VERSION ""

NS_ :

BS_:

BU_: VCU_LE CHUD_LE VKM_LE RCRM_LE VPM_LE EDI_LE V2V_LE TCP_LE CSM_LE UHP_Low_LE TouchPad_LE RSE_LE RSC_LE RSA_LE PDIM_LE OTIM_LE ICS_LE LVMPC_LE LVMNav_LE DVB_T_LE ONSTAR_LE HUD_LE IPC_LE RadioHead_LE CHM_LE Dummy_LE CGM_LE AMP_LE

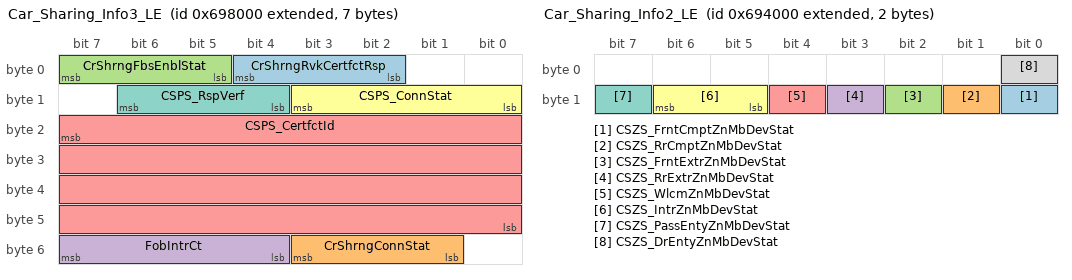
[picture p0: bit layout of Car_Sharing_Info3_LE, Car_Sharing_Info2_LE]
BO_ 2154397696 Car_Sharing_Info3_LE: 7 CGM_LE
 SG_ CrShrngRvkCertfctRsp : 4|3@0+ (1,0) [0|7] ""  TCP_LE,ONSTAR_LE
 SG_ CrShrngConnStat : 51|3@0+ (1,0) [0|7] ""  VKM_LE
 SG_ CrShrngFbsEnblStat : 7|3@0+ (1,0) [0|7] ""  VKM_LE,TCP_LE,ONSTAR_LE
 SG_ FobIntrCt : 55|4@0+ (1,0) [0|15] ""  TCP_LE,ONSTAR_LE
 SG_ CSPS_CertfctId : 23|32@0+ (1,0) [0|4294967295] ""  VKM_LE
 SG_ CSPS_ConnStat : 11|4@0+ (1,0) [0|15] ""  VKM_LE
 SG_ CSPS_RspVerf : 14|3@0+ (1,0) [0|7] ""  VKM_LE

BO_ 2154553344 Car_sharing_Encrypt_Secrt_Rsp_LE: 8 VKM_LE
 SG_ CrShrngEncrpScrtRsp : 7|64@0+ (1,0) [0|1.84467440737096E+019] ""  CGM_LE

BO_ 2154536960 Car_sharing_Encrypt_Secret_LE: 8 CGM_LE
 SG_ CrShrngEncrpScrt : 7|64@0+ (1,0) [0|1.84467440737096E+019] ""  VKM_LE

BO_ 2154545152 Car_Shar_Intrmdt_CA_Cert_Rsp_LE: 8 CGM_LE
 SG_ CrShrgIntCtftAthrtyCtftRp : 7|64@0+ (1,0) [0|1.84467440737096E+019] ""  VKM_LE

BO_ 2154520576 Car_Sharing_Intrmdt_CA_Cert_LE: 8 VKM_LE
 SG_ CrShrgIntCtftAthrtyCtft : 7|64@0+ (1,0) [0|1.84467440737096E+019] ""  CGM_LE

BO_ 2154504192 Car_Sharing_User_Cert_Resp_LE: 8 CGM_LE
 SG_ CrShrngUsrCertfctRsp : 7|64@0+ (1,0) [0|1.84467440737096E+019] ""  VKM_LE

BO_ 2154479616 Car_Sharing_User_Cert_LE: 8 VKM_LE
 SG_ CrShrngUsrCertfct : 7|64@0+ (1,0) [0|1.84467440737096E+019] ""  CGM_LE

BO_ 2154381312 Car_Sharing_Info2_LE: 2 VKM_LE
 SG_ CSZS_FrntCmptZnMbDevStat : 8|1@0+ (1,0) [0|1] ""  CGM_LE
 SG_ CSZS_RrCmptZnMbDevStat : 9|1@0+ (1,0) [0|1] ""  CGM_LE
 SG_ CSZS_FrntExtrZnMbDevStat : 10|1@0+ (1,0) [0|1] ""  CGM_LE
 SG_ CSZS_RrExtrZnMbDevStat : 11|1@0+ (1,0) [0|1] ""  CGM_LE
 SG_ CSZS_WlcmZnMbDevStat : 12|1@0+ (1,0) [0|1] ""  CGM_LE
 SG_ CSZS_IntrZnMbDevStat : 14|2@0+ (1,0) [0|3] ""  CGM_LE
 SG_ CSZS_PassEntyZnMbDevStat : 15|1@0+ (1,0) [0|1] ""  CGM_LE
 SG_ CSZS_DrEntyZnMbDevStat : 0|1@0+ (1,0) [0|1] ""  CGM_LE

BO_ 2150121472 Remote_Trailer_Lighting_Req_LE: 1 TCP_LE
 SG_ RmtTrlrLtngSeqReq : 7|2@0+ (1,0) [0|3] ""  CGM_LE

BO_ 2150547456 HMI_Hybrid_Vehicle_Status_LE: 8 CGM_LE
 SG_ HVDpltnMdCnfdcTrndg : 47|8@0- (0.787402,0) [-100.787456|100.000054] "%"  CSM_LE,ONSTAR_LE,VCU_LE,IPC_LE
 SG_ OffBrdHVCVehPwrLvl : 55|2@0+ (1,0) [0|3] ""  VCU_LE,CSM_LE,RadioHead_LE
 SG_ OffBrdHVCVehPwrDrtd : 26|1@0+ (1,0) [0|1] ""  VCU_LE,CSM_LE,RadioHead_LE
 SG_ OffBrdHVCVehCplrLkd : 16|1@0+ (1,0) [0|1] ""  VCU_LE,CSM_LE,RadioHead_LE
 SG_ OffBrdHVBlkChrgCmp : 37|1@0+ (1,0) [0|1] ""  CSM_LE,ONSTAR_LE,VCU_LE,IPC_LE
 SG_ OBHVBCCT_MinofHr : 61|6@0+ (1,0) [0|63] ""  CSM_LE,RadioHead_LE,VCU_LE,IPC_LE
 SG_ OBHVBCCT_HrofDay : 50|5@0+ (1,0) [0|31] ""  CSM_LE,RadioHead_LE,VCU_LE,IPC_LE
 SG_ OBHVBCCT_DayofWk : 53|3@0+ (1,0) [0|7] ""  CSM_LE,RadioHead_LE,VCU_LE,IPC_LE
 SG_ ElecPrplsnMtrOvrSpdIO : 38|1@0+ (1,0) [0|1] ""  VCU_LE,IPC_LE
 SG_ HVBatOutOfEnrgyInd : 36|3@0+ (1,0) [0|7] ""  CSM_LE,RadioHead_LE,VCU_LE,IPC_LE
 SG_ CntrsOpnUndrTmpIO : 7|1@0+ (1,0) [0|1] ""  CSM_LE,RadioHead_LE,VCU_LE,IPC_LE
 SG_ HVBatCntctrsOpnIO : 39|1@0+ (1,0) [0|1] ""  CSM_LE,ONSTAR_LE,VCU_LE,IPC_LE
 SG_ GrnAudQueReq : 4|1@0+ (1,0) [0|1] ""  CSM_LE,VCU_LE,RadioHead_LE
 SG_ SvcHybChrgSysIO : 5|1@0+ (1,0) [0|1] ""  CSM_LE,RadioHead_LE,VCU_LE,IPC_LE
 SG_ HVChrgrSysStat : 29|3@0+ (1,0) [0|7] ""  TCP_LE,ONSTAR_LE,CSM_LE,RadioHead_LE,VCU_LE,IPC_LE
 SG_ HVChrgrCplrStat : 31|2@0+ (1,0) [0|3] ""  CSM_LE,TCP_LE,ONSTAR_LE,VCU_LE,RadioHead_LE
 SG_ HVBatLimDTmpInd : 25|2@0+ (1,0) [0|3] ""  CSM_LE,RadioHead_LE,VCU_LE,IPC_LE
 SG_ HVBatChrgCrdConnIO : 6|1@0+ (1,0) [0|1] ""  CSM_LE,TCP_LE,ONSTAR_LE,RadioHead_LE,VCU_LE,IPC_LE
 SG_ VehChrgMdSt : 3|3@0+ (1,0) [0|7] ""  CSM_LE,TCP_LE,ONSTAR_LE,RadioHead_LE,VCU_LE,IPC_LE
 SG_ HVDpltnMdRng : 0|16@0+ (0.015625,0) [0|1023.984375] "km"  TCP_LE,ONSTAR_LE,CSM_LE,RadioHead_LE,VCU_LE,IPC_LE
 SG_ ChgrSysAdblIndReq : 33|2@0+ (1,0) [0|3] ""  CSM_LE,VCU_LE,RadioHead_LE

BO_ 2149752832 Chassis_Information_LE: 8 CGM_LE
 SG_ SndEnhcmtPerfMdRq : 55|3@0+ (1,0) [0|7] ""  CSM_LE,RadioHead_LE,VCU_LE,IPC_LE
 SG_ SndPerfMdCsStAvl : 63|1@0+ (1,0) [0|1] ""  VCU_LE,CSM_LE,RadioHead_LE
 SG_ SndPerfMdCsCrStVal : 62|3@0+ (1,0) [0|7] ""  VCU_LE,CSM_LE,RadioHead_LE
 SG_ DispPerfMdCsStAvl : 59|1@0+ (1,0) [0|1] ""  VCU_LE,CSM_LE,RadioHead_LE
 SG_ DispPerfMdCsCrStVal : 58|3@0+ (1,0) [0|7] ""  VCU_LE,CSM_LE,RadioHead_LE
 SG_ HlStrAssActIO : 41|1@0+ (1,0) [0|1] ""  CSM_LE,RadioHead_LE,VCU_LE,IPC_LE
 SG_ GNCustSetngAvlbl : 44|1@0+ (1,0) [0|1] ""  CSM_LE,RadioHead_LE,VCU_LE,IPC_LE
 SG_ GNCustCrntStngVal : 47|3@0+ (1,0) [0|7] ""  CSM_LE,RadioHead_LE,VCU_LE,IPC_LE
 SG_ CPSInfotmntMtReq : 49|2@0+ (1,0) [0|3] ""  CSM_LE,VCU_LE,RadioHead_LE
 SG_ ColPrSysStngAvl : 42|1@0+ (1,0) [0|1] ""  VCU_LE,CSM_LE,RadioHead_LE
 SG_ ColPrSysCrntStng : 52|3@0+ (1,0) [0|7] ""  VCU_LE,CSM_LE,RadioHead_LE
 SG_ HillDscntCntlSysStat : 37|3@0+ (1,0) [0|7] ""  CSM_LE,RadioHead_LE,VCU_LE,IPC_LE
 SG_ ElecPrkBrkStat : 39|2@0+ (1,0) [0|3] ""  V2V_LE,ONSTAR_LE,TCP_LE,CSM_LE,VCU_LE,RadioHead_LE,LVMNav_LE
 SG_ EBDFailed : 31|1@0+ (1,0) [0|1] ""  CSM_LE,RadioHead_LE,VCU_LE,IPC_LE
 SG_ SusCustStngAvlbl : 30|1@0+ (1,0) [0|1] ""  VCU_LE,CSM_LE,RadioHead_LE
 SG_ SusCustCurrStngVal : 34|3@0+ (1,0) [0|7] ""  VCU_LE,CSM_LE,RadioHead_LE
 SG_ StrCustStngAvlbl : 7|1@0+ (1,0) [0|1] ""  VCU_LE,CSM_LE,RadioHead_LE
 SG_ StrCustCurrStngVal : 29|3@0+ (1,0) [0|7] ""  VCU_LE,CSM_LE,RadioHead_LE
 SG_ DrvlnCustStngAvlbl : 6|1@0+ (1,0) [0|1] ""  VCU_LE,CSM_LE,RadioHead_LE
 SG_ DrvlnCustCurrStngVal : 26|3@0+ (1,0) [0|7] ""  VCU_LE,CSM_LE,RadioHead_LE
 SG_ ABSAtv : 5|1@0+ (1,0) [0|1] ""  CSM_LE,RadioHead_LE,VCU_LE,IPC_LE
 SG_ PowStVDA : 13|1@0+ (1,0) [0|1] ""  CSM_LE,RadioHead_LE,VCU_LE,IPC_LE
 SG_ RrDrCntVDA : 14|1@0+ (1,0) [0|1] ""  CSM_LE,RadioHead_LE,VCU_LE,IPC_LE
 SG_ SprTireSt : 18|3@0+ (1,0) [0|7] ""  VPM_LE,CSM_LE,VCU_LE,RadioHead_LE
 SG_ VehHghtStatV : 0|1@0+ (1,0) [0|1] ""  VPM_LE,CSM_LE,RadioHead_LE,VCU_LE,IPC_LE
 SG_ VehHghtStat : 11|4@0+ (1,0) [0|15] ""  VPM_LE,CSM_LE,RadioHead_LE,VCU_LE,IPC_LE
 SG_ BrkSysVDA : 15|1@0+ (1,0) [0|1] ""  CSM_LE,TCP_LE,ONSTAR_LE,RadioHead_LE,VCU_LE,IPC_LE
 SG_ IntBrkAssPreFilReq : 1|1@0+ (1,0) [0|1] "N/A"  CSM_LE,RadioHead_LE,VCU_LE,IPC_LE
 SG_ EPBSysDspMsgReq : 23|3@0+ (1,0) [0|7] ""  CSM_LE,RadioHead_LE,VCU_LE,IPC_LE
 SG_ EPBSysAudWarnReq : 20|2@0+ (1,0) [0|3] ""  CSM_LE,RadioHead_LE,VCU_LE,IPC_LE
 SG_ BksOvht : 2|1@0+ (1,0) [0|1] ""  CSM_LE,TCP_LE,ONSTAR_LE,RadioHead_LE,VCU_LE,IPC_LE
 SG_ BrkSysRedBrkTlltlReq : 4|1@0+ (1,0) [0|1] ""  CSM_LE,RadioHead_LE,VCU_LE,IPC_LE
 SG_ HalfSysFail : 3|1@0+ (1,0) [0|1] ""  CSM_LE,RadioHead_LE,VCU_LE,IPC_LE
 SG_ PrkBrkVDA : 12|1@0+ (1,0) [0|1] ""  CSM_LE,RadioHead_LE,VCU_LE,IPC_LE

BO_ 2156216320 TTY_Status_LE: 1 OTIM_LE
 SG_ TxtTelephoneDevPr : 0|1@0+ (1,0) [0|1] ""  TCP_LE,ONSTAR_LE

BO_ 2158002176 XM_Radio_Service_LE: 1 RadioHead_LE
 SG_ SrvcPrvdr : 5|3@0+ (1,0) [0|7] ""  ONSTAR_LE
 SG_ CurntStnServc : 2|3@0+ (1,0) [0|7] ""  ONSTAR_LE

BO_ 2156838912 WiFi_Station_LE: 7 RadioHead_LE
 SG_ WSR_WiFiStnMACAddr : 15|48@0+ (1,0) [0|281474976710655] ""  ONSTAR_LE
 SG_ WSR_WiFiAssnStat : 3|4@0+ (1,0) [0|15] ""  ONSTAR_LE

BO_ 2156937216 PassPhrase_Digits_17_to_24_LE: 8 ONSTAR_LE
 SG_ WiFiPssPhrsDgts17to24 : 7|64@0+ (1,0) [0|0] ""  CSM_LE,VCU_LE,RadioHead_LE

BO_ 2156929024 PassPhrase_Digits_9_to_16_LE: 8 ONSTAR_LE
 SG_ WiFiPssPhrsDgts9to16 : 7|64@0+ (1,0) [0|0] ""  CSM_LE,VCU_LE,RadioHead_LE

BO_ 2156920832 PassPhrase_Digits_1_to_8_LE: 8 ONSTAR_LE
 SG_ WiFiPssPhrsDgts1to8 : 7|64@0+ (1,0) [0|0] ""  CSM_LE,VCU_LE,RadioHead_LE

BO_ 2156871680 SSID_Digits_17_to_24_LE: 8 ONSTAR_LE
 SG_ WiFiSSIDDgts17to24 : 7|64@0+ (1,0) [0|0] ""  VCU_LE,RadioHead_LE

BO_ 2156863488 SSID_Digits_9_to_16_LE: 8 ONSTAR_LE
 SG_ WiFiSSIDDgts9to16 : 7|64@0+ (1,0) [0|0] ""  VCU_LE,RadioHead_LE

BO_ 2156855296 SSID_Digits_1_to_8_LE: 8 ONSTAR_LE
 SG_ WiFiSSIDDgts1to8 : 7|64@0+ (1,0) [0|0] ""  VCU_LE,RadioHead_LE

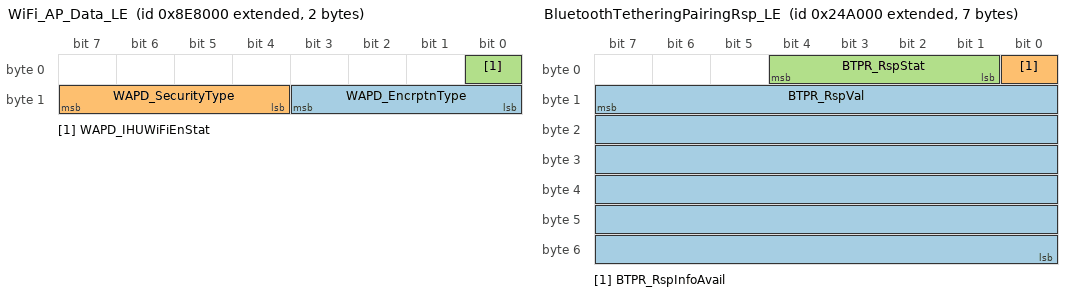
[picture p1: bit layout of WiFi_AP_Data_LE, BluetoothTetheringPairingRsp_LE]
BO_ 2156822528 WiFi_AP_Data_LE: 2 ONSTAR_LE
 SG_ WAPD_EncrptnType : 11|4@0+ (1,0) [0|15] ""  VCU_LE,RadioHead_LE
 SG_ WAPD_SecurityType : 15|4@0+ (1,0) [0|15] ""  VCU_LE,RadioHead_LE
 SG_ WAPD_IHUWiFiEnStat : 0|1@0+ (1,0) [0|1] ""  VCU_LE,RadioHead_LE

BO_ 2149883904 BluetoothTetheringPairingRsp_LE: 7 RadioHead_LE
 SG_ BTPR_RspVal : 15|48@0+ (1,0) [0|281474976710655] ""  ONSTAR_LE
 SG_ BTPR_RspInfoAvail : 0|1@0+ (1,0) [0|1] ""  ONSTAR_LE
 SG_ BTPR_RspStat : 4|4@0+ (1,0) [0|15] ""  ONSTAR_LE

BO_ 2152038400 Infomatics_Response_Payload_LE: 8 ONSTAR_LE
 SG_ InfMdRspPld : 7|64@0+ (1,0) [0|1.84467440737096E+019] ""  VCU_LE,RadioHead_LE

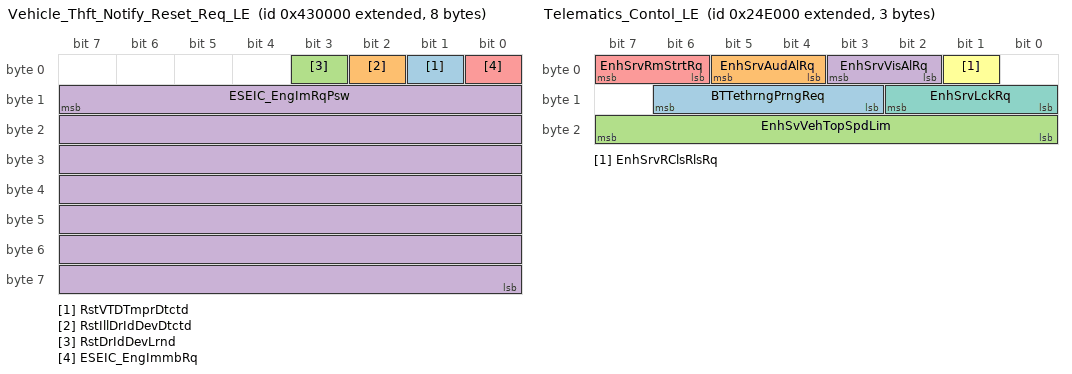
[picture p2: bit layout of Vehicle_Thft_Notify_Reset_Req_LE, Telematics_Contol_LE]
BO_ 2151874560 Vehicle_Thft_Notify_Reset_Req_LE: 8 ONSTAR_LE
 SG_ RstVTDTmprDtctd : 1|1@0+ (1,0) [0|1] ""  CGM_LE
 SG_ RstIllDrIdDevDtctd : 2|1@0+ (1,0) [0|1] ""  CGM_LE
 SG_ RstDrIdDevLrnd : 3|1@0+ (1,0) [0|1] ""  CGM_LE
 SG_ ESEIC_EngImRqPsw : 15|56@0+ (1,0) [0|1] ""  CGM_LE
 SG_ ESEIC_EngImmbRq : 0|1@0+ (1,0) [0|1] ""  CGM_LE

BO_ 2151383040 Reset_TP_request_LE: 1 IPC_LE
 SG_ TreInfMonSysRstReq : 0|1@0+ (1,0) [0|1] ""  CGM_LE

BO_ 2149900288 Telematics_Contol_LE: 3 ONSTAR_LE
 SG_ BTTethrngPrngReq : 14|4@0+ (1,0) [0|15] ""  VCU_LE,RadioHead_LE,CGM_LE
 SG_ EnhSrvAudAlRq : 5|2@0+ (1,0) [0|3] ""  CGM_LE
 SG_ EnhSvVehTopSpdLim : 23|8@0+ (2,0) [0|510] "km / h"  CGM_LE
 SG_ EnhSrvVisAlRq : 3|2@0+ (1,0) [0|3] ""  CGM_LE
 SG_ EnhSrvRmStrtRq : 7|2@0+ (1,0) [0|3] ""  CGM_LE
 SG_ EnhSrvRClsRlsRq : 1|1@0+ (1,0) [0|1] ""  CGM_LE
 SG_ EnhSrvLckRq : 10|3@0+ (1,0) [0|7] ""  CGM_LE

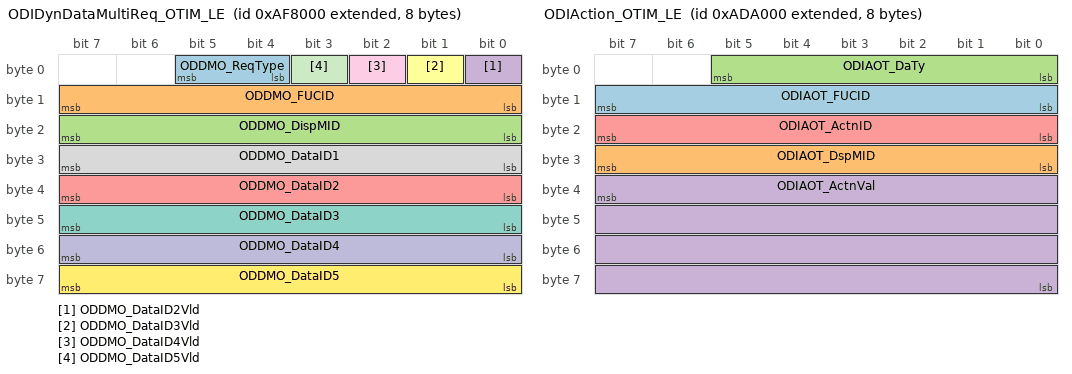
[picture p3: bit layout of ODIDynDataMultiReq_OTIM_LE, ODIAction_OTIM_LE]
BO_ 2158985216 ODIDynDataMultiReq_OTIM_LE: 8 OTIM_LE
 SG_ ODDMO_ReqType : 5|2@0+ (1,0) [0|3] ""  TCP_LE,ONSTAR_LE
 SG_ ODDMO_FUCID : 15|8@0+ (1,0) [0|255] ""  TCP_LE,ONSTAR_LE
 SG_ ODDMO_DispMID : 23|8@0+ (1,0) [0|255] ""  TCP_LE,ONSTAR_LE
 SG_ ODDMO_DataID2Vld : 0|1@0+ (1,0) [0|1] ""  TCP_LE,ONSTAR_LE
 SG_ ODDMO_DataID2 : 39|8@0+ (1,0) [0|255] ""  TCP_LE,ONSTAR_LE
 SG_ ODDMO_DataID3Vld : 1|1@0+ (1,0) [0|1] ""  TCP_LE,ONSTAR_LE
 SG_ ODDMO_DataID3 : 47|8@0+ (1,0) [0|255] ""  TCP_LE,ONSTAR_LE
 SG_ ODDMO_DataID1 : 31|8@0+ (1,0) [0|255] ""  TCP_LE,ONSTAR_LE
 SG_ ODDMO_DataID4Vld : 2|1@0+ (1,0) [0|1] ""  TCP_LE,ONSTAR_LE
 SG_ ODDMO_DataID4 : 55|8@0+ (1,0) [0|255] ""  TCP_LE,ONSTAR_LE
 SG_ ODDMO_DataID5Vld : 3|1@0+ (1,0) [0|1] ""  TCP_LE,ONSTAR_LE
 SG_ ODDMO_DataID5 : 63|8@0+ (1,0) [0|255] ""  TCP_LE,ONSTAR_LE

BO_ 2158862336 ODIAction_OTIM_LE: 8 OTIM_LE
 SG_ ODIAOT_FUCID : 15|8@0+ (1,0) [0|255] ""  TCP_LE,ONSTAR_LE
 SG_ ODIAOT_DspMID : 31|8@0+ (1,0) [0|255] ""  TCP_LE,ONSTAR_LE
 SG_ ODIAOT_DaTy : 5|6@0+ (1,0) [0|63] ""  TCP_LE,ONSTAR_LE
 SG_ ODIAOT_ActnVal : 39|32@0+ (1,0) [0|4294967295] ""  TCP_LE,ONSTAR_LE
 SG_ ODIAOT_ActnID : 23|8@0+ (1,0) [0|255] ""  TCP_LE,ONSTAR_LE

BO_ 2159157248 ODI_CenterStack_2_TEL_LE: 8 RadioHead_LE
 SG_ ODI_CntrStck2TEL : 7|64@0+ (1,0) [0|1.84467440737096E+019] ""  UHP_Low_LE,ONSTAR_LE,TCP_LE

BO_ 2159091712 ODI_IPC_2_TEL_LE: 8 IPC_LE
 SG_ ODI_IPC2TEL : 7|64@0+ (1,0) [0|1.84467440737096E+019] ""  UHP_Low_LE,ONSTAR_LE,TCP_LE,CSM_LE,VCU_LE,RadioHead_LE

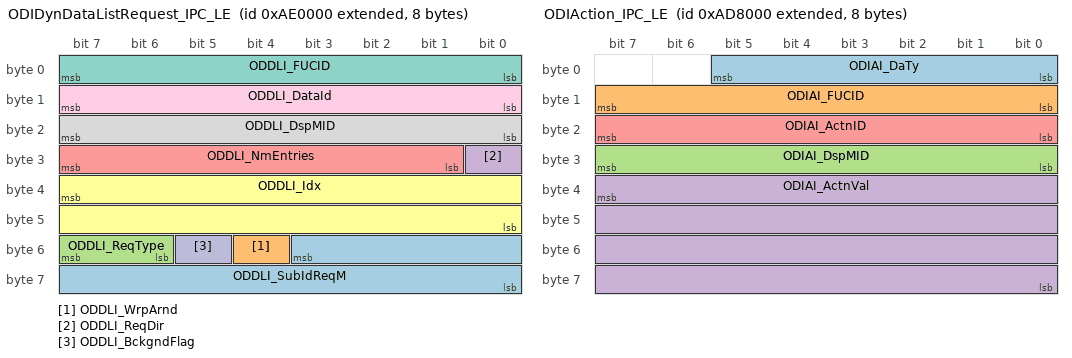
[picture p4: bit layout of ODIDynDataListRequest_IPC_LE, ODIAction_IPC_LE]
BO_ 2158886912 ODIDynDataListRequest_IPC_LE: 8 IPC_LE
 SG_ ODDLI_SubIdReqM : 51|12@0+ (1,0) [0|4095] ""  CSM_LE,CGM_LE,UHP_Low_LE,ONSTAR_LE,VCU_LE,RadioHead_LE,TCP_LE
 SG_ ODDLI_WrpArnd : 52|1@0+ (1,0) [0|1] ""  CSM_LE,CGM_LE,UHP_Low_LE,ONSTAR_LE,VCU_LE,RadioHead_LE,TCP_LE
 SG_ ODDLI_ReqType : 55|2@0+ (1,0) [0|3] ""  CSM_LE,CGM_LE,UHP_Low_LE,ONSTAR_LE,VCU_LE,RadioHead_LE,TCP_LE
 SG_ ODDLI_ReqDir : 24|1@0+ (1,0) [0|1] ""  CSM_LE,CGM_LE,UHP_Low_LE,ONSTAR_LE,VCU_LE,RadioHead_LE,TCP_LE
 SG_ ODDLI_NmEntries : 31|7@0+ (1,0) [0|127] ""  CSM_LE,CGM_LE,UHP_Low_LE,ONSTAR_LE,VCU_LE,RadioHead_LE,TCP_LE
 SG_ ODDLI_Idx : 39|16@0+ (1,0) [0|65535] ""  CSM_LE,CGM_LE,UHP_Low_LE,ONSTAR_LE,VCU_LE,RadioHead_LE,TCP_LE
 SG_ ODDLI_FUCID : 7|8@0+ (1,0) [0|255] ""  CSM_LE,CGM_LE,UHP_Low_LE,ONSTAR_LE,VCU_LE,RadioHead_LE,TCP_LE
 SG_ ODDLI_DspMID : 23|8@0+ (1,0) [0|255] ""  CSM_LE,CGM_LE,UHP_Low_LE,ONSTAR_LE,VCU_LE,RadioHead_LE,TCP_LE
 SG_ ODDLI_DataId : 15|8@0+ (1,0) [0|255] ""  CSM_LE,CGM_LE,UHP_Low_LE,ONSTAR_LE,VCU_LE,RadioHead_LE,TCP_LE
 SG_ ODDLI_BckgndFlag : 53|1@0+ (1,0) [0|1] ""  CSM_LE,CGM_LE,UHP_Low_LE,ONSTAR_LE,VCU_LE,RadioHead_LE,TCP_LE

BO_ 2158854144 ODIAction_IPC_LE: 8 IPC_LE
 SG_ ODIAI_DaTy : 5|6@0+ (1,0) [0|63] ""  CSM_LE,CGM_LE,UHP_Low_LE,ONSTAR_LE,VCU_LE,RadioHead_LE,TCP_LE
 SG_ ODIAI_FUCID : 15|8@0+ (1,0) [0|255] ""  CSM_LE,CGM_LE,UHP_Low_LE,ONSTAR_LE,VCU_LE,RadioHead_LE,TCP_LE
 SG_ ODIAI_DspMID : 31|8@0+ (1,0) [0|255] ""  CSM_LE,CGM_LE,UHP_Low_LE,ONSTAR_LE,VCU_LE,RadioHead_LE,TCP_LE
 SG_ ODIAI_ActnVal : 39|32@0+ (1,0) [0|4294967295] ""  CSM_LE,CGM_LE,UHP_Low_LE,ONSTAR_LE,VCU_LE,RadioHead_LE,TCP_LE
 SG_ ODIAI_ActnID : 23|8@0+ (1,0) [0|255] ""  CSM_LE,CGM_LE,UHP_Low_LE,ONSTAR_LE,VCU_LE,RadioHead_LE,TCP_LE

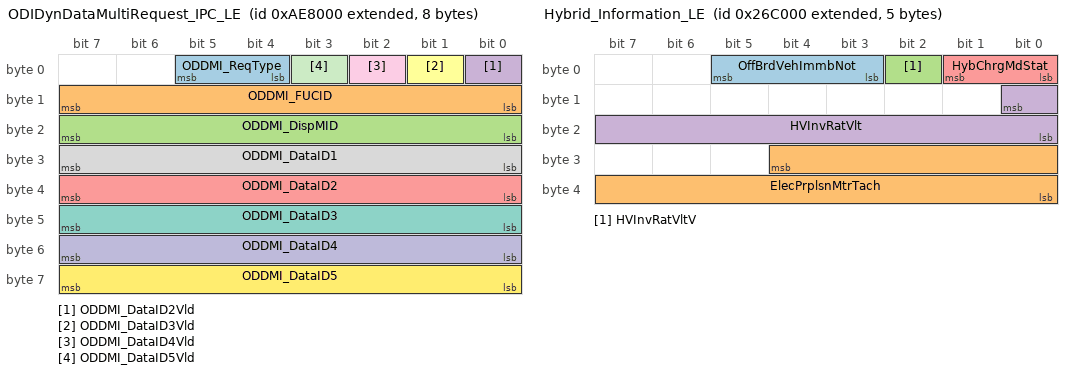
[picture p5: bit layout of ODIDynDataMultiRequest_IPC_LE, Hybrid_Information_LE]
BO_ 2158919680 ODIDynDataMultiRequest_IPC_LE: 8 IPC_LE
 SG_ ODDMI_ReqType : 5|2@0+ (1,0) [0|3] ""  CSM_LE,CGM_LE,UHP_Low_LE,ONSTAR_LE,VCU_LE,RadioHead_LE,TCP_LE
 SG_ ODDMI_FUCID : 15|8@0+ (1,0) [0|255] ""  CSM_LE,CGM_LE,UHP_Low_LE,ONSTAR_LE,VCU_LE,RadioHead_LE,TCP_LE
 SG_ ODDMI_DispMID : 23|8@0+ (1,0) [0|255] ""  CSM_LE,CGM_LE,UHP_Low_LE,ONSTAR_LE,VCU_LE,RadioHead_LE,TCP_LE
 SG_ ODDMI_DataID2Vld : 0|1@0+ (1,0) [0|1] ""  CSM_LE,CGM_LE,UHP_Low_LE,ONSTAR_LE,VCU_LE,RadioHead_LE,TCP_LE
 SG_ ODDMI_DataID2 : 39|8@0+ (1,0) [0|255] ""  CSM_LE,CGM_LE,UHP_Low_LE,ONSTAR_LE,VCU_LE,RadioHead_LE,TCP_LE
 SG_ ODDMI_DataID3Vld : 1|1@0+ (1,0) [0|1] ""  CSM_LE,CGM_LE,UHP_Low_LE,ONSTAR_LE,VCU_LE,RadioHead_LE,TCP_LE
 SG_ ODDMI_DataID3 : 47|8@0+ (1,0) [0|255] ""  CSM_LE,CGM_LE,UHP_Low_LE,ONSTAR_LE,VCU_LE,RadioHead_LE,TCP_LE
 SG_ ODDMI_DataID1 : 31|8@0+ (1,0) [0|255] ""  CSM_LE,CGM_LE,UHP_Low_LE,ONSTAR_LE,VCU_LE,RadioHead_LE,TCP_LE
 SG_ ODDMI_DataID4Vld : 2|1@0+ (1,0) [0|1] ""  CSM_LE,CGM_LE,UHP_Low_LE,ONSTAR_LE,VCU_LE,RadioHead_LE,TCP_LE
 SG_ ODDMI_DataID4 : 55|8@0+ (1,0) [0|255] ""  CSM_LE,CGM_LE,UHP_Low_LE,ONSTAR_LE,VCU_LE,RadioHead_LE,TCP_LE
 SG_ ODDMI_DataID5Vld : 3|1@0+ (1,0) [0|1] ""  CSM_LE,CGM_LE,UHP_Low_LE,ONSTAR_LE,VCU_LE,RadioHead_LE,TCP_LE
 SG_ ODDMI_DataID5 : 63|8@0+ (1,0) [0|255] ""  CSM_LE,CGM_LE,UHP_Low_LE,ONSTAR_LE,VCU_LE,RadioHead_LE,TCP_LE

BO_ 2150023168 Hybrid_Information_LE: 5 CGM_LE
 SG_ OffBrdVehImmbNot : 5|3@0+ (1,0) [0|7] ""  TCP_LE,ONSTAR_LE
 SG_ ElecPrplsnMtrTach : 28|13@0+ (1,0) [0|8191] "rpm"  CSM_LE,RadioHead_LE,VCU_LE,IPC_LE
 SG_ HVInvRatVltV : 2|1@0+ (1,0) [0|1] ""  CSM_LE,VCU_LE,RadioHead_LE
 SG_ HVInvRatVlt : 8|9@0+ (1,0) [0|511] "volts"  CSM_LE,VCU_LE,RadioHead_LE
 SG_ HybChrgMdStat : 1|2@0+ (1,0) [0|3] ""  CSM_LE,RadioHead_LE,VCU_LE,IPC_LE

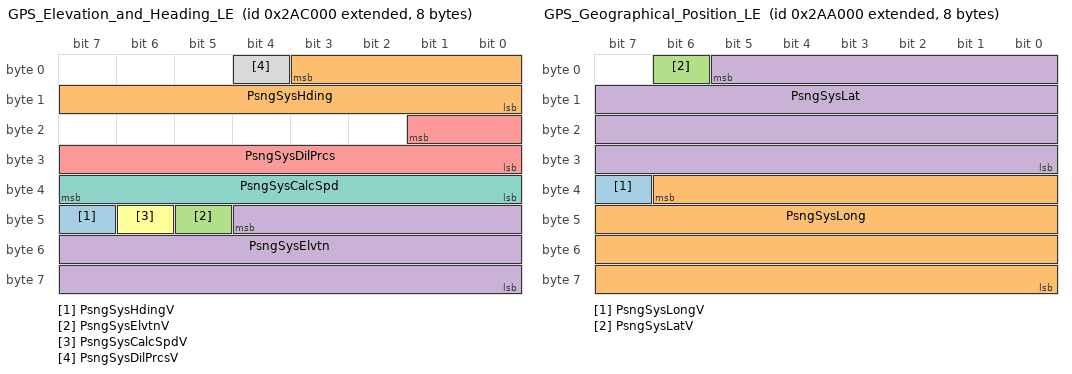
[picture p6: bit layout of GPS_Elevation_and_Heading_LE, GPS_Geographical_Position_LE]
BO_ 2150285312 GPS_Elevation_and_Heading_LE: 8 RadioHead_LE
 SG_ PsngSysHdingV : 47|1@0+ (1,0) [0|1] ""  EDI_LE,V2V_LE,CGM_LE,CSM_LE,VCU_LE,RadioHead_LE
 SG_ PsngSysHding : 3|12@0+ (0.1,0) [0|409.5] "deg"  EDI_LE,V2V_LE,CGM_LE,CSM_LE,VCU_LE,RadioHead_LE
 SG_ PsngSysElvtnV : 45|1@0+ (1,0) [0|1] ""  EDI_LE,V2V_LE,CGM_LE,CSM_LE,VCU_LE,RadioHead_LE
 SG_ PsngSysElvtn : 44|21@0+ (1,-100000) [-100000|1997151] "cm"  EDI_LE,V2V_LE,CGM_LE,CSM_LE,VCU_LE,RadioHead_LE
 SG_ PsngSysDilPrcs : 17|10@0+ (0.1,0) [0|102.3] ""  EDI_LE,V2V_LE,CGM_LE,CSM_LE,VCU_LE,RadioHead_LE
 SG_ PsngSysCalcSpdV : 46|1@0+ (1,0) [0|1] ""  EDI_LE,V2V_LE,CGM_LE,CSM_LE,VCU_LE,RadioHead_LE
 SG_ PsngSysCalcSpd : 39|8@0+ (1,0) [0|255] "km / h"  EDI_LE,V2V_LE,CGM_LE,CSM_LE,VCU_LE,RadioHead_LE
 SG_ PsngSysDilPrcsV : 4|1@0+ (1,0) [0|1] ""  EDI_LE,V2V_LE,CGM_LE,CSM_LE,VCU_LE,RadioHead_LE

BO_ 2150277120 GPS_Geographical_Position_LE: 8 RadioHead_LE
 SG_ PsngSysLongV : 39|1@0+ (1,0) [0|1] ""  VKM_LE,EDI_LE,V2V_LE,CGM_LE,CSM_LE,VCU_LE,RadioHead_LE
 SG_ PsngSysLong : 38|31@0- (1,0) [-1073741824|1073741823] "ms arc"  VKM_LE,EDI_LE,V2V_LE,CGM_LE,CSM_LE,VCU_LE,RadioHead_LE
 SG_ PsngSysLatV : 6|1@0+ (1,0) [0|1] ""  VKM_LE,EDI_LE,V2V_LE,CGM_LE,CSM_LE,VCU_LE,RadioHead_LE
 SG_ PsngSysLat : 5|30@0- (1,0) [-536870912|536870911] "ms arc"  VKM_LE,EDI_LE,V2V_LE,CGM_LE,CSM_LE,VCU_LE,RadioHead_LE

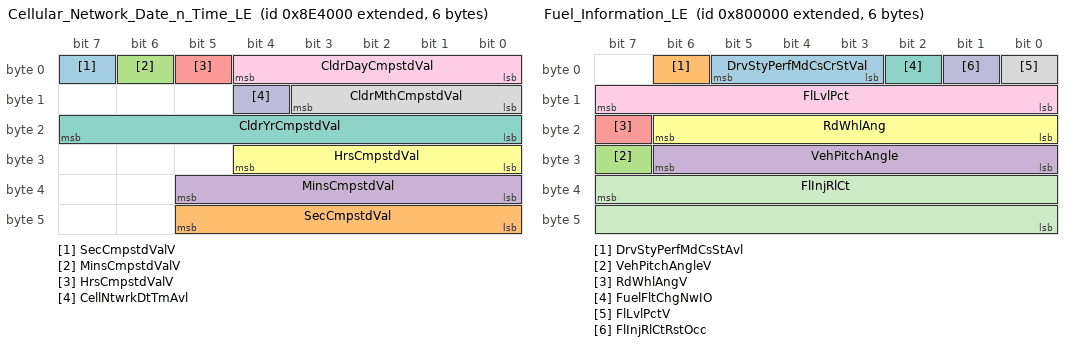
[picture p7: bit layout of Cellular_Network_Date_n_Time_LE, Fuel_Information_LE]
BO_ 2156806144 Cellular_Network_Date_n_Time_LE: 6 ONSTAR_LE
 SG_ SecCmpstdValV : 7|1@0+ (1,0) [0|1] ""  CGM_LE,VCU_LE,CSM_LE,RadioHead_LE
 SG_ SecCmpstdVal : 45|6@0+ (1,0) [0|63] "secs"  CGM_LE,VCU_LE,CSM_LE,RadioHead_LE
 SG_ MinsCmpstdValV : 6|1@0+ (1,0) [0|1] ""  CGM_LE,VCU_LE,CSM_LE,RadioHead_LE
 SG_ MinsCmpstdVal : 37|6@0+ (1,0) [0|63] "min"  CGM_LE,VCU_LE,CSM_LE,RadioHead_LE
 SG_ HrsCmpstdValV : 5|1@0+ (1,0) [0|1] ""  CGM_LE,VCU_LE,CSM_LE,RadioHead_LE
 SG_ HrsCmpstdVal : 28|5@0+ (1,0) [0|31] "h"  CGM_LE,VCU_LE,CSM_LE,RadioHead_LE
 SG_ CldrYrCmpstdVal : 23|8@0+ (1,2000) [2000|2255] "year"  CGM_LE,VCU_LE,CSM_LE,RadioHead_LE
 SG_ CldrMthCmpstdVal : 11|4@0+ (1,0) [0|15] ""  CGM_LE,VCU_LE,CSM_LE,RadioHead_LE
 SG_ CldrDayCmpstdVal : 4|5@0+ (1,0) [0|31] "days"  CGM_LE,VCU_LE,CSM_LE,RadioHead_LE
 SG_ CellNtwrkDtTmAvl : 12|1@0+ (1,0) [0|1] ""  CGM_LE,VCU_LE,CSM_LE,RadioHead_LE

BO_ 2151514112 Reset_OilLife_Request_LE: 1 IPC_LE
 SG_ EngOilLfRstRq : 0|1@0+ (1,0) [0|1] ""  CGM_LE

BO_ 2154561536 Vehicle_Odo_LE: 5 CGM_LE
 SG_ VehOdoV : 32|1@0+ (1,0) [0|1] ""  TCP_LE,ONSTAR_LE,CSM_LE,LVMNav_LE,RadioHead_LE,VCU_LE,IPC_LE
 SG_ VehOdo : 7|32@0+ (0.015625,0) [0|67108863.984375] "km"  TCP_LE,ONSTAR_LE,CSM_LE,LVMNav_LE,RadioHead_LE,VCU_LE,IPC_LE

BO_ 2155872256 Fuel_Information_LE: 6 CGM_LE
 SG_ DrvStyPerfMdCsCrStVal : 5|3@0+ (1,0) [0|7] ""  VCU_LE,CSM_LE,RadioHead_LE
 SG_ DrvStyPerfMdCsStAvl : 6|1@0+ (1,0) [0|1] ""  VCU_LE,CSM_LE,RadioHead_LE
 SG_ VehPitchAngleV : 31|1@0+ (1,0) [0|1] ""  CSM_LE,RadioHead_LE,VCU_LE,IPC_LE
 SG_ VehPitchAngle : 30|7@0+ (0.703125,-45) [-45|44.296875] "deg"  CSM_LE,RadioHead_LE,VCU_LE,IPC_LE
 SG_ RdWhlAngV : 23|1@0+ (1,0) [0|1] ""  VPM_LE,VCU_LE,IPC_LE
 SG_ RdWhlAng : 22|7@0+ (0.703125,-45) [-45|44.296875] "deg"  VPM_LE,VCU_LE,IPC_LE
 SG_ FuelFltChgNwIO : 2|1@0+ (1,0) [0|1] ""  CSM_LE,RadioHead_LE,VCU_LE,IPC_LE
 SG_ FlLvlPctV : 0|1@0+ (1,0) [0|1] ""  TCP_LE,ONSTAR_LE,LVMNav_LE,CSM_LE,RadioHead_LE,VCU_LE,IPC_LE
 SG_ FlLvlPct : 15|8@0+ (0.392157,0) [0|100.000035] "%"  TCP_LE,ONSTAR_LE,LVMNav_LE,CSM_LE,RadioHead_LE,VCU_LE,IPC_LE
 SG_ FlInjRlCtRstOcc : 1|1@0+ (1,0) [0|1] ""  CSM_LE,RadioHead_LE,VCU_LE,IPC_LE
 SG_ FlInjRlCt : 39|16@0+ (3.05176E-005,0) [0|1.999970916] "liters"  CSM_LE,RadioHead_LE,VCU_LE,IPC_LE

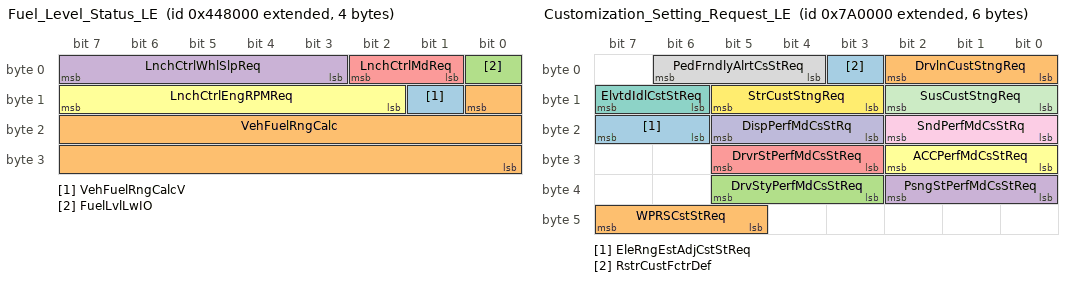
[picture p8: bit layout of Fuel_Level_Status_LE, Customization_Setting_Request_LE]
BO_ 2151972864 Fuel_Level_Status_LE: 4 IPC_LE
 SG_ VehFuelRngCalcV : 9|1@0+ (1,0) [0|1] ""  CGM_LE,VCU_LE,CSM_LE,RadioHead_LE
 SG_ VehFuelRngCalc : 8|17@0+ (0.015625,0) [0|2047.984375] "km"  CGM_LE,VCU_LE,CSM_LE,RadioHead_LE
 SG_ FuelLvlLwIO : 0|1@0+ (1,0) [0|1] ""  CGM_LE,LVMNav_LE,VCU_LE,CSM_LE,RadioHead_LE
 SG_ LnchCtrlWhlSlpReq : 7|5@0+ (1,0) [0|31] ""  CGM_LE
 SG_ LnchCtrlMdReq : 2|2@0+ (1,0) [0|3] ""  CGM_LE
 SG_ LnchCtrlEngRPMReq : 15|6@0+ (1,0) [0|63] ""  CGM_LE

BO_ 2152095744 HSGMLAN_Customization_Setings_LE: 5 CGM_LE
 SG_ SPMCA_SusPrfMd6Avl : 32|1@0+ (1,0) [0|1] ""  VCU_LE,CSM_LE,RadioHead_LE
 SG_ SPMCA_SusPrfMd5Avl : 33|1@0+ (1,0) [0|1] ""  VCU_LE,CSM_LE,RadioHead_LE
 SG_ SPMCA_SusPrfMd4Avl : 34|1@0+ (1,0) [0|1] ""  VCU_LE,CSM_LE,RadioHead_LE
 SG_ SPMCA_SusPrfMd3Avl : 35|1@0+ (1,0) [0|1] ""  VCU_LE,CSM_LE,RadioHead_LE
 SG_ SPMCA_SusPrfMd2Avl : 36|1@0+ (1,0) [0|1] ""  VCU_LE,CSM_LE,RadioHead_LE
 SG_ SPMCA_SusPrfMd1Avl : 37|1@0+ (1,0) [0|1] ""  VCU_LE,CSM_LE,RadioHead_LE
 SG_ SPMCA_StrPrfMd6Avl : 24|1@0+ (1,0) [0|1] ""  VCU_LE,CSM_LE,RadioHead_LE
 SG_ SPMCA_StrPrfMd5Avl : 25|1@0+ (1,0) [0|1] ""  VCU_LE,CSM_LE,RadioHead_LE
 SG_ SPMCA_StrPrfMd4Avl : 26|1@0+ (1,0) [0|1] ""  VCU_LE,CSM_LE,RadioHead_LE
 SG_ SPMCA_StrPrfMd3Avl : 27|1@0+ (1,0) [0|1] ""  VCU_LE,CSM_LE,RadioHead_LE
 SG_ SPMCA_StrPrfMd2Avl : 28|1@0+ (1,0) [0|1] ""  VCU_LE,CSM_LE,RadioHead_LE
 SG_ SPMCA_StrPrfMd1Avl : 29|1@0+ (1,0) [0|1] ""  VCU_LE,CSM_LE,RadioHead_LE
 SG_ SPMCA_SndPrfMd6Avl : 16|1@0+ (1,0) [0|1] ""  VCU_LE,CSM_LE,RadioHead_LE
 SG_ SPMCA_SndPrfMd5Avl : 17|1@0+ (1,0) [0|1] ""  VCU_LE,CSM_LE,RadioHead_LE
 SG_ SPMCA_SndPrfMd4Avl : 18|1@0+ (1,0) [0|1] ""  VCU_LE,CSM_LE,RadioHead_LE
 SG_ SPMCA_SndPrfMd3Avl : 19|1@0+ (1,0) [0|1] ""  VCU_LE,CSM_LE,RadioHead_LE
 SG_ SPMCA_SndPrfMd2Avl : 20|1@0+ (1,0) [0|1] ""  VCU_LE,CSM_LE,RadioHead_LE
 SG_ SPMCA_SndPrfMd1Avl : 21|1@0+ (1,0) [0|1] ""  VCU_LE,CSM_LE,RadioHead_LE
 SG_ DPMCA_DispPrfMd6Avl : 8|1@0+ (1,0) [0|1] ""  VCU_LE,CSM_LE,RadioHead_LE
 SG_ DPMCA_DispPrfMd5Avl : 9|1@0+ (1,0) [0|1] ""  VCU_LE,CSM_LE,RadioHead_LE
 SG_ DPMCA_DispPrfMd4Avl : 10|1@0+ (1,0) [0|1] ""  VCU_LE,CSM_LE,RadioHead_LE
 SG_ DPMCA_DispPrfMd3Avl : 11|1@0+ (1,0) [0|1] ""  VCU_LE,CSM_LE,RadioHead_LE
 SG_ DPMCA_DispPrfMd2Avl : 12|1@0+ (1,0) [0|1] ""  VCU_LE,CSM_LE,RadioHead_LE
 SG_ DPMCA_DispPrfMd1Avl : 13|1@0+ (1,0) [0|1] ""  VCU_LE,CSM_LE,RadioHead_LE
 SG_ DPMCA_DrvlPrfMd6Avl : 0|1@0+ (1,0) [0|1] ""  VCU_LE,CSM_LE,RadioHead_LE
 SG_ DPMCA_DrvlPrfMd5Avl : 1|1@0+ (1,0) [0|1] ""  VCU_LE,CSM_LE,RadioHead_LE
 SG_ DPMCA_DrvlPrfMd4Avl : 2|1@0+ (1,0) [0|1] ""  VCU_LE,CSM_LE,RadioHead_LE
 SG_ DPMCA_DrvlPrfMd3Avl : 3|1@0+ (1,0) [0|1] ""  VCU_LE,CSM_LE,RadioHead_LE
 SG_ DPMCA_DrvlPrfMd2Avl : 4|1@0+ (1,0) [0|1] ""  VCU_LE,CSM_LE,RadioHead_LE
 SG_ DPMCA_DrvlPrfMd1Avl : 5|1@0+ (1,0) [0|1] ""  VCU_LE,CSM_LE,RadioHead_LE

BO_ 2155479040 Customization_Setting_Request_LE: 6 RadioHead_LE
 SG_ EleRngEstAdjCstStReq : 23|2@0+ (1,0) [0|3] ""  CGM_LE
 SG_ WPRSCstStReq : 47|3@0+ (1,0) [0|7] ""  CGM_LE
 SG_ DrvStyPerfMdCsStReq : 37|3@0+ (1,0) [0|7] ""  CGM_LE
 SG_ PsngStPerfMdCsStReq : 34|3@0+ (1,0) [0|7] ""  CGM_LE
 SG_ DrvrStPerfMdCsStReq : 29|3@0+ (1,0) [0|7] ""  CGM_LE
 SG_ ACCPerfMdCsStReq : 26|3@0+ (1,0) [0|7] ""  CGM_LE
 SG_ ElvtdIdlCstStReq : 15|2@0+ (1,0) [0|3] ""  CGM_LE
 SG_ PedFrndlyAlrtCsStReq : 6|3@0+ (1,0) [0|7] ""  CGM_LE
 SG_ SndPerfMdCsStRq : 18|3@0+ (1,0) [0|7] ""  CGM_LE
 SG_ DispPerfMdCsStRq : 21|3@0+ (1,0) [0|7] ""  CGM_LE
 SG_ SusCustStngReq : 10|3@0+ (1,0) [0|7] ""  CGM_LE
 SG_ StrCustStngReq : 13|3@0+ (1,0) [0|7] ""  CGM_LE
 SG_ RstrCustFctrDef : 3|1@0+ (1,0) [0|1] ""  VPM_LE,CGM_LE
 SG_ DrvlnCustStngReq : 2|3@0+ (1,0) [0|7] ""  CGM_LE

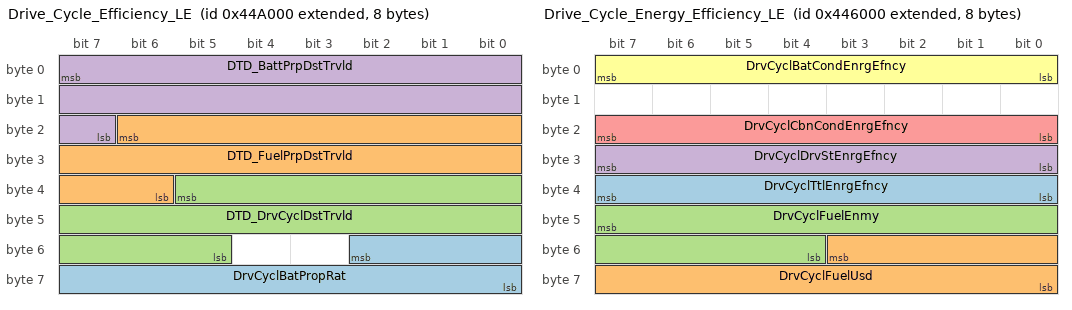
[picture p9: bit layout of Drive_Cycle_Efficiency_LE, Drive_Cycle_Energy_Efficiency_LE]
BO_ 2151981056 Drive_Cycle_Efficiency_LE: 8 CGM_LE
 SG_ DrvCyclBatPropRat : 50|11@0+ (0.048852,0) [0|100.000044] "%"  VCU_LE,CSM_LE,RadioHead_LE
 SG_ DTD_FuelPrpDstTrvld : 22|17@0+ (0.015625,0) [0|2047.984375] "km"  VCU_LE,CSM_LE,RadioHead_LE
 SG_ DTD_DrvCyclDstTrvld : 37|17@0+ (0.015625,0) [0|2047.984375] "km"  VCU_LE,CSM_LE,RadioHead_LE
 SG_ DTD_BattPrpDstTrvld : 7|17@0+ (0.015625,0) [0|2047.984375] "km"  VCU_LE,CSM_LE,RadioHead_LE

BO_ 2151964672 Drive_Cycle_Energy_Efficiency_LE: 8 CGM_LE
 SG_ DrvCyclTtlEnrgEfncy : 39|8@0+ (0.392157,0) [0|100.000035] "%"  VCU_LE,CSM_LE,RadioHead_LE
 SG_ DrvCyclFuelUsd : 51|12@0+ (0.125,0) [0|511.875] "liters"  VCU_LE,CSM_LE,RadioHead_LE
 SG_ DrvCyclFuelEnmy : 47|12@0+ (0.1,0) [0|409.5] "km/liters"  VCU_LE,CSM_LE,RadioHead_LE
 SG_ DrvCyclDrvStEnrgEfncy : 31|8@0+ (0.392157,0) [0|100.000035] "%"  VCU_LE,CSM_LE,RadioHead_LE
 SG_ DrvCyclCbnCondEnrgEfncy : 23|8@0+ (0.392157,0) [0|100.000035] "%"  VCU_LE,CSM_LE,RadioHead_LE
 SG_ DrvCyclBatCondEnrgEfncy : 7|8@0+ (0.392157,0) [0|100.000035] "%"  VCU_LE,CSM_LE,RadioHead_LE

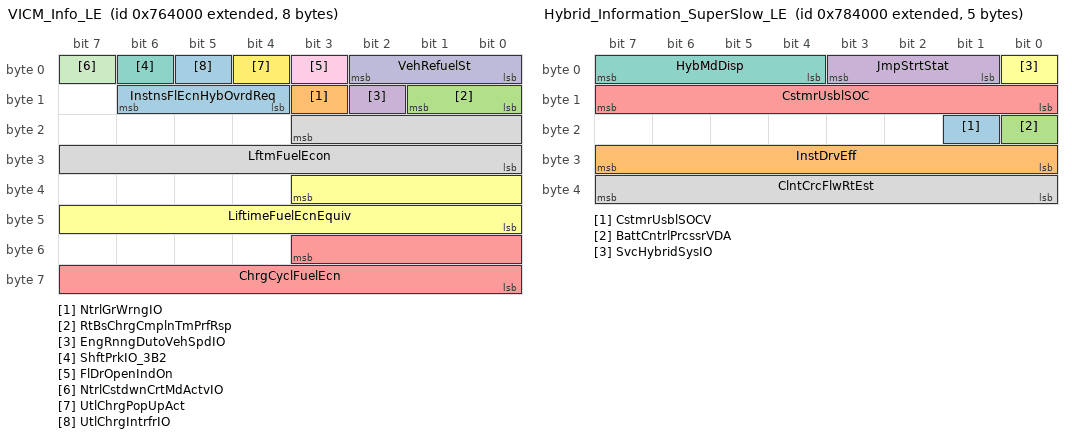
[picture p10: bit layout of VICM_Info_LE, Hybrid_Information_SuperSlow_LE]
BO_ 2155233280 VICM_Info_LE: 8 CGM_LE
 SG_ InstnsFlEcnHybOvrdReq : 14|3@0+ (1,0) [0|7] ""  VCU_LE,IPC_LE
 SG_ NtrlGrWrngIO : 11|1@0+ (1,0) [0|1] ""  VCU_LE,IPC_LE
 SG_ RtBsChrgCmplnTmPrfRsp : 9|2@0+ (1,0) [0|3] ""  VCU_LE,CSM_LE,RadioHead_LE
 SG_ EngRnngDutoVehSpdIO : 10|1@0+ (1,0) [0|1] ""  VCU_LE,IPC_LE
 SG_ ChrgCyclFuelEcn : 51|12@0+ (0.1,0) [0|409.5] "km/l"  VCU_LE,CSM_LE,RadioHead_LE
 SG_ LiftimeFuelEcnEquiv : 35|12@0+ (0.1,0) [0|409.5] "km/l"  VCU_LE,CSM_LE,RadioHead_LE
 SG_ ShftPrkIO_3B2 : 6|1@0+ (1,0) [0|1] ""  VCU_LE,IPC_LE
 SG_ LftmFuelEcon : 19|12@0+ (0.1,0) [0|409.5] "kilometers/liter"  VCU_LE,CSM_LE,RadioHead_LE
 SG_ FlDrOpenIndOn : 3|1@0+ (1,0) [0|1] ""  CSM_LE,RadioHead_LE,VCU_LE,IPC_LE
 SG_ VehRefuelSt : 2|3@0+ (1,0) [0|7] ""  CSM_LE,RadioHead_LE,VCU_LE,IPC_LE
 SG_ NtrlCstdwnCrtMdActvIO : 7|1@0+ (1,0) [0|1] ""  VCU_LE,IPC_LE
 SG_ UtlChrgPopUpAct : 4|1@0+ (1,0) [0|1] ""  VCU_LE,CSM_LE,RadioHead_LE
 SG_ UtlChrgIntrfrIO : 5|1@0+ (1,0) [0|1] ""  IPC_LE,VCU_LE,CSM_LE,RadioHead_LE

BO_ 2155364352 Hybrid_Information_SuperSlow_LE: 5 CGM_LE
 SG_ CstmrUsblSOCV : 17|1@0+ (1,0) [0|1] ""  CSM_LE,RadioHead_LE,VCU_LE,IPC_LE
 SG_ InstDrvEff : 31|8@0- (0.78125,0) [-100|99.21875] "%"  CSM_LE,RadioHead_LE,VCU_LE,IPC_LE
 SG_ BattCntrlPrcssrVDA : 16|1@0+ (1,0) [0|1] ""  CSM_LE,RadioHead_LE,VCU_LE,IPC_LE
 SG_ JmpStrtStat : 3|3@0+ (1,0) [0|7] ""  CSM_LE,RadioHead_LE,VCU_LE,IPC_LE
 SG_ CstmrUsblSOC : 15|8@0+ (0.39216,0) [0|100.0008] "%"  TCP_LE,ONSTAR_LE,CSM_LE,RadioHead_LE,VCU_LE,IPC_LE
 SG_ SvcHybridSysIO : 0|1@0+ (1,0) [0|1] ""  CSM_LE,RadioHead_LE,VCU_LE,IPC_LE
 SG_ HybMdDisp : 7|4@0+ (1,0) [0|15] ""  CSM_LE,IPC_LE,VCU_LE,RadioHead_LE
 SG_ ClntCrcFlwRtEst : 39|8@0+ (0.392157,0) [0|100.000035] "%"  CSM_LE,VCU_LE,RadioHead_LE

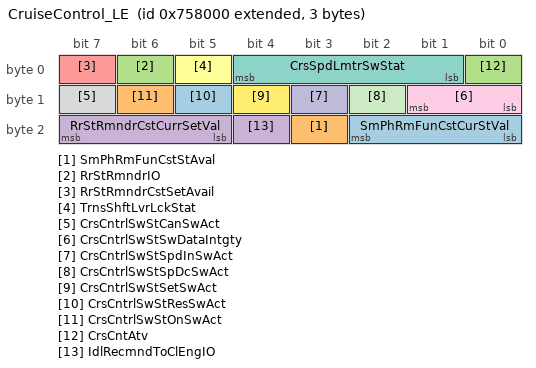
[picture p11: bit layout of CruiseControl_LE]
BO_ 2155184128 CruiseControl_LE: 3 CGM_LE
 SG_ SmPhRmFunCstCurStVal : 18|3@0+ (1,0) [0|7] ""  VCU_LE,CSM_LE,RadioHead_LE
 SG_ SmPhRmFunCstStAval : 19|1@0+ (1,0) [0|1] ""  VCU_LE,CSM_LE,RadioHead_LE
 SG_ RrStRmndrIO : 6|1@0+ (1,0) [0|1] ""  VCU_LE,IPC_LE
 SG_ RrStRmndrCstCurrSetVal : 23|3@0+ (1,0) [0|7] ""  VCU_LE,CSM_LE,RadioHead_LE
 SG_ RrStRmndrCstSetAvail : 7|1@0+ (1,0) [0|1] ""  VCU_LE,CSM_LE,RadioHead_LE
 SG_ TrnsShftLvrLckStat : 5|1@0+ (1,0) [0|1] ""  VCU_LE,CSM_LE,RadioHead_LE
 SG_ CrsSpdLmtrSwStat : 4|4@0+ (1,0) [0|15] ""  CSM_LE,RadioHead_LE,VCU_LE,IPC_LE
 SG_ CrsCntrlSwStCanSwAct : 15|1@0+ (1,0) [0|1] ""  CSM_LE,RadioHead_LE,VCU_LE,IPC_LE,VPM_LE
 SG_ CrsCntrlSwStSwDataIntgty : 9|2@0+ (1,0) [0|3] ""  CSM_LE,RadioHead_LE,VCU_LE,IPC_LE,VPM_LE
 SG_ CrsCntrlSwStSpdInSwAct : 11|1@0+ (1,0) [0|1] ""  CSM_LE,RadioHead_LE,VCU_LE,IPC_LE,VPM_LE
 SG_ CrsCntrlSwStSpDcSwAct : 10|1@0+ (1,0) [0|1] ""  CSM_LE,RadioHead_LE,VCU_LE,IPC_LE,VPM_LE
 SG_ CrsCntrlSwStSetSwAct : 12|1@0+ (1,0) [0|1] ""  CSM_LE,RadioHead_LE,VCU_LE,IPC_LE,VPM_LE
 SG_ CrsCntrlSwStResSwAct : 13|1@0+ (1,0) [0|1] ""  CSM_LE,RadioHead_LE,VCU_LE,IPC_LE,VPM_LE
 SG_ CrsCntrlSwStOnSwAct : 14|1@0+ (1,0) [0|1] ""  CSM_LE,RadioHead_LE,VCU_LE,IPC_LE,VPM_LE
 SG_ CrsCntAtv : 0|1@0+ (1,0) [0|1] ""  CSM_LE,RadioHead_LE,VCU_LE,IPC_LE
 SG_ IdlRecmndToClEngIO : 20|1@0+ (1,0) [0|1] ""  VCU_LE,IPC_LE

BO_TX_BU_ 2158002176 : VCU_LE,RadioHead_LE;
BO_TX_BU_ 2156838912 : VCU_LE,RadioHead_LE;
BO_TX_BU_ 2156937216 : TCP_LE,ONSTAR_LE;
BO_TX_BU_ 2156929024 : TCP_LE,ONSTAR_LE;
BO_TX_BU_ 2156920832 : TCP_LE,ONSTAR_LE;
BO_TX_BU_ 2149883904 : VCU_LE,RadioHead_LE;
BO_TX_BU_ 2151874560 : TCP_LE,ONSTAR_LE;
BO_TX_BU_ 2151383040 : TCP_LE,ONSTAR_LE,VCU_LE,IPC_LE;
BO_TX_BU_ 2149900288 : CGM_LE,TCP_LE,ONSTAR_LE;
BO_TX_BU_ 2159157248 : CSM_LE,VCU_LE,RadioHead_LE;
BO_TX_BU_ 2159091712 : VCU_LE,IPC_LE;
BO_TX_BU_ 2158886912 : VCU_LE,IPC_LE;
BO_TX_BU_ 2158854144 : VCU_LE,IPC_LE;
BO_TX_BU_ 2158919680 : VCU_LE,IPC_LE;
BO_TX_BU_ 2150285312 : VCU_LE,TCP_LE,CSM_LE,ONSTAR_LE,RadioHead_LE;
BO_TX_BU_ 2150277120 : VCU_LE,TCP_LE,CSM_LE,ONSTAR_LE,RadioHead_LE;
BO_TX_BU_ 2156806144 : TCP_LE,ONSTAR_LE;
BO_TX_BU_ 2151514112 : VCU_LE,TCP_LE,ONSTAR_LE,IPC_LE;
BO_TX_BU_ 2151972864 : VCU_LE,IPC_LE;
BO_TX_BU_ 2155479040 : VCU_LE,CSM_LE,RadioHead_LE;
CM_ SG_ 2149752832 IntBrkAssPreFilReq "IntelligentBrakeAssistPreFillRequest";
CM_ SG_ 2149752832 BrkSysRedBrkTlltlReq "Added acc to Björn 0410";
CM_ SG_ 2151874560 ESEIC_EngImRqPsw "Desc: 7 ASCII characters";
CM_ SG_ 2158985216 ODDMO_ReqType "ODI - Type of Request";
CM_ SG_ 2158985216 ODDMO_FUCID "ODI - Primary ID of Functional Unit in FU Database";
CM_ SG_ 2158985216 ODDMO_DispMID "ODI - ID that identifies the display requesting the data.  See detailed requirements in ODI GMLAN Protocol.";
CM_ SG_ 2158985216 ODDMO_DataID2Vld "ODI -DataIDTwo is being requested as a valid ID.";
CM_ SG_ 2158985216 ODDMO_DataID2 "ODI - ID for the second requested data parameter as defined in the FUDatabase";
CM_ SG_ 2158985216 ODDMO_DataID3Vld "ODI -DataIDThree is being requested as a valid ID.";
CM_ SG_ 2158985216 ODDMO_DataID3 "ODI - ID for the third requested data parameter as defined in the FUDatabase";
CM_ SG_ 2158985216 ODDMO_DataID1 "ODI - ID for the first requested data parameter as defined in the FUDatabase";
CM_ SG_ 2158985216 ODDMO_DataID4Vld "ODI -DataIDFour is being requested as a valid ID.";
CM_ SG_ 2158985216 ODDMO_DataID4 "ODI - ID for the fourth requested data parameter as defined in the FUDatabase";
CM_ SG_ 2158985216 ODDMO_DataID5Vld "ODI -DataIDFive is being requested as a valid ID.";
CM_ SG_ 2158985216 ODDMO_DataID5 "ODI - ID for the fifth requested data parameter as defined in the FUDatabase";
CM_ SG_ 2158862336 ODIAOT_FUCID "ODI - Primary ID of Functional Unit in FU Database";
CM_ SG_ 2158862336 ODIAOT_DspMID "ODI - ID that identifies the display requesting the data.  See detailed requirements in ODI GMLAN Protocol.";
CM_ SG_ 2158862336 ODIAOT_ActnVal "ODI-Integer value for Actions with values.
FUDatabase definition of Action includes ActionDataType that defines whether or not Action has a value. 
For Actions without a value, this field is always sent as 0.";
CM_ SG_ 2158862336 ODIAOT_ActnID "ODI-ActionId within the FUClass";
CM_ SG_ 2158886912 ODDLI_SubIdReqM "ODI-The number of list entries, starting at the Index, to send";
CM_ SG_ 2158886912 ODDLI_WrpArnd "ODI-Boolean that shall be set to true if the list shall wrap around.";
CM_ SG_ 2158886912 ODDLI_ReqType "ODI - Type of Request";
CM_ SG_ 2158886912 ODDLI_ReqDir "ODI-Boolean that shall be set to true if req down, set to false if set to up";
CM_ SG_ 2158886912 ODDLI_NmEntries "ODI-The number of list entries, starting at the Index, to send";
CM_ SG_ 2158886912 ODDLI_Idx "ODI-The index within the remote FU’s list at which to start sending data";
CM_ SG_ 2158886912 ODDLI_FUCID "ODI - Primary ID of Functional Unit in FU Database";
CM_ SG_ 2158886912 ODDLI_DspMID "ODI - ID that identifies the display requesting the data.  See detailed requirements in ODI GMLAN Protocol.";
CM_ SG_ 2158886912 ODDLI_DataId "ODI-Data Id for the dynamic list";
CM_ SG_ 2158886912 ODDLI_BckgndFlag "ODI-Informs FU as to priority of response.
Applies to all DataIds in the message.
$0=Immediate response required
$1=Background response";
CM_ BO_ 2158854144 "LAP: Signalerna är inte riktigt kodade!!!        ODI";
CM_ SG_ 2158854144 ODIAI_FUCID "ODI - Primary ID of Functional Unit in FU Database";
CM_ SG_ 2158854144 ODIAI_DspMID "ODI - ID that identifies the display requesting the data.  See detailed requirements in ODI GMLAN Protocol.";
CM_ SG_ 2158854144 ODIAI_ActnVal "ODI-Integer value for Actions with values.
FUDatabase definition of Action includes ActionDataType that defines whether or not Action has a value. 
For Actions without a value, this field is always sent as 0.";
CM_ SG_ 2158854144 ODIAI_ActnID "ODI-ActionId within the FUClass";
CM_ SG_ 2158919680 ODDMI_ReqType "ODI - Type of Request";
CM_ SG_ 2158919680 ODDMI_FUCID "ODI - Primary ID of Functional Unit in FU Database";
CM_ SG_ 2158919680 ODDMI_DispMID "ODI - ID that identifies the display requesting the data.  See detailed requirements in ODI GMLAN Protocol.";
CM_ SG_ 2158919680 ODDMI_DataID2Vld "ODI -DataIDTwo is being requested as a valid ID.";
CM_ SG_ 2158919680 ODDMI_DataID2 "ODI - ID for the second requested data parameter as defined in the FUDatabase";
CM_ SG_ 2158919680 ODDMI_DataID3Vld "ODI -DataIDThree is being requested as a valid ID.";
CM_ SG_ 2158919680 ODDMI_DataID3 "ODI - ID for the third requested data parameter as defined in the FUDatabase";
CM_ SG_ 2158919680 ODDMI_DataID1 "ODI - ID for the first requested data parameter as defined in the FUDatabase";
CM_ SG_ 2158919680 ODDMI_DataID4Vld "ODI -DataIDFour is being requested as a valid ID.";
CM_ SG_ 2158919680 ODDMI_DataID4 "ODI - ID for the fourth requested data parameter as defined in the FUDatabase";
CM_ SG_ 2158919680 ODDMI_DataID5Vld "ODI -DataIDFive is being requested as a valid ID.";
CM_ SG_ 2158919680 ODDMI_DataID5 "ODI - ID for the fifth requested data parameter as defined in the FUDatabase";
CM_ SG_ 2150285312 PsngSysHding "The 'usable' range is somewhat less than the encoded range (0.0 to 359.9 degrees).  0.0 degrees represents North, 90.0 degrees represents East.";
CM_ SG_ 2150277120 PsngSysLong "The units of the data are milli-arcseconds (1/3,600,000 of a degree).  The actual 'usable' range of this data is somewhat less than the encoded range (+/- 648,000,000, corresponding to +/- 180 degrees)";
CM_ SG_ 2150277120 PsngSysLat "The units of the data are milli-arcseconds (1/3,600,000 of a degree).  The actual 'usable' range of this data is somewhat less than the encoded range (+/- 324,000,000, corresponding to +/- 90 degrees)";
BA_DEF_ SG_  "VNSigPrimaryTriggering" ENUM  "No","Yes","DLCLS","DLCHS","DLCCE","DLCFO";
BA_DEF_ SG_  "VNSigRemoteDiagnostics" ENUM  "No","Yes","DLCLS","DLCHS","DLCCE","DLCFO";
BA_DEF_ SG_  "VNSigInfotainment" ENUM  "No","Yes","DLCLS","DLCHS","DLCCE","DLCFO";
BA_DEF_ SG_  "VNSigParkedVehicle" ENUM  "No","Yes","DLCLS","DLCHS","DLCCE","DLCFO";
BA_DEF_ SG_  "VNSigIntermediate" ENUM  "No","Yes","DLCLS","DLCHS","DLCCE","DLCFO";
BA_DEF_ SG_  "VNSigUnused_4" ENUM  "No","Yes","DLCLS","DLCHS","DLCCE","DLCFO";
BA_DEF_ SG_  "SignalType" STRING ;
BA_DEF_ SG_  "PacketOrder" INT 0 65535;
BA_DEF_ SG_  "SignalLongName" STRING ;
BA_DEF_ SG_  "GenSigStartValue" INT 0 65535;
BA_DEF_ SG_  "VNSigDiagnostic" ENUM  "No","Yes","DLCLS","DLCHS","DLCCE","DLCFO";
BA_DEF_ SG_  "VNSigAllNodes" ENUM  "No","Yes","DLCLS","DLCHS","DLCCE","DLCFO";
BA_DEF_ SG_  "GenSigDeltaValue" INT 0 0;
BA_DEF_ SG_  "GenSigSendType" ENUM  "not used","not used","not used","not used","not used","not used","not used","NoSigSendType","not used","not used","OnAnyChange","OnChangeIfActive","OnDelta","DLCLS","DLCHS","DLCCE","DLCFO";
BA_DEF_ SG_  "GenSigSendOnInit" ENUM  "Not Initialized","Application","Handler","DLCLS","DLCHS","DLCCE","DLCFO";
BA_DEF_ BO_  "AppGenMsgCycleTime" INT 0 0;
BA_DEF_ BO_  "TpTxIndex" INT 0 99;
BA_DEF_ BO_  "GenMsgILSupport" ENUM  "No","Yes","DLCLS","DLCHS","DLCCE","DLCFO";
BA_DEF_ BO_  "TpApplType" STRING ;
BA_DEF_ BO_  "Prio" INT 0 7;
BA_DEF_ BO_  "MessageSubnet" ENUM  "LS","MS","HS","CE","PE","HV","FO","S1","HE","LE","HE2","DLCLS","DLCHS","DLCCE","DLCFO";
BA_DEF_ BO_  "GenMsgMandatoryToSupervision" ENUM  "No","Yes","DLCLS","DLCHS","DLCCE","DLCFO";
BA_DEF_ BO_  "DiagState" ENUM  "No","Yes","DLCLS","DLCHS","DLCCE","DLCFO";
BA_DEF_ BO_  "GenMsgStartDelayTime" INT 0 100000;
BA_DEF_ BO_  "GenMsgDelayTime" INT 0 100000;
BA_DEF_ BO_  "GenMsgCycleTime" INT 0 100000;
BA_DEF_ BO_  "GenMsgSendType" ENUM  "cyclicX","spontanX","cyclicIfActiveX","spontanWithDelay","cyclicAndSpontanX","cyclicAndSpontanWithDelay","spontanWithRepitition","cyclicIfActiveAndSpontanWD","DLCLS","DLCHS","DLCCE","DLCFO";
BA_DEF_ BO_  "DiagResponse" ENUM  "No","Yes","DLCLS","DLCHS","DLCCE","DLCFO";
BA_DEF_ BO_  "DiagRequest" ENUM  "No","Yes","DLCLS","DLCHS","DLCCE","DLCFO";
BA_DEF_ BO_  "NmMessage" ENUM  "No","Yes","DLCLS","DLCHS","DLCCE","DLCFO";
BA_DEF_REL_ BU_SG_REL_  "GenSigSuprvRespComment" STRING ;
BA_DEF_REL_ BU_SG_REL_  "GenSigVBitResp" ENUM  "No","Yes","DLCLS","DLCHS","DLCCE","DLCFO";
BA_DEF_REL_ BU_SG_REL_  "GenSigVBitRespComment" STRING ;
BA_DEF_REL_ BU_SG_REL_  "GenSigVDAFailComment" STRING ;
BA_DEF_REL_ BU_SG_REL_  "GenSigVDAFailResp" ENUM  "No","Yes","DLCLS","DLCHS","DLCCE","DLCFO";
BA_DEF_REL_ BU_SG_REL_  "GenSigRxStartValue" STRING ;
BA_DEF_REL_ BU_SG_REL_  "GenSigSuprvRespSubValue" INT 0 65535;
BA_DEF_REL_ BU_SG_REL_  "GenSigSuprvResp" ENUM  "None","Notify App","Substitute Default","DLCLS","DLCHS","DLCCE","DLCFO";
BA_DEF_REL_ BU_SG_REL_  "GenSigTimeoutMsg" HEX -2147483648 268435455;
BA_DEF_DEF_  "VNSigPrimaryTriggering" "No";
BA_DEF_DEF_  "VNSigRemoteDiagnostics" "No";
BA_DEF_DEF_  "VNSigInfotainment" "No";
BA_DEF_DEF_  "VNSigParkedVehicle" "No";
BA_DEF_DEF_  "VNSigIntermediate" "No";
BA_DEF_DEF_  "VNSigUnused_4" "No";
BA_DEF_DEF_  "SignalType" "";
BA_DEF_DEF_  "PacketOrder" 0;
BA_DEF_DEF_  "SignalLongName" "";
BA_DEF_DEF_  "GenSigStartValue" 0;
BA_DEF_DEF_  "VNSigDiagnostic" "No";
BA_DEF_DEF_  "VNSigAllNodes" "No";
BA_DEF_DEF_  "GenSigDeltaValue" 0;
BA_DEF_DEF_  "GenSigSendType" "NoSigSendType";
BA_DEF_DEF_  "GenSigSendOnInit" "Not Initialized";
BA_DEF_DEF_  "AppGenMsgCycleTime" 0;
BA_DEF_DEF_  "TpTxIndex" 0;
BA_DEF_DEF_  "GenMsgILSupport" "Yes";
BA_DEF_DEF_  "TpApplType" "";
BA_DEF_DEF_  "Prio" 4;
BA_DEF_DEF_  "MessageSubnet" "FO";
BA_DEF_DEF_  "GenMsgMandatoryToSupervision" "No";
BA_DEF_DEF_  "DiagState" "No";
BA_DEF_DEF_  "GenMsgStartDelayTime" 0;
BA_DEF_DEF_  "GenMsgDelayTime" 0;
BA_DEF_DEF_  "GenMsgCycleTime" 0;
BA_DEF_DEF_  "GenMsgSendType" "spontanX";
BA_DEF_DEF_  "DiagResponse" "No";
BA_DEF_DEF_  "DiagRequest" "No";
BA_DEF_DEF_  "NmMessage" "No";
BA_DEF_DEF_REL_ "GenSigSuprvRespComment" "";
BA_DEF_DEF_REL_ "GenSigVBitResp" "No";
BA_DEF_DEF_REL_ "GenSigVBitRespComment" "";
BA_DEF_DEF_REL_ "GenSigVDAFailComment" "";
BA_DEF_DEF_REL_ "GenSigVDAFailResp" "No";
BA_DEF_DEF_REL_ "GenSigRxStartValue" "";
BA_DEF_DEF_REL_ "GenSigSuprvRespSubValue" 0;
BA_DEF_DEF_REL_ "GenSigSuprvResp" "None";
BA_DEF_DEF_REL_ "GenSigTimeoutMsg" 0;
BA_ "MessageSubnet" BO_ 2154397696 9;
BA_ "GenMsgDelayTime" BO_ 2154397696 100;
BA_ "TpTxIndex" BO_ 2154553344 3;
BA_ "MessageSubnet" BO_ 2154553344 9;
BA_ "TpTxIndex" BO_ 2154536960 3;
BA_ "MessageSubnet" BO_ 2154536960 9;
BA_ "TpTxIndex" BO_ 2154545152 2;
BA_ "MessageSubnet" BO_ 2154545152 9;
BA_ "TpTxIndex" BO_ 2154520576 2;
BA_ "MessageSubnet" BO_ 2154520576 9;
BA_ "TpTxIndex" BO_ 2154504192 1;
BA_ "MessageSubnet" BO_ 2154504192 9;
BA_ "TpTxIndex" BO_ 2154479616 1;
BA_ "MessageSubnet" BO_ 2154479616 9;
BA_ "MessageSubnet" BO_ 2154381312 9;
BA_ "GenMsgDelayTime" BO_ 2154381312 20;
BA_ "GenMsgCycleTime" BO_ 2154381312 3000;
BA_ "GenMsgSendType" BO_ 2154381312 0;
BA_ "MessageSubnet" BO_ 2150121472 9;
BA_ "GenMsgDelayTime" BO_ 2150121472 100;
BA_ "MessageSubnet" BO_ 2150547456 9;
BA_ "GenMsgDelayTime" BO_ 2150547456 100;
BA_ "MessageSubnet" BO_ 2149752832 9;
BA_ "GenMsgStartDelayTime" BO_ 2149752832 110;
BA_ "GenMsgCycleTime" BO_ 2149752832 250;
BA_ "GenMsgSendType" BO_ 2149752832 0;
BA_ "MessageSubnet" BO_ 2156216320 9;
BA_ "GenMsgDelayTime" BO_ 2156216320 100;
BA_ "MessageSubnet" BO_ 2158002176 9;
BA_ "GenMsgDelayTime" BO_ 2158002176 100;
BA_ "MessageSubnet" BO_ 2156838912 9;
BA_ "GenMsgDelayTime" BO_ 2156838912 100;
BA_ "MessageSubnet" BO_ 2156937216 9;
BA_ "GenMsgDelayTime" BO_ 2156937216 100;
BA_ "MessageSubnet" BO_ 2156929024 9;
BA_ "GenMsgDelayTime" BO_ 2156929024 100;
BA_ "MessageSubnet" BO_ 2156920832 9;
BA_ "GenMsgDelayTime" BO_ 2156920832 100;
BA_ "MessageSubnet" BO_ 2156871680 9;
BA_ "GenMsgDelayTime" BO_ 2156871680 100;
BA_ "MessageSubnet" BO_ 2156863488 9;
BA_ "GenMsgDelayTime" BO_ 2156863488 100;
BA_ "MessageSubnet" BO_ 2156855296 9;
BA_ "GenMsgDelayTime" BO_ 2156855296 100;
BA_ "MessageSubnet" BO_ 2156822528 9;
BA_ "GenMsgDelayTime" BO_ 2156822528 100;
BA_ "MessageSubnet" BO_ 2149883904 9;
BA_ "GenMsgDelayTime" BO_ 2149883904 100;
BA_ "MessageSubnet" BO_ 2152038400 9;
BA_ "GenMsgDelayTime" BO_ 2152038400 100;
BA_ "MessageSubnet" BO_ 2151874560 9;
BA_ "GenMsgDelayTime" BO_ 2151874560 100;
BA_ "MessageSubnet" BO_ 2151383040 9;
BA_ "GenMsgDelayTime" BO_ 2151383040 100;
BA_ "MessageSubnet" BO_ 2149900288 9;
BA_ "GenMsgDelayTime" BO_ 2149900288 100;
BA_ "MessageSubnet" BO_ 2158985216 9;
BA_ "GenMsgDelayTime" BO_ 2158985216 20;
BA_ "MessageSubnet" BO_ 2158862336 9;
BA_ "GenMsgDelayTime" BO_ 2158862336 20;
BA_ "MessageSubnet" BO_ 2159157248 9;
BA_ "GenMsgDelayTime" BO_ 2159157248 10;
BA_ "MessageSubnet" BO_ 2159091712 9;
BA_ "GenMsgDelayTime" BO_ 2159091712 10;
BA_ "MessageSubnet" BO_ 2158886912 9;
BA_ "GenMsgDelayTime" BO_ 2158886912 20;
BA_ "MessageSubnet" BO_ 2158854144 9;
BA_ "GenMsgDelayTime" BO_ 2158854144 20;
BA_ "MessageSubnet" BO_ 2158919680 9;
BA_ "GenMsgDelayTime" BO_ 2158919680 20;
BA_ "MessageSubnet" BO_ 2150023168 9;
BA_ "GenMsgCycleTime" BO_ 2150023168 250;
BA_ "GenMsgSendType" BO_ 2150023168 0;
BA_ "MessageSubnet" BO_ 2150285312 9;
BA_ "GenMsgDelayTime" BO_ 2150285312 100;
BA_ "MessageSubnet" BO_ 2150277120 9;
BA_ "GenMsgDelayTime" BO_ 2150277120 100;
BA_ "MessageSubnet" BO_ 2156806144 9;
BA_ "GenMsgDelayTime" BO_ 2156806144 500;
BA_ "MessageSubnet" BO_ 2151514112 9;
BA_ "GenMsgDelayTime" BO_ 2151514112 100;
BA_ "MessageSubnet" BO_ 2154561536 9;
BA_ "GenMsgStartDelayTime" BO_ 2154561536 170;
BA_ "GenMsgCycleTime" BO_ 2154561536 1000;
BA_ "GenMsgSendType" BO_ 2154561536 0;
BA_ "Prio" BO_ 2155872256 3;
BA_ "MessageSubnet" BO_ 2155872256 9;
BA_ "GenMsgStartDelayTime" BO_ 2155872256 190;
BA_ "GenMsgCycleTime" BO_ 2155872256 250;
BA_ "GenMsgSendType" BO_ 2155872256 0;
BA_ "MessageSubnet" BO_ 2151972864 9;
BA_ "GenMsgDelayTime" BO_ 2151972864 100;
BA_ "MessageSubnet" BO_ 2152095744 9;
BA_ "GenMsgStartDelayTime" BO_ 2152095744 120;
BA_ "GenMsgCycleTime" BO_ 2152095744 2000;
BA_ "GenMsgSendType" BO_ 2152095744 0;
BA_ "MessageSubnet" BO_ 2155479040 9;
BA_ "GenMsgDelayTime" BO_ 2155479040 100;
BA_ "MessageSubnet" BO_ 2151981056 9;
BA_ "GenMsgDelayTime" BO_ 2151981056 100;
BA_ "MessageSubnet" BO_ 2151964672 9;
BA_ "GenMsgDelayTime" BO_ 2151964672 100;
BA_ "MessageSubnet" BO_ 2155233280 9;
BA_ "GenMsgDelayTime" BO_ 2155233280 100;
BA_ "MessageSubnet" BO_ 2155364352 9;
BA_ "GenMsgStartDelayTime" BO_ 2155364352 10;
BA_ "GenMsgDelayTime" BO_ 2155364352 100;
BA_ "GenMsgCycleTime" BO_ 2155364352 250;
BA_ "GenMsgSendType" BO_ 2155364352 0;
BA_ "MessageSubnet" BO_ 2155184128 9;
BA_ "GenMsgDelayTime" BO_ 2155184128 100;
BA_ "GenSigSendType" SG_ 2154397696 CrShrngRvkCertfctRsp 10;
BA_ "VNSigIntermediate" SG_ 2154397696 CrShrngRvkCertfctRsp 1;
BA_ "SignalType" SG_ 2154397696 CrShrngRvkCertfctRsp "ENM";
BA_ "SignalLongName" SG_ 2154397696 CrShrngRvkCertfctRsp "Car Sharing Revoke Certificate Response";
BA_ "GenSigSendType" SG_ 2154397696 CrShrngConnStat 10;
BA_ "VNSigIntermediate" SG_ 2154397696 CrShrngConnStat 1;
BA_ "SignalType" SG_ 2154397696 CrShrngConnStat "ENM";
BA_ "SignalLongName" SG_ 2154397696 CrShrngConnStat "Car Sharing Connection Status";
BA_ "GenSigSendType" SG_ 2154397696 CrShrngFbsEnblStat 10;
BA_ "VNSigIntermediate" SG_ 2154397696 CrShrngFbsEnblStat 1;
BA_ "SignalType" SG_ 2154397696 CrShrngFbsEnblStat "ENM";
BA_ "SignalLongName" SG_ 2154397696 CrShrngFbsEnblStat "Car Sharing Fobs Enable Status";
BA_ "GenSigDeltaValue" SG_ 2154397696 FobIntrCt 1;
BA_ "GenSigSendType" SG_ 2154397696 FobIntrCt 12;
BA_ "VNSigIntermediate" SG_ 2154397696 FobIntrCt 1;
BA_ "SignalType" SG_ 2154397696 FobIntrCt "UNM";
BA_ "SignalLongName" SG_ 2154397696 FobIntrCt "Fob Interior Count";
BA_ "GenSigDeltaValue" SG_ 2154397696 CSPS_CertfctId 1;
BA_ "GenSigSendType" SG_ 2154397696 CSPS_CertfctId 12;
BA_ "PacketOrder" SG_ 2154397696 CSPS_CertfctId 3;
BA_ "VNSigIntermediate" SG_ 2154397696 CSPS_CertfctId 1;
BA_ "SignalType" SG_ 2154397696 CSPS_CertfctId "UNM";
BA_ "SignalLongName" SG_ 2154397696 CSPS_CertfctId "Car Sharing Phone Status : Certificate Identification";
BA_ "GenSigSendType" SG_ 2154397696 CSPS_ConnStat 10;
BA_ "PacketOrder" SG_ 2154397696 CSPS_ConnStat 2;
BA_ "VNSigIntermediate" SG_ 2154397696 CSPS_ConnStat 1;
BA_ "SignalType" SG_ 2154397696 CSPS_ConnStat "ENM";
BA_ "SignalLongName" SG_ 2154397696 CSPS_ConnStat "Car Sharing Phone Status : Connection Status";
BA_ "GenSigSendType" SG_ 2154397696 CSPS_RspVerf 10;
BA_ "PacketOrder" SG_ 2154397696 CSPS_RspVerf 1;
BA_ "VNSigIntermediate" SG_ 2154397696 CSPS_RspVerf 1;
BA_ "SignalType" SG_ 2154397696 CSPS_RspVerf "ENM";
BA_ "SignalLongName" SG_ 2154397696 CSPS_RspVerf "Car Sharing Phone Status : Response Verification";
BA_ "GenSigDeltaValue" SG_ 2154553344 CrShrngEncrpScrtRsp 1;
BA_ "GenSigSendType" SG_ 2154553344 CrShrngEncrpScrtRsp 12;
BA_ "VNSigIntermediate" SG_ 2154553344 CrShrngEncrpScrtRsp 1;
BA_ "SignalType" SG_ 2154553344 CrShrngEncrpScrtRsp "UNM";
BA_ "SignalLongName" SG_ 2154553344 CrShrngEncrpScrtRsp "Car Sharing Encrypted Secret Response";
BA_ "GenSigDeltaValue" SG_ 2154536960 CrShrngEncrpScrt 1;
BA_ "GenSigSendType" SG_ 2154536960 CrShrngEncrpScrt 12;
BA_ "VNSigIntermediate" SG_ 2154536960 CrShrngEncrpScrt 1;
BA_ "SignalType" SG_ 2154536960 CrShrngEncrpScrt "UNM";
BA_ "SignalLongName" SG_ 2154536960 CrShrngEncrpScrt "Car Sharing Encrypted Secret";
BA_ "GenSigDeltaValue" SG_ 2154545152 CrShrgIntCtftAthrtyCtftRp 1;
BA_ "GenSigSendType" SG_ 2154545152 CrShrgIntCtftAthrtyCtftRp 12;
BA_ "VNSigIntermediate" SG_ 2154545152 CrShrgIntCtftAthrtyCtftRp 1;
BA_ "SignalType" SG_ 2154545152 CrShrgIntCtftAthrtyCtftRp "UNM";
BA_ "SignalLongName" SG_ 2154545152 CrShrgIntCtftAthrtyCtftRp "Car Sharing Intermediate Certificate Authority Certificate Response";
BA_ "GenSigDeltaValue" SG_ 2154520576 CrShrgIntCtftAthrtyCtft 1;
BA_ "GenSigSendType" SG_ 2154520576 CrShrgIntCtftAthrtyCtft 12;
BA_ "VNSigIntermediate" SG_ 2154520576 CrShrgIntCtftAthrtyCtft 1;
BA_ "SignalType" SG_ 2154520576 CrShrgIntCtftAthrtyCtft "UNM";
BA_ "SignalLongName" SG_ 2154520576 CrShrgIntCtftAthrtyCtft "Car Sharing Intermediate Certificate Authority Certificate";
BA_ "GenSigDeltaValue" SG_ 2154504192 CrShrngUsrCertfctRsp 1;
BA_ "GenSigSendType" SG_ 2154504192 CrShrngUsrCertfctRsp 12;
BA_ "VNSigIntermediate" SG_ 2154504192 CrShrngUsrCertfctRsp 1;
BA_ "SignalType" SG_ 2154504192 CrShrngUsrCertfctRsp "UNM";
BA_ "SignalLongName" SG_ 2154504192 CrShrngUsrCertfctRsp "Car Sharing User Certificate Response";
BA_ "GenSigDeltaValue" SG_ 2154479616 CrShrngUsrCertfct 1;
BA_ "GenSigSendType" SG_ 2154479616 CrShrngUsrCertfct 12;
BA_ "VNSigIntermediate" SG_ 2154479616 CrShrngUsrCertfct 1;
BA_ "SignalType" SG_ 2154479616 CrShrngUsrCertfct "UNM";
BA_ "SignalLongName" SG_ 2154479616 CrShrngUsrCertfct "Car Sharing User Certificate";
BA_ "GenSigSendType" SG_ 2154381312 CSZS_FrntCmptZnMbDevStat 10;
BA_ "VNSigIntermediate" SG_ 2154381312 CSZS_FrntCmptZnMbDevStat 1;
BA_ "SignalType" SG_ 2154381312 CSZS_FrntCmptZnMbDevStat "ENM";
BA_ "PacketOrder" SG_ 2154381312 CSZS_FrntCmptZnMbDevStat 8;
BA_ "SignalLongName" SG_ 2154381312 CSZS_FrntCmptZnMbDevStat "Car Sharing Zone Status : Front Compartment Zone Mobile Device Status";
BA_ "GenSigSendType" SG_ 2154381312 CSZS_RrCmptZnMbDevStat 10;
BA_ "VNSigIntermediate" SG_ 2154381312 CSZS_RrCmptZnMbDevStat 1;
BA_ "SignalType" SG_ 2154381312 CSZS_RrCmptZnMbDevStat "ENM";
BA_ "PacketOrder" SG_ 2154381312 CSZS_RrCmptZnMbDevStat 7;
BA_ "SignalLongName" SG_ 2154381312 CSZS_RrCmptZnMbDevStat "Car Sharing Zone Status : Rear Compartment Zone Mobile Device Status";
BA_ "GenSigSendType" SG_ 2154381312 CSZS_FrntExtrZnMbDevStat 10;
BA_ "VNSigIntermediate" SG_ 2154381312 CSZS_FrntExtrZnMbDevStat 1;
BA_ "SignalType" SG_ 2154381312 CSZS_FrntExtrZnMbDevStat "ENM";
BA_ "PacketOrder" SG_ 2154381312 CSZS_FrntExtrZnMbDevStat 6;
BA_ "SignalLongName" SG_ 2154381312 CSZS_FrntExtrZnMbDevStat "Car Sharing Zone Status : Front Exterior Zone Mobile Device Stats";
BA_ "GenSigSendType" SG_ 2154381312 CSZS_RrExtrZnMbDevStat 10;
BA_ "VNSigIntermediate" SG_ 2154381312 CSZS_RrExtrZnMbDevStat 1;
BA_ "SignalType" SG_ 2154381312 CSZS_RrExtrZnMbDevStat "ENM";
BA_ "PacketOrder" SG_ 2154381312 CSZS_RrExtrZnMbDevStat 5;
BA_ "SignalLongName" SG_ 2154381312 CSZS_RrExtrZnMbDevStat "Car Sharing Zone Status : Rear Exterior Zone Mobile Device Status";
BA_ "GenSigSendType" SG_ 2154381312 CSZS_WlcmZnMbDevStat 10;
BA_ "VNSigIntermediate" SG_ 2154381312 CSZS_WlcmZnMbDevStat 1;
BA_ "SignalType" SG_ 2154381312 CSZS_WlcmZnMbDevStat "ENM";
BA_ "PacketOrder" SG_ 2154381312 CSZS_WlcmZnMbDevStat 4;
BA_ "SignalLongName" SG_ 2154381312 CSZS_WlcmZnMbDevStat "Car Sharing Zone Status : Welcome Zone Mobile Device Status";
BA_ "GenSigSendType" SG_ 2154381312 CSZS_IntrZnMbDevStat 10;
BA_ "VNSigIntermediate" SG_ 2154381312 CSZS_IntrZnMbDevStat 1;
BA_ "SignalType" SG_ 2154381312 CSZS_IntrZnMbDevStat "ENM";
BA_ "PacketOrder" SG_ 2154381312 CSZS_IntrZnMbDevStat 3;
BA_ "SignalLongName" SG_ 2154381312 CSZS_IntrZnMbDevStat "Car Sharing Zone Status : Interior Zone Mobile Device Status";
BA_ "GenSigSendType" SG_ 2154381312 CSZS_PassEntyZnMbDevStat 10;
BA_ "VNSigIntermediate" SG_ 2154381312 CSZS_PassEntyZnMbDevStat 1;
BA_ "SignalType" SG_ 2154381312 CSZS_PassEntyZnMbDevStat "ENM";
BA_ "PacketOrder" SG_ 2154381312 CSZS_PassEntyZnMbDevStat 2;
BA_ "SignalLongName" SG_ 2154381312 CSZS_PassEntyZnMbDevStat "Car Sharing Zone Status : Passenger Entry Zone Mobile Device Status";
BA_ "GenSigSendType" SG_ 2154381312 CSZS_DrEntyZnMbDevStat 10;
BA_ "VNSigIntermediate" SG_ 2154381312 CSZS_DrEntyZnMbDevStat 1;
BA_ "SignalType" SG_ 2154381312 CSZS_DrEntyZnMbDevStat "ENM";
BA_ "PacketOrder" SG_ 2154381312 CSZS_DrEntyZnMbDevStat 1;
BA_ "SignalLongName" SG_ 2154381312 CSZS_DrEntyZnMbDevStat "Car Sharing Zone Status : Driver Entry Zone Mobile Device Status";
BA_ "GenSigSendType" SG_ 2150121472 RmtTrlrLtngSeqReq 10;
BA_ "GenSigSendOnInit" SG_ 2150121472 RmtTrlrLtngSeqReq 2;
BA_ "VNSigIntermediate" SG_ 2150121472 RmtTrlrLtngSeqReq 1;
BA_ "SignalType" SG_ 2150121472 RmtTrlrLtngSeqReq "ENM";
BA_ "SignalLongName" SG_ 2150121472 RmtTrlrLtngSeqReq "Remote Trailer Lighting Sequence Request";
BA_ "VNSigAllNodes" SG_ 2150121472 RmtTrlrLtngSeqReq 1;
BA_ "GenSigDeltaValue" SG_ 2150547456 HVDpltnMdCnfdcTrndg 1;
BA_ "GenSigSendType" SG_ 2150547456 HVDpltnMdCnfdcTrndg 12;
BA_ "SignalType" SG_ 2150547456 HVDpltnMdCnfdcTrndg "SNM";
BA_ "SignalLongName" SG_ 2150547456 HVDpltnMdCnfdcTrndg "High Voltage Depletion Mode Confidence Trending";
BA_ "VNSigAllNodes" SG_ 2150547456 HVDpltnMdCnfdcTrndg 1;
BA_ "GenSigSendType" SG_ 2150547456 OffBrdHVCVehPwrLvl 10;
BA_ "GenSigSendOnInit" SG_ 2150547456 OffBrdHVCVehPwrLvl 1;
BA_ "VNSigInfotainment" SG_ 2150547456 OffBrdHVCVehPwrLvl 1;
BA_ "SignalType" SG_ 2150547456 OffBrdHVCVehPwrLvl "ENM";
BA_ "SignalLongName" SG_ 2150547456 OffBrdHVCVehPwrLvl "Off Board High Voltage Charging Vehicle Power Level";
BA_ "VNSigAllNodes" SG_ 2150547456 OffBrdHVCVehPwrLvl 1;
BA_ "GenSigSendType" SG_ 2150547456 OffBrdHVCVehPwrDrtd 10;
BA_ "GenSigSendOnInit" SG_ 2150547456 OffBrdHVCVehPwrDrtd 1;
BA_ "VNSigInfotainment" SG_ 2150547456 OffBrdHVCVehPwrDrtd 1;
BA_ "SignalType" SG_ 2150547456 OffBrdHVCVehPwrDrtd "BLN";
BA_ "SignalLongName" SG_ 2150547456 OffBrdHVCVehPwrDrtd "Off Board High Voltage Charging Vehicle Power Derated";
BA_ "VNSigAllNodes" SG_ 2150547456 OffBrdHVCVehPwrDrtd 1;
BA_ "GenSigSendType" SG_ 2150547456 OffBrdHVCVehCplrLkd 10;
BA_ "GenSigSendOnInit" SG_ 2150547456 OffBrdHVCVehCplrLkd 1;
BA_ "VNSigInfotainment" SG_ 2150547456 OffBrdHVCVehCplrLkd 1;
BA_ "SignalType" SG_ 2150547456 OffBrdHVCVehCplrLkd "BLN";
BA_ "SignalLongName" SG_ 2150547456 OffBrdHVCVehCplrLkd "Off Board High Voltage Charging Vehicle Coupler Locked";
BA_ "VNSigAllNodes" SG_ 2150547456 OffBrdHVCVehCplrLkd 1;
BA_ "GenSigSendType" SG_ 2150547456 OffBrdHVBlkChrgCmp 10;
BA_ "SignalType" SG_ 2150547456 OffBrdHVBlkChrgCmp "BLN";
BA_ "SignalLongName" SG_ 2150547456 OffBrdHVBlkChrgCmp "Off Board High Voltage Bulk Charging Complete";
BA_ "VNSigAllNodes" SG_ 2150547456 OffBrdHVBlkChrgCmp 1;
BA_ "GenSigDeltaValue" SG_ 2150547456 OBHVBCCT_MinofHr 1;
BA_ "GenSigSendType" SG_ 2150547456 OBHVBCCT_MinofHr 12;
BA_ "GenSigSendOnInit" SG_ 2150547456 OBHVBCCT_MinofHr 1;
BA_ "VNSigInfotainment" SG_ 2150547456 OBHVBCCT_MinofHr 1;
BA_ "SignalType" SG_ 2150547456 OBHVBCCT_MinofHr "UNM";
BA_ "PacketOrder" SG_ 2150547456 OBHVBCCT_MinofHr 3;
BA_ "SignalLongName" SG_ 2150547456 OBHVBCCT_MinofHr "Off Board High Voltage Bulk Charging Complete Time : Minute of Hour";
BA_ "VNSigAllNodes" SG_ 2150547456 OBHVBCCT_MinofHr 1;
BA_ "GenSigDeltaValue" SG_ 2150547456 OBHVBCCT_HrofDay 1;
BA_ "GenSigSendType" SG_ 2150547456 OBHVBCCT_HrofDay 12;
BA_ "GenSigSendOnInit" SG_ 2150547456 OBHVBCCT_HrofDay 1;
BA_ "VNSigInfotainment" SG_ 2150547456 OBHVBCCT_HrofDay 1;
BA_ "SignalType" SG_ 2150547456 OBHVBCCT_HrofDay "UNM";
BA_ "PacketOrder" SG_ 2150547456 OBHVBCCT_HrofDay 2;
BA_ "SignalLongName" SG_ 2150547456 OBHVBCCT_HrofDay "Off Board High Voltage Bulk Charging Complete Time : Hour of Day";
BA_ "VNSigAllNodes" SG_ 2150547456 OBHVBCCT_HrofDay 1;
BA_ "GenSigDeltaValue" SG_ 2150547456 OBHVBCCT_DayofWk 1;
BA_ "GenSigSendType" SG_ 2150547456 OBHVBCCT_DayofWk 12;
BA_ "GenSigSendOnInit" SG_ 2150547456 OBHVBCCT_DayofWk 1;
BA_ "VNSigInfotainment" SG_ 2150547456 OBHVBCCT_DayofWk 1;
BA_ "SignalType" SG_ 2150547456 OBHVBCCT_DayofWk "UNM";
BA_ "PacketOrder" SG_ 2150547456 OBHVBCCT_DayofWk 1;
BA_ "SignalLongName" SG_ 2150547456 OBHVBCCT_DayofWk "Off Board High Voltage Bulk Charging Complete Time : Day of Week";
BA_ "VNSigAllNodes" SG_ 2150547456 OBHVBCCT_DayofWk 1;
BA_ "GenSigSendType" SG_ 2150547456 ElecPrplsnMtrOvrSpdIO 10;
BA_ "SignalType" SG_ 2150547456 ElecPrplsnMtrOvrSpdIO "BLN";
BA_ "SignalLongName" SG_ 2150547456 ElecPrplsnMtrOvrSpdIO "Electric Propulsion Motor Over Speed Indication On";
BA_ "VNSigAllNodes" SG_ 2150547456 ElecPrplsnMtrOvrSpdIO 1;
BA_ "GenSigSendType" SG_ 2150547456 HVBatOutOfEnrgyInd 10;
BA_ "VNSigInfotainment" SG_ 2150547456 HVBatOutOfEnrgyInd 1;
BA_ "SignalType" SG_ 2150547456 HVBatOutOfEnrgyInd "ENM";
BA_ "SignalLongName" SG_ 2150547456 HVBatOutOfEnrgyInd "High Voltage Battery Out of Energy Indication";
BA_ "VNSigAllNodes" SG_ 2150547456 HVBatOutOfEnrgyInd 1;
BA_ "GenSigSendType" SG_ 2150547456 CntrsOpnUndrTmpIO 10;
BA_ "VNSigInfotainment" SG_ 2150547456 CntrsOpnUndrTmpIO 1;
BA_ "SignalType" SG_ 2150547456 CntrsOpnUndrTmpIO "BLN";
BA_ "SignalLongName" SG_ 2150547456 CntrsOpnUndrTmpIO "Contactors Open Under Temperature Indication On";
BA_ "VNSigAllNodes" SG_ 2150547456 CntrsOpnUndrTmpIO 1;
BA_ "GenSigSendType" SG_ 2150547456 HVBatCntctrsOpnIO 10;
BA_ "SignalType" SG_ 2150547456 HVBatCntctrsOpnIO "BLN";
BA_ "SignalLongName" SG_ 2150547456 HVBatCntctrsOpnIO "High Voltage Battery Contactors Open Indication On";
BA_ "VNSigAllNodes" SG_ 2150547456 HVBatCntctrsOpnIO 1;
BA_ "GenSigSendType" SG_ 2150547456 GrnAudQueReq 10;
BA_ "VNSigInfotainment" SG_ 2150547456 GrnAudQueReq 1;
BA_ "SignalType" SG_ 2150547456 GrnAudQueReq "BLN";
BA_ "SignalLongName" SG_ 2150547456 GrnAudQueReq "Green Audio Queue Request";
BA_ "VNSigAllNodes" SG_ 2150547456 GrnAudQueReq 1;
BA_ "GenSigSendType" SG_ 2150547456 SvcHybChrgSysIO 10;
BA_ "VNSigInfotainment" SG_ 2150547456 SvcHybChrgSysIO 1;
BA_ "SignalType" SG_ 2150547456 SvcHybChrgSysIO "BLN";
BA_ "SignalLongName" SG_ 2150547456 SvcHybChrgSysIO "Service Hybrid Charging System Indication On";
BA_ "VNSigAllNodes" SG_ 2150547456 SvcHybChrgSysIO 1;
BA_ "GenSigSendType" SG_ 2150547456 HVChrgrSysStat 10;
BA_ "VNSigInfotainment" SG_ 2150547456 HVChrgrSysStat 1;
BA_ "SignalType" SG_ 2150547456 HVChrgrSysStat "ENM";
BA_ "SignalLongName" SG_ 2150547456 HVChrgrSysStat "High Voltage Charger System Status";
BA_ "VNSigAllNodes" SG_ 2150547456 HVChrgrSysStat 1;
BA_ "GenSigSendType" SG_ 2150547456 HVChrgrCplrStat 10;
BA_ "VNSigInfotainment" SG_ 2150547456 HVChrgrCplrStat 1;
BA_ "SignalType" SG_ 2150547456 HVChrgrCplrStat "ENM";
BA_ "SignalLongName" SG_ 2150547456 HVChrgrCplrStat "High Voltage Charger Coupler Status";
BA_ "VNSigAllNodes" SG_ 2150547456 HVChrgrCplrStat 1;
BA_ "GenSigSendType" SG_ 2150547456 HVBatLimDTmpInd 10;
BA_ "GenSigSendOnInit" SG_ 2150547456 HVBatLimDTmpInd 2;
BA_ "VNSigInfotainment" SG_ 2150547456 HVBatLimDTmpInd 1;
BA_ "SignalType" SG_ 2150547456 HVBatLimDTmpInd "ENM";
BA_ "SignalLongName" SG_ 2150547456 HVBatLimDTmpInd "High Voltage Battery Limitation Due to Temperature Indication";
BA_ "VNSigAllNodes" SG_ 2150547456 HVBatLimDTmpInd 1;
BA_ "GenSigSendType" SG_ 2150547456 HVBatChrgCrdConnIO 10;
BA_ "GenSigSendOnInit" SG_ 2150547456 HVBatChrgCrdConnIO 2;
BA_ "VNSigInfotainment" SG_ 2150547456 HVBatChrgCrdConnIO 1;
BA_ "SignalType" SG_ 2150547456 HVBatChrgCrdConnIO "BLN";
BA_ "SignalLongName" SG_ 2150547456 HVBatChrgCrdConnIO "High Voltage Battery Charge Cord Connected Indication On";
BA_ "VNSigAllNodes" SG_ 2150547456 HVBatChrgCrdConnIO 1;
BA_ "GenSigSendType" SG_ 2150547456 VehChrgMdSt 10;
BA_ "GenSigSendOnInit" SG_ 2150547456 VehChrgMdSt 2;
BA_ "VNSigInfotainment" SG_ 2150547456 VehChrgMdSt 1;
BA_ "SignalType" SG_ 2150547456 VehChrgMdSt "ENM";
BA_ "SignalLongName" SG_ 2150547456 VehChrgMdSt "Vehicle Charge Mode State";
BA_ "VNSigAllNodes" SG_ 2150547456 VehChrgMdSt 1;
BA_ "GenSigDeltaValue" SG_ 2150547456 HVDpltnMdRng 1;
BA_ "GenSigSendType" SG_ 2150547456 HVDpltnMdRng 12;
BA_ "GenSigSendOnInit" SG_ 2150547456 HVDpltnMdRng 1;
BA_ "VNSigInfotainment" SG_ 2150547456 HVDpltnMdRng 1;
BA_ "SignalType" SG_ 2150547456 HVDpltnMdRng "UNM";
BA_ "SignalLongName" SG_ 2150547456 HVDpltnMdRng "High Voltage Depletion Mode Range";
BA_ "VNSigAllNodes" SG_ 2150547456 HVDpltnMdRng 1;
BA_ "GenSigSendType" SG_ 2150547456 ChgrSysAdblIndReq 10;
BA_ "VNSigInfotainment" SG_ 2150547456 ChgrSysAdblIndReq 1;
BA_ "SignalType" SG_ 2150547456 ChgrSysAdblIndReq "ENM";
BA_ "SignalLongName" SG_ 2150547456 ChgrSysAdblIndReq "Charger System Audible Indication Request";
BA_ "VNSigAllNodes" SG_ 2150547456 ChgrSysAdblIndReq 1;
BA_ "SignalType" SG_ 2149752832 SndEnhcmtPerfMdRq "ENM";
BA_ "SignalLongName" SG_ 2149752832 SndEnhcmtPerfMdRq "Sound Enhancement Performance Mode Request";
BA_ "VNSigAllNodes" SG_ 2149752832 SndEnhcmtPerfMdRq 1;
BA_ "SignalType" SG_ 2149752832 SndPerfMdCsStAvl "BLN";
BA_ "SignalLongName" SG_ 2149752832 SndPerfMdCsStAvl "Sound Performance Mode Customization Setting Available";
BA_ "VNSigAllNodes" SG_ 2149752832 SndPerfMdCsStAvl 1;
BA_ "SignalType" SG_ 2149752832 SndPerfMdCsCrStVal "ENM";
BA_ "SignalLongName" SG_ 2149752832 SndPerfMdCsCrStVal "Sound Performance Mode Customization Current Setting Value";
BA_ "VNSigAllNodes" SG_ 2149752832 SndPerfMdCsCrStVal 1;
BA_ "SignalType" SG_ 2149752832 DispPerfMdCsStAvl "BLN";
BA_ "SignalLongName" SG_ 2149752832 DispPerfMdCsStAvl "Display Performance Mode Customization Setting Available";
BA_ "VNSigAllNodes" SG_ 2149752832 DispPerfMdCsStAvl 1;
BA_ "SignalType" SG_ 2149752832 DispPerfMdCsCrStVal "ENM";
BA_ "SignalLongName" SG_ 2149752832 DispPerfMdCsCrStVal "Display Performance Mode Customization Current Setting Value";
BA_ "VNSigAllNodes" SG_ 2149752832 DispPerfMdCsCrStVal 1;
BA_ "SignalType" SG_ 2149752832 HlStrAssActIO "BLN";
BA_ "SignalLongName" SG_ 2149752832 HlStrAssActIO "Hill Start Assist Active Indication On";
BA_ "VNSigAllNodes" SG_ 2149752832 HlStrAssActIO 1;
BA_ "SignalType" SG_ 2149752832 GNCustSetngAvlbl "BLN";
BA_ "SignalLongName" SG_ 2149752832 GNCustSetngAvlbl "Go Notifier Customization Setting Available";
BA_ "VNSigAllNodes" SG_ 2149752832 GNCustSetngAvlbl 1;
BA_ "SignalType" SG_ 2149752832 GNCustCrntStngVal "ENM";
BA_ "SignalLongName" SG_ 2149752832 GNCustCrntStngVal "Go Notifier Customization Current Setting Value";
BA_ "VNSigAllNodes" SG_ 2149752832 GNCustCrntStngVal 1;
BA_ "SignalType" SG_ 2149752832 CPSInfotmntMtReq "ENM";
BA_ "SignalLongName" SG_ 2149752832 CPSInfotmntMtReq "Collision Preparation System Infotainment Mute Request";
BA_ "VNSigAllNodes" SG_ 2149752832 CPSInfotmntMtReq 1;
BA_ "SignalType" SG_ 2149752832 ColPrSysStngAvl "BLN";
BA_ "SignalLongName" SG_ 2149752832 ColPrSysStngAvl "Collision Preparation System Setting Available";
BA_ "VNSigAllNodes" SG_ 2149752832 ColPrSysStngAvl 1;
BA_ "SignalType" SG_ 2149752832 ColPrSysCrntStng "ENM";
BA_ "SignalLongName" SG_ 2149752832 ColPrSysCrntStng "Collision Preparation System Current Setting Value";
BA_ "VNSigAllNodes" SG_ 2149752832 ColPrSysCrntStng 1;
BA_ "SignalType" SG_ 2149752832 HillDscntCntlSysStat "ENM";
BA_ "SignalLongName" SG_ 2149752832 HillDscntCntlSysStat "Hill Descent Control System Status";
BA_ "VNSigAllNodes" SG_ 2149752832 HillDscntCntlSysStat 1;
BA_ "SignalType" SG_ 2149752832 ElecPrkBrkStat "ENM";
BA_ "SignalLongName" SG_ 2149752832 ElecPrkBrkStat "Electric Park Brake Status";
BA_ "VNSigAllNodes" SG_ 2149752832 ElecPrkBrkStat 1;
BA_ "SignalType" SG_ 2149752832 EBDFailed "BLN";
BA_ "SignalLongName" SG_ 2149752832 EBDFailed "Electronic Brake Distribution Failed";
BA_ "VNSigAllNodes" SG_ 2149752832 EBDFailed 1;
BA_ "SignalType" SG_ 2149752832 SusCustStngAvlbl "BLN";
BA_ "SignalLongName" SG_ 2149752832 SusCustStngAvlbl "Suspension Customization Setting Available";
BA_ "VNSigAllNodes" SG_ 2149752832 SusCustStngAvlbl 1;
BA_ "SignalType" SG_ 2149752832 SusCustCurrStngVal "ENM";
BA_ "SignalLongName" SG_ 2149752832 SusCustCurrStngVal "Suspension Customization Current Setting Value";
BA_ "VNSigAllNodes" SG_ 2149752832 SusCustCurrStngVal 1;
BA_ "SignalType" SG_ 2149752832 StrCustStngAvlbl "BLN";
BA_ "SignalLongName" SG_ 2149752832 StrCustStngAvlbl "Steering Customization Setting Available";
BA_ "VNSigAllNodes" SG_ 2149752832 StrCustStngAvlbl 1;
BA_ "SignalType" SG_ 2149752832 StrCustCurrStngVal "ENM";
BA_ "SignalLongName" SG_ 2149752832 StrCustCurrStngVal "Steering Customization Current Setting Value";
BA_ "VNSigAllNodes" SG_ 2149752832 StrCustCurrStngVal 1;
BA_ "SignalType" SG_ 2149752832 DrvlnCustStngAvlbl "BLN";
BA_ "SignalLongName" SG_ 2149752832 DrvlnCustStngAvlbl "Driveline Customization Setting Available";
BA_ "VNSigAllNodes" SG_ 2149752832 DrvlnCustStngAvlbl 1;
BA_ "SignalType" SG_ 2149752832 DrvlnCustCurrStngVal "ENM";
BA_ "SignalLongName" SG_ 2149752832 DrvlnCustCurrStngVal "Driveline Customization Current Setting Value";
BA_ "VNSigAllNodes" SG_ 2149752832 DrvlnCustCurrStngVal 1;
BA_ "SignalType" SG_ 2149752832 ABSAtv "BLN";
BA_ "SignalLongName" SG_ 2149752832 ABSAtv "Antilock Brake System Active";
BA_ "VNSigAllNodes" SG_ 2149752832 ABSAtv 1;
BA_ "SignalType" SG_ 2149752832 PowStVDA "ENM";
BA_ "SignalLongName" SG_ 2149752832 PowStVDA "Power Steering Virtual Device Availability";
BA_ "GenSigStartValue" SG_ 2149752832 PowStVDA 1;
BA_ "VNSigAllNodes" SG_ 2149752832 PowStVDA 1;
BA_ "SignalType" SG_ 2149752832 RrDrCntVDA "ENM";
BA_ "SignalLongName" SG_ 2149752832 RrDrCntVDA "Rear Drive Control Virtual Device Availability";
BA_ "GenSigStartValue" SG_ 2149752832 RrDrCntVDA 1;
BA_ "VNSigAllNodes" SG_ 2149752832 RrDrCntVDA 1;
BA_ "SignalType" SG_ 2149752832 SprTireSt "ENM";
BA_ "SignalLongName" SG_ 2149752832 SprTireSt "Spare Tire Status";
BA_ "VNSigAllNodes" SG_ 2149752832 SprTireSt 1;
BA_ "SignalType" SG_ 2149752832 VehHghtStatV "ENM";
BA_ "SignalLongName" SG_ 2149752832 VehHghtStatV "Vehicle Height Status Validity";
BA_ "VNSigAllNodes" SG_ 2149752832 VehHghtStatV 1;
BA_ "SignalType" SG_ 2149752832 VehHghtStat "ENM";
BA_ "SignalLongName" SG_ 2149752832 VehHghtStat "Vehicle Height Status";
BA_ "VNSigAllNodes" SG_ 2149752832 VehHghtStat 1;
BA_ "SignalType" SG_ 2149752832 BrkSysVDA "ENM";
BA_ "SignalLongName" SG_ 2149752832 BrkSysVDA "Brake System Virtual Device Availability";
BA_ "GenSigStartValue" SG_ 2149752832 BrkSysVDA 1;
BA_ "VNSigAllNodes" SG_ 2149752832 BrkSysVDA 1;
BA_ "SignalType" SG_ 2149752832 IntBrkAssPreFilReq "BLN";
BA_ "SignalLongName" SG_ 2149752832 IntBrkAssPreFilReq "Inteligent Brake Assist Pre-Fil Request";
BA_ "VNSigAllNodes" SG_ 2149752832 IntBrkAssPreFilReq 1;
BA_ "SignalType" SG_ 2149752832 EPBSysDspMsgReq "ENM";
BA_ "SignalLongName" SG_ 2149752832 EPBSysDspMsgReq "Electric Park Brake System Display Message Request";
BA_ "VNSigAllNodes" SG_ 2149752832 EPBSysDspMsgReq 1;
BA_ "SignalType" SG_ 2149752832 EPBSysAudWarnReq "ENM";
BA_ "SignalLongName" SG_ 2149752832 EPBSysAudWarnReq "Electric Park Brake System Audible Warning Request";
BA_ "VNSigAllNodes" SG_ 2149752832 EPBSysAudWarnReq 1;
BA_ "SignalType" SG_ 2149752832 BksOvht "BLN";
BA_ "SignalLongName" SG_ 2149752832 BksOvht "Brakes Overheated";
BA_ "VNSigAllNodes" SG_ 2149752832 BksOvht 1;
BA_ "SignalType" SG_ 2149752832 BrkSysRedBrkTlltlReq "BLN";
BA_ "SignalLongName" SG_ 2149752832 BrkSysRedBrkTlltlReq "Brake System Red Brake Telltale Request";
BA_ "VNSigAllNodes" SG_ 2149752832 BrkSysRedBrkTlltlReq 1;
BA_ "SignalType" SG_ 2149752832 HalfSysFail "BLN";
BA_ "SignalLongName" SG_ 2149752832 HalfSysFail "Half System Failure";
BA_ "VNSigAllNodes" SG_ 2149752832 HalfSysFail 1;
BA_ "SignalType" SG_ 2149752832 PrkBrkVDA "ENM";
BA_ "SignalLongName" SG_ 2149752832 PrkBrkVDA "Park Brake Virtual Device Availability";
BA_ "GenSigStartValue" SG_ 2149752832 PrkBrkVDA 1;
BA_ "VNSigAllNodes" SG_ 2149752832 PrkBrkVDA 1;
BA_ "GenSigSendType" SG_ 2156216320 TxtTelephoneDevPr 10;
BA_ "GenSigSendOnInit" SG_ 2156216320 TxtTelephoneDevPr 2;
BA_ "VNSigInfotainment" SG_ 2156216320 TxtTelephoneDevPr 1;
BA_ "SignalType" SG_ 2156216320 TxtTelephoneDevPr "BLN";
BA_ "SignalLongName" SG_ 2156216320 TxtTelephoneDevPr "Text Telephone Device Present";
BA_ "VNSigAllNodes" SG_ 2156216320 TxtTelephoneDevPr 1;
BA_ "GenSigSendType" SG_ 2158002176 SrvcPrvdr 10;
BA_ "SignalType" SG_ 2158002176 SrvcPrvdr "ENM";
BA_ "SignalLongName" SG_ 2158002176 SrvcPrvdr "Service Provider";
BA_ "VNSigAllNodes" SG_ 2158002176 SrvcPrvdr 1;
BA_ "GenSigSendType" SG_ 2158002176 CurntStnServc 10;
BA_ "SignalType" SG_ 2158002176 CurntStnServc "ENM";
BA_ "SignalLongName" SG_ 2158002176 CurntStnServc "Current Station Service";
BA_ "VNSigAllNodes" SG_ 2158002176 CurntStnServc 1;
BA_ "GenSigDeltaValue" SG_ 2156838912 WSR_WiFiStnMACAddr 1;
BA_ "GenSigSendType" SG_ 2156838912 WSR_WiFiStnMACAddr 12;
BA_ "SignalType" SG_ 2156838912 WSR_WiFiStnMACAddr "UNM";
BA_ "PacketOrder" SG_ 2156838912 WSR_WiFiStnMACAddr 2;
BA_ "SignalLongName" SG_ 2156838912 WSR_WiFiStnMACAddr "WiFi Station Response : WiFi Station Media Access Control Address";
BA_ "VNSigAllNodes" SG_ 2156838912 WSR_WiFiStnMACAddr 1;
BA_ "GenSigSendType" SG_ 2156838912 WSR_WiFiAssnStat 10;
BA_ "SignalType" SG_ 2156838912 WSR_WiFiAssnStat "ENM";
BA_ "PacketOrder" SG_ 2156838912 WSR_WiFiAssnStat 1;
BA_ "SignalLongName" SG_ 2156838912 WSR_WiFiAssnStat "WiFi Station Response : WiFi Association Status";
BA_ "VNSigAllNodes" SG_ 2156838912 WSR_WiFiAssnStat 1;
BA_ "GenSigSendType" SG_ 2156937216 WiFiPssPhrsDgts17to24 10;
BA_ "GenSigSendOnInit" SG_ 2156937216 WiFiPssPhrsDgts17to24 2;
BA_ "SignalType" SG_ 2156937216 WiFiPssPhrsDgts17to24 "ASC";
BA_ "SignalLongName" SG_ 2156937216 WiFiPssPhrsDgts17to24 "WiFi Pass Phrase Digits 17 to 24";
BA_ "VNSigAllNodes" SG_ 2156937216 WiFiPssPhrsDgts17to24 1;
BA_ "GenSigSendType" SG_ 2156929024 WiFiPssPhrsDgts9to16 10;
BA_ "GenSigSendOnInit" SG_ 2156929024 WiFiPssPhrsDgts9to16 2;
BA_ "SignalType" SG_ 2156929024 WiFiPssPhrsDgts9to16 "ASC";
BA_ "SignalLongName" SG_ 2156929024 WiFiPssPhrsDgts9to16 "WiFi Pass Phrase Digits 9 to 16";
BA_ "VNSigAllNodes" SG_ 2156929024 WiFiPssPhrsDgts9to16 1;
BA_ "GenSigSendType" SG_ 2156920832 WiFiPssPhrsDgts1to8 10;
BA_ "GenSigSendOnInit" SG_ 2156920832 WiFiPssPhrsDgts1to8 2;
BA_ "SignalType" SG_ 2156920832 WiFiPssPhrsDgts1to8 "ASC";
BA_ "SignalLongName" SG_ 2156920832 WiFiPssPhrsDgts1to8 "WiFi Pass Phrase Digits 1 to 8";
BA_ "VNSigAllNodes" SG_ 2156920832 WiFiPssPhrsDgts1to8 1;
BA_ "GenSigSendType" SG_ 2156871680 WiFiSSIDDgts17to24 10;
BA_ "GenSigSendOnInit" SG_ 2156871680 WiFiSSIDDgts17to24 2;
BA_ "SignalType" SG_ 2156871680 WiFiSSIDDgts17to24 "ASC";
BA_ "SignalLongName" SG_ 2156871680 WiFiSSIDDgts17to24 "WiFi Service Set Identifier Digits 17 to 24";
BA_ "VNSigAllNodes" SG_ 2156871680 WiFiSSIDDgts17to24 1;
BA_ "GenSigSendType" SG_ 2156863488 WiFiSSIDDgts9to16 10;
BA_ "GenSigSendOnInit" SG_ 2156863488 WiFiSSIDDgts9to16 2;
BA_ "SignalType" SG_ 2156863488 WiFiSSIDDgts9to16 "ASC";
BA_ "SignalLongName" SG_ 2156863488 WiFiSSIDDgts9to16 "WiFi Service Set Identifier Digits 9 to 16";
BA_ "VNSigAllNodes" SG_ 2156863488 WiFiSSIDDgts9to16 1;
BA_ "GenSigSendType" SG_ 2156855296 WiFiSSIDDgts1to8 10;
BA_ "GenSigSendOnInit" SG_ 2156855296 WiFiSSIDDgts1to8 2;
BA_ "SignalType" SG_ 2156855296 WiFiSSIDDgts1to8 "ASC";
BA_ "SignalLongName" SG_ 2156855296 WiFiSSIDDgts1to8 "WiFi Service Set Identifier Digits 1 to 8";
BA_ "VNSigAllNodes" SG_ 2156855296 WiFiSSIDDgts1to8 1;
BA_ "GenSigSendType" SG_ 2156822528 WAPD_EncrptnType 10;
BA_ "GenSigSendOnInit" SG_ 2156822528 WAPD_EncrptnType 2;
BA_ "SignalType" SG_ 2156822528 WAPD_EncrptnType "ENM";
BA_ "PacketOrder" SG_ 2156822528 WAPD_EncrptnType 3;
BA_ "SignalLongName" SG_ 2156822528 WAPD_EncrptnType "WiFi Access Point Data : Encryption Type";
BA_ "VNSigAllNodes" SG_ 2156822528 WAPD_EncrptnType 1;
BA_ "GenSigSendType" SG_ 2156822528 WAPD_SecurityType 10;
BA_ "GenSigSendOnInit" SG_ 2156822528 WAPD_SecurityType 2;
BA_ "SignalType" SG_ 2156822528 WAPD_SecurityType "ENM";
BA_ "PacketOrder" SG_ 2156822528 WAPD_SecurityType 2;
BA_ "SignalLongName" SG_ 2156822528 WAPD_SecurityType "WiFi Access Point Data : Security Type";
BA_ "VNSigAllNodes" SG_ 2156822528 WAPD_SecurityType 1;
BA_ "GenSigSendType" SG_ 2156822528 WAPD_IHUWiFiEnStat 10;
BA_ "GenSigSendOnInit" SG_ 2156822528 WAPD_IHUWiFiEnStat 2;
BA_ "SignalType" SG_ 2156822528 WAPD_IHUWiFiEnStat "ENM";
BA_ "PacketOrder" SG_ 2156822528 WAPD_IHUWiFiEnStat 1;
BA_ "SignalLongName" SG_ 2156822528 WAPD_IHUWiFiEnStat "WiFi Access Point Data : Infotainment Head Unit WiFi Enabled Status";
BA_ "VNSigAllNodes" SG_ 2156822528 WAPD_IHUWiFiEnStat 1;
BA_ "GenSigDeltaValue" SG_ 2149883904 BTPR_RspVal 1;
BA_ "GenSigSendType" SG_ 2149883904 BTPR_RspVal 12;
BA_ "SignalType" SG_ 2149883904 BTPR_RspVal "UNM";
BA_ "PacketOrder" SG_ 2149883904 BTPR_RspVal 3;
BA_ "SignalLongName" SG_ 2149883904 BTPR_RspVal "Bluetooth Tethering Pairing Response : Response Value";
BA_ "VNSigAllNodes" SG_ 2149883904 BTPR_RspVal 1;
BA_ "GenSigSendType" SG_ 2149883904 BTPR_RspInfoAvail 10;
BA_ "SignalType" SG_ 2149883904 BTPR_RspInfoAvail "BLN";
BA_ "PacketOrder" SG_ 2149883904 BTPR_RspInfoAvail 2;
BA_ "SignalLongName" SG_ 2149883904 BTPR_RspInfoAvail "Bluetooth Tethering Pairing Response : Response Information Available";
BA_ "VNSigAllNodes" SG_ 2149883904 BTPR_RspInfoAvail 1;
BA_ "GenSigSendType" SG_ 2149883904 BTPR_RspStat 10;
BA_ "SignalType" SG_ 2149883904 BTPR_RspStat "ENM";
BA_ "PacketOrder" SG_ 2149883904 BTPR_RspStat 1;
BA_ "SignalLongName" SG_ 2149883904 BTPR_RspStat "Bluetooth Tethering Pairing Response : Response Status";
BA_ "VNSigAllNodes" SG_ 2149883904 BTPR_RspStat 1;
BA_ "GenSigDeltaValue" SG_ 2152038400 InfMdRspPld 1;
BA_ "GenSigSendType" SG_ 2152038400 InfMdRspPld 12;
BA_ "VNSigInfotainment" SG_ 2152038400 InfMdRspPld 1;
BA_ "SignalType" SG_ 2152038400 InfMdRspPld "UNM";
BA_ "SignalLongName" SG_ 2152038400 InfMdRspPld "Infomatics Metadata Response Payload";
BA_ "VNSigAllNodes" SG_ 2152038400 InfMdRspPld 1;
BA_ "GenSigSendType" SG_ 2151874560 RstVTDTmprDtctd 10;
BA_ "SignalType" SG_ 2151874560 RstVTDTmprDtctd "ENM";
BA_ "SignalLongName" SG_ 2151874560 RstVTDTmprDtctd "Reset Vehicle Theft Deterrent Tamper Detected";
BA_ "VNSigAllNodes" SG_ 2151874560 RstVTDTmprDtctd 1;
BA_ "GenSigSendType" SG_ 2151874560 RstIllDrIdDevDtctd 10;
BA_ "SignalType" SG_ 2151874560 RstIllDrIdDevDtctd "ENM";
BA_ "SignalLongName" SG_ 2151874560 RstIllDrIdDevDtctd "Reset Illegitimate Driver Identification Device Detected";
BA_ "VNSigAllNodes" SG_ 2151874560 RstIllDrIdDevDtctd 1;
BA_ "GenSigSendType" SG_ 2151874560 RstDrIdDevLrnd 10;
BA_ "SignalType" SG_ 2151874560 RstDrIdDevLrnd "ENM";
BA_ "SignalLongName" SG_ 2151874560 RstDrIdDevLrnd "Reset Driver Identification Device Learned";
BA_ "VNSigAllNodes" SG_ 2151874560 RstDrIdDevLrnd 1;
BA_ "GenSigSendType" SG_ 2151874560 ESEIC_EngImRqPsw 10;
BA_ "SignalType" SG_ 2151874560 ESEIC_EngImRqPsw "ASC";
BA_ "PacketOrder" SG_ 2151874560 ESEIC_EngImRqPsw 2;
BA_ "SignalLongName" SG_ 2151874560 ESEIC_EngImRqPsw "Enhanced Services Engine Immobilization Command : Enhanced Services Engine Immobilization Request Password";
BA_ "VNSigAllNodes" SG_ 2151874560 ESEIC_EngImRqPsw 1;
BA_ "GenSigSendType" SG_ 2151874560 ESEIC_EngImmbRq 10;
BA_ "SignalType" SG_ 2151874560 ESEIC_EngImmbRq "ENM";
BA_ "PacketOrder" SG_ 2151874560 ESEIC_EngImmbRq 1;
BA_ "SignalLongName" SG_ 2151874560 ESEIC_EngImmbRq "Enhanced Services Engine Immobilization Command : Enhanced Services Engine Immobilization Request";
BA_ "VNSigAllNodes" SG_ 2151874560 ESEIC_EngImmbRq 1;
BA_ "GenSigSendType" SG_ 2151383040 TreInfMonSysRstReq 10;
BA_ "SignalType" SG_ 2151383040 TreInfMonSysRstReq "BLN";
BA_ "SignalLongName" SG_ 2151383040 TreInfMonSysRstReq "Tire Inflation Monitoring System Reset Requested";
BA_ "VNSigAllNodes" SG_ 2151383040 TreInfMonSysRstReq 1;
BA_ "GenSigSendType" SG_ 2149900288 BTTethrngPrngReq 10;
BA_ "SignalType" SG_ 2149900288 BTTethrngPrngReq "ENM";
BA_ "SignalLongName" SG_ 2149900288 BTTethrngPrngReq "Bluetooth Tethering Pairing Request";
BA_ "VNSigAllNodes" SG_ 2149900288 BTTethrngPrngReq 1;
BA_ "GenSigSendType" SG_ 2149900288 EnhSrvAudAlRq 10;
BA_ "SignalType" SG_ 2149900288 EnhSrvAudAlRq "ENM";
BA_ "SignalLongName" SG_ 2149900288 EnhSrvAudAlRq "Enhanced Services Audible External Alert Request";
BA_ "VNSigAllNodes" SG_ 2149900288 EnhSrvAudAlRq 1;
BA_ "GenSigDeltaValue" SG_ 2149900288 EnhSvVehTopSpdLim 1;
BA_ "GenSigSendType" SG_ 2149900288 EnhSvVehTopSpdLim 12;
BA_ "SignalType" SG_ 2149900288 EnhSvVehTopSpdLim "UNM";
BA_ "SignalLongName" SG_ 2149900288 EnhSvVehTopSpdLim "Enhanced Services Vehicle Top Speed Limit Value";
BA_ "GenSigStartValue" SG_ 2149900288 EnhSvVehTopSpdLim 255;
BA_ "VNSigAllNodes" SG_ 2149900288 EnhSvVehTopSpdLim 1;
BA_ "GenSigSendType" SG_ 2149900288 EnhSrvVisAlRq 10;
BA_ "GenSigSendOnInit" SG_ 2149900288 EnhSrvVisAlRq 1;
BA_ "SignalType" SG_ 2149900288 EnhSrvVisAlRq "ENM";
BA_ "SignalLongName" SG_ 2149900288 EnhSrvVisAlRq "Enhanced Services Visible External Alert Request";
BA_ "VNSigAllNodes" SG_ 2149900288 EnhSrvVisAlRq 1;
BA_ "GenSigSendType" SG_ 2149900288 EnhSrvRmStrtRq 10;
BA_ "SignalType" SG_ 2149900288 EnhSrvRmStrtRq "ENM";
BA_ "SignalLongName" SG_ 2149900288 EnhSrvRmStrtRq "Enhanced Services Remote Start Request";
BA_ "VNSigAllNodes" SG_ 2149900288 EnhSrvRmStrtRq 1;
BA_ "GenSigSendType" SG_ 2149900288 EnhSrvRClsRlsRq 10;
BA_ "SignalType" SG_ 2149900288 EnhSrvRClsRlsRq "ENM";
BA_ "SignalLongName" SG_ 2149900288 EnhSrvRClsRlsRq "Enhanced Services Rear Closure Release Request";
BA_ "VNSigAllNodes" SG_ 2149900288 EnhSrvRClsRlsRq 1;
BA_ "GenSigSendType" SG_ 2149900288 EnhSrvLckRq 10;
BA_ "SignalType" SG_ 2149900288 EnhSrvLckRq "ENM";
BA_ "SignalLongName" SG_ 2149900288 EnhSrvLckRq "Enhanced Services Locking Request";
BA_ "VNSigAllNodes" SG_ 2149900288 EnhSrvLckRq 1;
BA_ "GenSigSendType" SG_ 2158985216 ODDMO_ReqType 10;
BA_ "VNSigInfotainment" SG_ 2158985216 ODDMO_ReqType 1;
BA_ "SignalType" SG_ 2158985216 ODDMO_ReqType "ENM";
BA_ "PacketOrder" SG_ 2158985216 ODDMO_ReqType 1;
BA_ "SignalLongName" SG_ 2158985216 ODDMO_ReqType "Open Display Interface Dynamic Data Multi Request OTIM : Request Type";
BA_ "VNSigAllNodes" SG_ 2158985216 ODDMO_ReqType 1;
BA_ "GenSigDeltaValue" SG_ 2158985216 ODDMO_FUCID 1;
BA_ "GenSigSendType" SG_ 2158985216 ODDMO_FUCID 12;
BA_ "VNSigInfotainment" SG_ 2158985216 ODDMO_FUCID 1;
BA_ "SignalType" SG_ 2158985216 ODDMO_FUCID "UNM";
BA_ "PacketOrder" SG_ 2158985216 ODDMO_FUCID 6;
BA_ "SignalLongName" SG_ 2158985216 ODDMO_FUCID "Open Display Interface Dynamic Data Multi Request OTIM : Functional Unit Class ID";
BA_ "VNSigAllNodes" SG_ 2158985216 ODDMO_FUCID 1;
BA_ "GenSigSendType" SG_ 2158985216 ODDMO_DispMID 10;
BA_ "VNSigInfotainment" SG_ 2158985216 ODDMO_DispMID 1;
BA_ "SignalType" SG_ 2158985216 ODDMO_DispMID "ENM";
BA_ "PacketOrder" SG_ 2158985216 ODDMO_DispMID 7;
BA_ "SignalLongName" SG_ 2158985216 ODDMO_DispMID "Open Display Interface Dynamic Data Multi Request OTIM : Display Mask Id";
BA_ "VNSigAllNodes" SG_ 2158985216 ODDMO_DispMID 1;
BA_ "GenSigSendType" SG_ 2158985216 ODDMO_DataID2Vld 10;
BA_ "VNSigInfotainment" SG_ 2158985216 ODDMO_DataID2Vld 1;
BA_ "SignalType" SG_ 2158985216 ODDMO_DataID2Vld "BLN";
BA_ "PacketOrder" SG_ 2158985216 ODDMO_DataID2Vld 5;
BA_ "SignalLongName" SG_ 2158985216 ODDMO_DataID2Vld "Open Display Interface Dynamic Data Multi Request OTIM : Data ID Two Valid";
BA_ "VNSigAllNodes" SG_ 2158985216 ODDMO_DataID2Vld 1;
BA_ "GenSigDeltaValue" SG_ 2158985216 ODDMO_DataID2 1;
BA_ "GenSigSendType" SG_ 2158985216 ODDMO_DataID2 12;
BA_ "VNSigInfotainment" SG_ 2158985216 ODDMO_DataID2 1;
BA_ "SignalType" SG_ 2158985216 ODDMO_DataID2 "UNM";
BA_ "PacketOrder" SG_ 2158985216 ODDMO_DataID2 9;
BA_ "SignalLongName" SG_ 2158985216 ODDMO_DataID2 "Open Display Interface Dynamic Data Multi Request OTIM : Data ID Two";
BA_ "VNSigAllNodes" SG_ 2158985216 ODDMO_DataID2 1;
BA_ "GenSigSendType" SG_ 2158985216 ODDMO_DataID3Vld 10;
BA_ "VNSigInfotainment" SG_ 2158985216 ODDMO_DataID3Vld 1;
BA_ "SignalType" SG_ 2158985216 ODDMO_DataID3Vld "BLN";
BA_ "PacketOrder" SG_ 2158985216 ODDMO_DataID3Vld 4;
BA_ "SignalLongName" SG_ 2158985216 ODDMO_DataID3Vld "Open Display Interface Dynamic Data Multi Request OTIM : Data ID Three Valid";
BA_ "VNSigAllNodes" SG_ 2158985216 ODDMO_DataID3Vld 1;
BA_ "GenSigDeltaValue" SG_ 2158985216 ODDMO_DataID3 1;
BA_ "GenSigSendType" SG_ 2158985216 ODDMO_DataID3 12;
BA_ "VNSigInfotainment" SG_ 2158985216 ODDMO_DataID3 1;
BA_ "SignalType" SG_ 2158985216 ODDMO_DataID3 "UNM";
BA_ "PacketOrder" SG_ 2158985216 ODDMO_DataID3 10;
BA_ "SignalLongName" SG_ 2158985216 ODDMO_DataID3 "Open Display Interface Dynamic Data Multi Request OTIM : Data ID Three";
BA_ "VNSigAllNodes" SG_ 2158985216 ODDMO_DataID3 1;
BA_ "GenSigDeltaValue" SG_ 2158985216 ODDMO_DataID1 1;
BA_ "GenSigSendType" SG_ 2158985216 ODDMO_DataID1 12;
BA_ "VNSigInfotainment" SG_ 2158985216 ODDMO_DataID1 1;
BA_ "SignalType" SG_ 2158985216 ODDMO_DataID1 "UNM";
BA_ "PacketOrder" SG_ 2158985216 ODDMO_DataID1 8;
BA_ "SignalLongName" SG_ 2158985216 ODDMO_DataID1 "Open Display Interface Dynamic Data Multi Request OTIM : Data ID One";
BA_ "VNSigAllNodes" SG_ 2158985216 ODDMO_DataID1 1;
BA_ "GenSigSendType" SG_ 2158985216 ODDMO_DataID4Vld 10;
BA_ "VNSigInfotainment" SG_ 2158985216 ODDMO_DataID4Vld 1;
BA_ "SignalType" SG_ 2158985216 ODDMO_DataID4Vld "BLN";
BA_ "PacketOrder" SG_ 2158985216 ODDMO_DataID4Vld 3;
BA_ "SignalLongName" SG_ 2158985216 ODDMO_DataID4Vld "Open Display Interface Dynamic Data Multi Request OTIM : Data ID Four Valid";
BA_ "VNSigAllNodes" SG_ 2158985216 ODDMO_DataID4Vld 1;
BA_ "GenSigDeltaValue" SG_ 2158985216 ODDMO_DataID4 1;
BA_ "GenSigSendType" SG_ 2158985216 ODDMO_DataID4 12;
BA_ "VNSigInfotainment" SG_ 2158985216 ODDMO_DataID4 1;
BA_ "SignalType" SG_ 2158985216 ODDMO_DataID4 "UNM";
BA_ "PacketOrder" SG_ 2158985216 ODDMO_DataID4 11;
BA_ "SignalLongName" SG_ 2158985216 ODDMO_DataID4 "Open Display Interface Dynamic Data Multi Request OTIM : Data ID Four";
BA_ "VNSigAllNodes" SG_ 2158985216 ODDMO_DataID4 1;
BA_ "GenSigSendType" SG_ 2158985216 ODDMO_DataID5Vld 10;
BA_ "VNSigInfotainment" SG_ 2158985216 ODDMO_DataID5Vld 1;
BA_ "SignalType" SG_ 2158985216 ODDMO_DataID5Vld "BLN";
BA_ "PacketOrder" SG_ 2158985216 ODDMO_DataID5Vld 2;
BA_ "SignalLongName" SG_ 2158985216 ODDMO_DataID5Vld "Open Display Interface Dynamic Data Multi Request OTIM : Data ID Five Valid";
BA_ "VNSigAllNodes" SG_ 2158985216 ODDMO_DataID5Vld 1;
BA_ "GenSigDeltaValue" SG_ 2158985216 ODDMO_DataID5 1;
BA_ "GenSigSendType" SG_ 2158985216 ODDMO_DataID5 12;
BA_ "VNSigInfotainment" SG_ 2158985216 ODDMO_DataID5 1;
BA_ "SignalType" SG_ 2158985216 ODDMO_DataID5 "UNM";
BA_ "PacketOrder" SG_ 2158985216 ODDMO_DataID5 12;
BA_ "SignalLongName" SG_ 2158985216 ODDMO_DataID5 "Open Display Interface Dynamic Data Multi Request OTIM : Data ID Five";
BA_ "VNSigAllNodes" SG_ 2158985216 ODDMO_DataID5 1;
BA_ "GenSigDeltaValue" SG_ 2158862336 ODIAOT_FUCID 1;
BA_ "GenSigSendType" SG_ 2158862336 ODIAOT_FUCID 12;
BA_ "VNSigInfotainment" SG_ 2158862336 ODIAOT_FUCID 1;
BA_ "SignalType" SG_ 2158862336 ODIAOT_FUCID "UNM";
BA_ "PacketOrder" SG_ 2158862336 ODIAOT_FUCID 2;
BA_ "SignalLongName" SG_ 2158862336 ODIAOT_FUCID "Open Display Interface Action OTIM : FU Class ID";
BA_ "VNSigAllNodes" SG_ 2158862336 ODIAOT_FUCID 1;
BA_ "GenSigSendType" SG_ 2158862336 ODIAOT_DspMID 10;
BA_ "VNSigInfotainment" SG_ 2158862336 ODIAOT_DspMID 1;
BA_ "SignalType" SG_ 2158862336 ODIAOT_DspMID "ENM";
BA_ "PacketOrder" SG_ 2158862336 ODIAOT_DspMID 4;
BA_ "SignalLongName" SG_ 2158862336 ODIAOT_DspMID "Open Display Interface Action OTIM : Display Mask ID";
BA_ "VNSigAllNodes" SG_ 2158862336 ODIAOT_DspMID 1;
BA_ "GenSigSendType" SG_ 2158862336 ODIAOT_DaTy 10;
BA_ "VNSigInfotainment" SG_ 2158862336 ODIAOT_DaTy 1;
BA_ "SignalType" SG_ 2158862336 ODIAOT_DaTy "ENM";
BA_ "PacketOrder" SG_ 2158862336 ODIAOT_DaTy 1;
BA_ "SignalLongName" SG_ 2158862336 ODIAOT_DaTy "Open Display Interface Action OTIM : DataType";
BA_ "VNSigAllNodes" SG_ 2158862336 ODIAOT_DaTy 1;
BA_ "GenSigDeltaValue" SG_ 2158862336 ODIAOT_ActnVal 1;
BA_ "GenSigSendType" SG_ 2158862336 ODIAOT_ActnVal 12;
BA_ "VNSigInfotainment" SG_ 2158862336 ODIAOT_ActnVal 1;
BA_ "SignalType" SG_ 2158862336 ODIAOT_ActnVal "UNM";
BA_ "PacketOrder" SG_ 2158862336 ODIAOT_ActnVal 5;
BA_ "SignalLongName" SG_ 2158862336 ODIAOT_ActnVal "Open Display Interface Action OTIM : Action Value";
BA_ "VNSigAllNodes" SG_ 2158862336 ODIAOT_ActnVal 1;
BA_ "GenSigDeltaValue" SG_ 2158862336 ODIAOT_ActnID 1;
BA_ "GenSigSendType" SG_ 2158862336 ODIAOT_ActnID 12;
BA_ "VNSigInfotainment" SG_ 2158862336 ODIAOT_ActnID 1;
BA_ "SignalType" SG_ 2158862336 ODIAOT_ActnID "UNM";
BA_ "PacketOrder" SG_ 2158862336 ODIAOT_ActnID 3;
BA_ "SignalLongName" SG_ 2158862336 ODIAOT_ActnID "Open Display Interface Action OTIM : Action ID";
BA_ "VNSigAllNodes" SG_ 2158862336 ODIAOT_ActnID 1;
BA_ "GenSigDeltaValue" SG_ 2159157248 ODI_CntrStck2TEL 1;
BA_ "GenSigSendType" SG_ 2159157248 ODI_CntrStck2TEL 12;
BA_ "VNSigInfotainment" SG_ 2159157248 ODI_CntrStck2TEL 1;
BA_ "SignalType" SG_ 2159157248 ODI_CntrStck2TEL "UNM";
BA_ "SignalLongName" SG_ 2159157248 ODI_CntrStck2TEL "Open Display Interface CenterStack 2 TEL";
BA_ "VNSigAllNodes" SG_ 2159157248 ODI_CntrStck2TEL 1;
BA_ "GenSigDeltaValue" SG_ 2159091712 ODI_IPC2TEL 1;
BA_ "GenSigSendType" SG_ 2159091712 ODI_IPC2TEL 12;
BA_ "VNSigInfotainment" SG_ 2159091712 ODI_IPC2TEL 1;
BA_ "SignalType" SG_ 2159091712 ODI_IPC2TEL "UNM";
BA_ "SignalLongName" SG_ 2159091712 ODI_IPC2TEL "Open Display Interface IPC 2 TEL";
BA_ "VNSigAllNodes" SG_ 2159091712 ODI_IPC2TEL 1;
BA_ "GenSigDeltaValue" SG_ 2158886912 ODDLI_SubIdReqM 1;
BA_ "GenSigSendType" SG_ 2158886912 ODDLI_SubIdReqM 12;
BA_ "VNSigInfotainment" SG_ 2158886912 ODDLI_SubIdReqM 1;
BA_ "SignalType" SG_ 2158886912 ODDLI_SubIdReqM "UNM";
BA_ "PacketOrder" SG_ 2158886912 ODDLI_SubIdReqM 10;
BA_ "SignalLongName" SG_ 2158886912 ODDLI_SubIdReqM "Open Display Interface Dynamic Data List Request IPC : Sub Id Request Mask";
BA_ "VNSigAllNodes" SG_ 2158886912 ODDLI_SubIdReqM 1;
BA_ "GenSigSendType" SG_ 2158886912 ODDLI_WrpArnd 10;
BA_ "VNSigInfotainment" SG_ 2158886912 ODDLI_WrpArnd 1;
BA_ "SignalType" SG_ 2158886912 ODDLI_WrpArnd "BLN";
BA_ "PacketOrder" SG_ 2158886912 ODDLI_WrpArnd 9;
BA_ "SignalLongName" SG_ 2158886912 ODDLI_WrpArnd "Open Display Interface Dynamic Data List Request IPC : Wrap Around";
BA_ "VNSigAllNodes" SG_ 2158886912 ODDLI_WrpArnd 1;
BA_ "GenSigSendType" SG_ 2158886912 ODDLI_ReqType 10;
BA_ "VNSigInfotainment" SG_ 2158886912 ODDLI_ReqType 1;
BA_ "SignalType" SG_ 2158886912 ODDLI_ReqType "ENM";
BA_ "PacketOrder" SG_ 2158886912 ODDLI_ReqType 7;
BA_ "SignalLongName" SG_ 2158886912 ODDLI_ReqType "Open Display Interface Dynamic Data List Request IPC : Request Type";
BA_ "VNSigAllNodes" SG_ 2158886912 ODDLI_ReqType 1;
BA_ "GenSigSendType" SG_ 2158886912 ODDLI_ReqDir 10;
BA_ "VNSigInfotainment" SG_ 2158886912 ODDLI_ReqDir 1;
BA_ "SignalType" SG_ 2158886912 ODDLI_ReqDir "BLN";
BA_ "PacketOrder" SG_ 2158886912 ODDLI_ReqDir 5;
BA_ "SignalLongName" SG_ 2158886912 ODDLI_ReqDir "Open Display Interface Dynamic Data List Request IPC : Req Direction";
BA_ "VNSigAllNodes" SG_ 2158886912 ODDLI_ReqDir 1;
BA_ "GenSigDeltaValue" SG_ 2158886912 ODDLI_NmEntries 1;
BA_ "GenSigSendType" SG_ 2158886912 ODDLI_NmEntries 12;
BA_ "VNSigInfotainment" SG_ 2158886912 ODDLI_NmEntries 1;
BA_ "SignalType" SG_ 2158886912 ODDLI_NmEntries "UNM";
BA_ "PacketOrder" SG_ 2158886912 ODDLI_NmEntries 4;
BA_ "SignalLongName" SG_ 2158886912 ODDLI_NmEntries "Open Display Interface Dynamic Data List Request IPC : Num Entries";
BA_ "VNSigAllNodes" SG_ 2158886912 ODDLI_NmEntries 1;
BA_ "GenSigDeltaValue" SG_ 2158886912 ODDLI_Idx 1;
BA_ "GenSigSendType" SG_ 2158886912 ODDLI_Idx 12;
BA_ "VNSigInfotainment" SG_ 2158886912 ODDLI_Idx 1;
BA_ "SignalType" SG_ 2158886912 ODDLI_Idx "UNM";
BA_ "PacketOrder" SG_ 2158886912 ODDLI_Idx 6;
BA_ "SignalLongName" SG_ 2158886912 ODDLI_Idx "Open Display Interface Dynamic Data List Request IPC : Index";
BA_ "VNSigAllNodes" SG_ 2158886912 ODDLI_Idx 1;
BA_ "GenSigDeltaValue" SG_ 2158886912 ODDLI_FUCID 1;
BA_ "GenSigSendType" SG_ 2158886912 ODDLI_FUCID 12;
BA_ "VNSigInfotainment" SG_ 2158886912 ODDLI_FUCID 1;
BA_ "SignalType" SG_ 2158886912 ODDLI_FUCID "UNM";
BA_ "PacketOrder" SG_ 2158886912 ODDLI_FUCID 1;
BA_ "SignalLongName" SG_ 2158886912 ODDLI_FUCID "Open Display Interface Dynamic Data List Request IPC : Functional Unit Class ID";
BA_ "VNSigAllNodes" SG_ 2158886912 ODDLI_FUCID 1;
BA_ "GenSigSendType" SG_ 2158886912 ODDLI_DspMID 10;
BA_ "VNSigInfotainment" SG_ 2158886912 ODDLI_DspMID 1;
BA_ "SignalType" SG_ 2158886912 ODDLI_DspMID "ENM";
BA_ "PacketOrder" SG_ 2158886912 ODDLI_DspMID 3;
BA_ "SignalLongName" SG_ 2158886912 ODDLI_DspMID "Open Display Interface Dynamic Data List Request IPC : Display Mask Id";
BA_ "VNSigAllNodes" SG_ 2158886912 ODDLI_DspMID 1;
BA_ "GenSigDeltaValue" SG_ 2158886912 ODDLI_DataId 1;
BA_ "GenSigSendType" SG_ 2158886912 ODDLI_DataId 12;
BA_ "VNSigInfotainment" SG_ 2158886912 ODDLI_DataId 1;
BA_ "SignalType" SG_ 2158886912 ODDLI_DataId "UNM";
BA_ "PacketOrder" SG_ 2158886912 ODDLI_DataId 2;
BA_ "SignalLongName" SG_ 2158886912 ODDLI_DataId "Open Display Interface Dynamic Data List Request IPC : Data Id";
BA_ "VNSigAllNodes" SG_ 2158886912 ODDLI_DataId 1;
BA_ "GenSigSendType" SG_ 2158886912 ODDLI_BckgndFlag 10;
BA_ "VNSigInfotainment" SG_ 2158886912 ODDLI_BckgndFlag 1;
BA_ "SignalType" SG_ 2158886912 ODDLI_BckgndFlag "ENM";
BA_ "PacketOrder" SG_ 2158886912 ODDLI_BckgndFlag 8;
BA_ "SignalLongName" SG_ 2158886912 ODDLI_BckgndFlag "Open Display Interface Dynamic Data List Request IPC : Background Flag";
BA_ "VNSigAllNodes" SG_ 2158886912 ODDLI_BckgndFlag 1;
BA_ "GenSigSendType" SG_ 2158854144 ODIAI_DaTy 10;
BA_ "VNSigInfotainment" SG_ 2158854144 ODIAI_DaTy 1;
BA_ "SignalType" SG_ 2158854144 ODIAI_DaTy "ENM";
BA_ "PacketOrder" SG_ 2158854144 ODIAI_DaTy 1;
BA_ "SignalLongName" SG_ 2158854144 ODIAI_DaTy "Open Display Interface Action IPC : DataType";
BA_ "VNSigAllNodes" SG_ 2158854144 ODIAI_DaTy 1;
BA_ "GenSigDeltaValue" SG_ 2158854144 ODIAI_FUCID 1;
BA_ "GenSigSendType" SG_ 2158854144 ODIAI_FUCID 12;
BA_ "VNSigInfotainment" SG_ 2158854144 ODIAI_FUCID 1;
BA_ "SignalType" SG_ 2158854144 ODIAI_FUCID "UNM";
BA_ "PacketOrder" SG_ 2158854144 ODIAI_FUCID 2;
BA_ "SignalLongName" SG_ 2158854144 ODIAI_FUCID "Open Display Interface Action IPC : FU Class ID";
BA_ "VNSigAllNodes" SG_ 2158854144 ODIAI_FUCID 1;
BA_ "GenSigSendType" SG_ 2158854144 ODIAI_DspMID 10;
BA_ "VNSigInfotainment" SG_ 2158854144 ODIAI_DspMID 1;
BA_ "SignalType" SG_ 2158854144 ODIAI_DspMID "ENM";
BA_ "PacketOrder" SG_ 2158854144 ODIAI_DspMID 4;
BA_ "SignalLongName" SG_ 2158854144 ODIAI_DspMID "Open Display Interface Action IPC : Display Mask ID";
BA_ "VNSigAllNodes" SG_ 2158854144 ODIAI_DspMID 1;
BA_ "GenSigDeltaValue" SG_ 2158854144 ODIAI_ActnVal 1;
BA_ "GenSigSendType" SG_ 2158854144 ODIAI_ActnVal 12;
BA_ "VNSigInfotainment" SG_ 2158854144 ODIAI_ActnVal 1;
BA_ "SignalType" SG_ 2158854144 ODIAI_ActnVal "UNM";
BA_ "PacketOrder" SG_ 2158854144 ODIAI_ActnVal 5;
BA_ "SignalLongName" SG_ 2158854144 ODIAI_ActnVal "Open Display Interface Action IPC : Action Value";
BA_ "VNSigAllNodes" SG_ 2158854144 ODIAI_ActnVal 1;
BA_ "GenSigDeltaValue" SG_ 2158854144 ODIAI_ActnID 1;
BA_ "GenSigSendType" SG_ 2158854144 ODIAI_ActnID 12;
BA_ "VNSigInfotainment" SG_ 2158854144 ODIAI_ActnID 1;
BA_ "SignalType" SG_ 2158854144 ODIAI_ActnID "UNM";
BA_ "PacketOrder" SG_ 2158854144 ODIAI_ActnID 3;
BA_ "SignalLongName" SG_ 2158854144 ODIAI_ActnID "Open Display Interface Action IPC : Action ID";
BA_ "VNSigAllNodes" SG_ 2158854144 ODIAI_ActnID 1;
BA_ "GenSigSendType" SG_ 2158919680 ODDMI_ReqType 10;
BA_ "VNSigInfotainment" SG_ 2158919680 ODDMI_ReqType 1;
BA_ "SignalType" SG_ 2158919680 ODDMI_ReqType "ENM";
BA_ "PacketOrder" SG_ 2158919680 ODDMI_ReqType 1;
BA_ "SignalLongName" SG_ 2158919680 ODDMI_ReqType "Open Display Interface Dynamic Data Multi Request IPC : Request Type";
BA_ "VNSigAllNodes" SG_ 2158919680 ODDMI_ReqType 1;
BA_ "GenSigDeltaValue" SG_ 2158919680 ODDMI_FUCID 1;
BA_ "GenSigSendType" SG_ 2158919680 ODDMI_FUCID 12;
BA_ "VNSigInfotainment" SG_ 2158919680 ODDMI_FUCID 1;
BA_ "SignalType" SG_ 2158919680 ODDMI_FUCID "UNM";
BA_ "PacketOrder" SG_ 2158919680 ODDMI_FUCID 6;
BA_ "SignalLongName" SG_ 2158919680 ODDMI_FUCID "Open Display Interface Dynamic Data Multi Request IPC : Functional Unit Class ID";
BA_ "VNSigAllNodes" SG_ 2158919680 ODDMI_FUCID 1;
BA_ "GenSigSendType" SG_ 2158919680 ODDMI_DispMID 10;
BA_ "VNSigInfotainment" SG_ 2158919680 ODDMI_DispMID 1;
BA_ "SignalType" SG_ 2158919680 ODDMI_DispMID "ENM";
BA_ "PacketOrder" SG_ 2158919680 ODDMI_DispMID 7;
BA_ "SignalLongName" SG_ 2158919680 ODDMI_DispMID "Open Display Interface Dynamic Data Multi Request IPC : Display Mask Id";
BA_ "VNSigAllNodes" SG_ 2158919680 ODDMI_DispMID 1;
BA_ "GenSigSendType" SG_ 2158919680 ODDMI_DataID2Vld 10;
BA_ "VNSigInfotainment" SG_ 2158919680 ODDMI_DataID2Vld 1;
BA_ "SignalType" SG_ 2158919680 ODDMI_DataID2Vld "BLN";
BA_ "PacketOrder" SG_ 2158919680 ODDMI_DataID2Vld 5;
BA_ "SignalLongName" SG_ 2158919680 ODDMI_DataID2Vld "Open Display Interface Dynamic Data Multi Request IPC : Data ID Two Valid";
BA_ "VNSigAllNodes" SG_ 2158919680 ODDMI_DataID2Vld 1;
BA_ "GenSigDeltaValue" SG_ 2158919680 ODDMI_DataID2 1;
BA_ "GenSigSendType" SG_ 2158919680 ODDMI_DataID2 12;
BA_ "VNSigInfotainment" SG_ 2158919680 ODDMI_DataID2 1;
BA_ "SignalType" SG_ 2158919680 ODDMI_DataID2 "UNM";
BA_ "PacketOrder" SG_ 2158919680 ODDMI_DataID2 9;
BA_ "SignalLongName" SG_ 2158919680 ODDMI_DataID2 "Open Display Interface Dynamic Data Multi Request IPC : Data ID Two";
BA_ "VNSigAllNodes" SG_ 2158919680 ODDMI_DataID2 1;
BA_ "GenSigSendType" SG_ 2158919680 ODDMI_DataID3Vld 10;
BA_ "VNSigInfotainment" SG_ 2158919680 ODDMI_DataID3Vld 1;
BA_ "SignalType" SG_ 2158919680 ODDMI_DataID3Vld "BLN";
BA_ "PacketOrder" SG_ 2158919680 ODDMI_DataID3Vld 4;
BA_ "SignalLongName" SG_ 2158919680 ODDMI_DataID3Vld "Open Display Interface Dynamic Data Multi Request IPC : Data ID Three Valid";
BA_ "VNSigAllNodes" SG_ 2158919680 ODDMI_DataID3Vld 1;
BA_ "GenSigDeltaValue" SG_ 2158919680 ODDMI_DataID3 1;
BA_ "GenSigSendType" SG_ 2158919680 ODDMI_DataID3 12;
BA_ "VNSigInfotainment" SG_ 2158919680 ODDMI_DataID3 1;
BA_ "SignalType" SG_ 2158919680 ODDMI_DataID3 "UNM";
BA_ "PacketOrder" SG_ 2158919680 ODDMI_DataID3 10;
BA_ "SignalLongName" SG_ 2158919680 ODDMI_DataID3 "Open Display Interface Dynamic Data Multi Request IPC : Data ID Three";
BA_ "VNSigAllNodes" SG_ 2158919680 ODDMI_DataID3 1;
BA_ "GenSigDeltaValue" SG_ 2158919680 ODDMI_DataID1 1;
BA_ "GenSigSendType" SG_ 2158919680 ODDMI_DataID1 12;
BA_ "VNSigInfotainment" SG_ 2158919680 ODDMI_DataID1 1;
BA_ "SignalType" SG_ 2158919680 ODDMI_DataID1 "UNM";
BA_ "PacketOrder" SG_ 2158919680 ODDMI_DataID1 8;
BA_ "SignalLongName" SG_ 2158919680 ODDMI_DataID1 "Open Display Interface Dynamic Data Multi Request IPC : Data ID One";
BA_ "VNSigAllNodes" SG_ 2158919680 ODDMI_DataID1 1;
BA_ "GenSigSendType" SG_ 2158919680 ODDMI_DataID4Vld 10;
BA_ "VNSigInfotainment" SG_ 2158919680 ODDMI_DataID4Vld 1;
BA_ "SignalType" SG_ 2158919680 ODDMI_DataID4Vld "BLN";
BA_ "PacketOrder" SG_ 2158919680 ODDMI_DataID4Vld 3;
BA_ "SignalLongName" SG_ 2158919680 ODDMI_DataID4Vld "Open Display Interface Dynamic Data Multi Request IPC : Data ID Four Valid";
BA_ "VNSigAllNodes" SG_ 2158919680 ODDMI_DataID4Vld 1;
BA_ "GenSigDeltaValue" SG_ 2158919680 ODDMI_DataID4 1;
BA_ "GenSigSendType" SG_ 2158919680 ODDMI_DataID4 12;
BA_ "VNSigInfotainment" SG_ 2158919680 ODDMI_DataID4 1;
BA_ "SignalType" SG_ 2158919680 ODDMI_DataID4 "UNM";
BA_ "PacketOrder" SG_ 2158919680 ODDMI_DataID4 11;
BA_ "SignalLongName" SG_ 2158919680 ODDMI_DataID4 "Open Display Interface Dynamic Data Multi Request IPC : Data ID Four";
BA_ "VNSigAllNodes" SG_ 2158919680 ODDMI_DataID4 1;
BA_ "GenSigSendType" SG_ 2158919680 ODDMI_DataID5Vld 10;
BA_ "VNSigInfotainment" SG_ 2158919680 ODDMI_DataID5Vld 1;
BA_ "SignalType" SG_ 2158919680 ODDMI_DataID5Vld "BLN";
BA_ "PacketOrder" SG_ 2158919680 ODDMI_DataID5Vld 2;
BA_ "SignalLongName" SG_ 2158919680 ODDMI_DataID5Vld "Open Display Interface Dynamic Data Multi Request IPC : Data ID Five Valid";
BA_ "VNSigAllNodes" SG_ 2158919680 ODDMI_DataID5Vld 1;
BA_ "GenSigDeltaValue" SG_ 2158919680 ODDMI_DataID5 1;
BA_ "GenSigSendType" SG_ 2158919680 ODDMI_DataID5 12;
BA_ "VNSigInfotainment" SG_ 2158919680 ODDMI_DataID5 1;
BA_ "SignalType" SG_ 2158919680 ODDMI_DataID5 "UNM";
BA_ "PacketOrder" SG_ 2158919680 ODDMI_DataID5 12;
BA_ "SignalLongName" SG_ 2158919680 ODDMI_DataID5 "Open Display Interface Dynamic Data Multi Request IPC : Data ID Five";
BA_ "VNSigAllNodes" SG_ 2158919680 ODDMI_DataID5 1;
BA_ "SignalType" SG_ 2150023168 OffBrdVehImmbNot "ENM";
BA_ "SignalLongName" SG_ 2150023168 OffBrdVehImmbNot "Off Board Vehicle Immobilization Notification";
BA_ "VNSigAllNodes" SG_ 2150023168 OffBrdVehImmbNot 1;
BA_ "VNSigInfotainment" SG_ 2150023168 ElecPrplsnMtrTach 1;
BA_ "SignalType" SG_ 2150023168 ElecPrplsnMtrTach "UNM";
BA_ "SignalLongName" SG_ 2150023168 ElecPrplsnMtrTach "Electric Propulsion Motor Tachometer";
BA_ "VNSigAllNodes" SG_ 2150023168 ElecPrplsnMtrTach 1;
BA_ "GenSigSendOnInit" SG_ 2150023168 HVInvRatVltV 1;
BA_ "SignalType" SG_ 2150023168 HVInvRatVltV "ENM";
BA_ "SignalLongName" SG_ 2150023168 HVInvRatVltV "High Voltage Inverter Rationalized Voltage  Validity";
BA_ "VNSigAllNodes" SG_ 2150023168 HVInvRatVltV 1;
BA_ "GenSigSendOnInit" SG_ 2150023168 HVInvRatVlt 1;
BA_ "SignalType" SG_ 2150023168 HVInvRatVlt "UNM";
BA_ "SignalLongName" SG_ 2150023168 HVInvRatVlt "High Voltage Inverter Rationalized Voltage";
BA_ "VNSigAllNodes" SG_ 2150023168 HVInvRatVlt 1;
BA_ "GenSigSendOnInit" SG_ 2150023168 HybChrgMdStat 1;
BA_ "VNSigInfotainment" SG_ 2150023168 HybChrgMdStat 1;
BA_ "SignalType" SG_ 2150023168 HybChrgMdStat "ENM";
BA_ "SignalLongName" SG_ 2150023168 HybChrgMdStat "Hybrid Charge Mode State";
BA_ "VNSigAllNodes" SG_ 2150023168 HybChrgMdStat 1;
BA_ "GenSigSendType" SG_ 2150285312 PsngSysHdingV 10;
BA_ "SignalType" SG_ 2150285312 PsngSysHdingV "ENM";
BA_ "SignalLongName" SG_ 2150285312 PsngSysHdingV "Positioning System Heading Validity";
BA_ "VNSigAllNodes" SG_ 2150285312 PsngSysHdingV 1;
BA_ "GenSigDeltaValue" SG_ 2150285312 PsngSysHding 1;
BA_ "GenSigSendType" SG_ 2150285312 PsngSysHding 12;
BA_ "SignalType" SG_ 2150285312 PsngSysHding "UNM";
BA_ "SignalLongName" SG_ 2150285312 PsngSysHding "Positioning System Heading";
BA_ "VNSigAllNodes" SG_ 2150285312 PsngSysHding 1;
BA_ "GenSigSendType" SG_ 2150285312 PsngSysElvtnV 10;
BA_ "VNSigInfotainment" SG_ 2150285312 PsngSysElvtnV 1;
BA_ "SignalType" SG_ 2150285312 PsngSysElvtnV "ENM";
BA_ "SignalLongName" SG_ 2150285312 PsngSysElvtnV "Positioning System Elevation Validity";
BA_ "VNSigAllNodes" SG_ 2150285312 PsngSysElvtnV 1;
BA_ "GenSigDeltaValue" SG_ 2150285312 PsngSysElvtn 1;
BA_ "GenSigSendType" SG_ 2150285312 PsngSysElvtn 12;
BA_ "VNSigInfotainment" SG_ 2150285312 PsngSysElvtn 1;
BA_ "SignalType" SG_ 2150285312 PsngSysElvtn "UNM";
BA_ "SignalLongName" SG_ 2150285312 PsngSysElvtn "Positioning System Elevation";
BA_ "VNSigAllNodes" SG_ 2150285312 PsngSysElvtn 1;
BA_ "GenSigDeltaValue" SG_ 2150285312 PsngSysDilPrcs 1;
BA_ "GenSigSendType" SG_ 2150285312 PsngSysDilPrcs 12;
BA_ "VNSigInfotainment" SG_ 2150285312 PsngSysDilPrcs 1;
BA_ "SignalType" SG_ 2150285312 PsngSysDilPrcs "UNM";
BA_ "SignalLongName" SG_ 2150285312 PsngSysDilPrcs "Positioning System Dilution of Precision";
BA_ "VNSigAllNodes" SG_ 2150285312 PsngSysDilPrcs 1;
BA_ "GenSigSendType" SG_ 2150285312 PsngSysCalcSpdV 10;
BA_ "VNSigInfotainment" SG_ 2150285312 PsngSysCalcSpdV 1;
BA_ "SignalType" SG_ 2150285312 PsngSysCalcSpdV "ENM";
BA_ "SignalLongName" SG_ 2150285312 PsngSysCalcSpdV "Positioning System Calculated Speed Validity";
BA_ "VNSigAllNodes" SG_ 2150285312 PsngSysCalcSpdV 1;
BA_ "GenSigDeltaValue" SG_ 2150285312 PsngSysCalcSpd 1;
BA_ "GenSigSendType" SG_ 2150285312 PsngSysCalcSpd 12;
BA_ "VNSigInfotainment" SG_ 2150285312 PsngSysCalcSpd 1;
BA_ "SignalType" SG_ 2150285312 PsngSysCalcSpd "UNM";
BA_ "SignalLongName" SG_ 2150285312 PsngSysCalcSpd "Positioning System Calculated Speed";
BA_ "VNSigAllNodes" SG_ 2150285312 PsngSysCalcSpd 1;
BA_ "GenSigSendType" SG_ 2150285312 PsngSysDilPrcsV 10;
BA_ "VNSigInfotainment" SG_ 2150285312 PsngSysDilPrcsV 1;
BA_ "SignalType" SG_ 2150285312 PsngSysDilPrcsV "ENM";
BA_ "SignalLongName" SG_ 2150285312 PsngSysDilPrcsV "Positioning System Dilution of Precision Validity";
BA_ "VNSigAllNodes" SG_ 2150285312 PsngSysDilPrcsV 1;
BA_ "GenSigSendType" SG_ 2150277120 PsngSysLongV 10;
BA_ "VNSigInfotainment" SG_ 2150277120 PsngSysLongV 1;
BA_ "SignalType" SG_ 2150277120 PsngSysLongV "ENM";
BA_ "SignalLongName" SG_ 2150277120 PsngSysLongV "Positioning System Longitude Validity";
BA_ "VNSigAllNodes" SG_ 2150277120 PsngSysLongV 1;
BA_ "GenSigDeltaValue" SG_ 2150277120 PsngSysLong 1;
BA_ "GenSigSendType" SG_ 2150277120 PsngSysLong 12;
BA_ "VNSigInfotainment" SG_ 2150277120 PsngSysLong 1;
BA_ "SignalType" SG_ 2150277120 PsngSysLong "SNM";
BA_ "SignalLongName" SG_ 2150277120 PsngSysLong "Positioning System Longitude";
BA_ "VNSigAllNodes" SG_ 2150277120 PsngSysLong 1;
BA_ "GenSigSendType" SG_ 2150277120 PsngSysLatV 10;
BA_ "VNSigInfotainment" SG_ 2150277120 PsngSysLatV 1;
BA_ "SignalType" SG_ 2150277120 PsngSysLatV "ENM";
BA_ "SignalLongName" SG_ 2150277120 PsngSysLatV "Positioning System Latitude Validity";
BA_ "VNSigAllNodes" SG_ 2150277120 PsngSysLatV 1;
BA_ "GenSigDeltaValue" SG_ 2150277120 PsngSysLat 1;
BA_ "GenSigSendType" SG_ 2150277120 PsngSysLat 12;
BA_ "GenSigSendOnInit" SG_ 2150277120 PsngSysLat 2;
BA_ "VNSigInfotainment" SG_ 2150277120 PsngSysLat 1;
BA_ "SignalType" SG_ 2150277120 PsngSysLat "SNM";
BA_ "SignalLongName" SG_ 2150277120 PsngSysLat "Positioning System Latitude";
BA_ "VNSigAllNodes" SG_ 2150277120 PsngSysLat 1;
BA_ "GenSigSendType" SG_ 2156806144 SecCmpstdValV 10;
BA_ "SignalType" SG_ 2156806144 SecCmpstdValV "ENM";
BA_ "SignalLongName" SG_ 2156806144 SecCmpstdValV "Seconds Compensated Value Validity";
BA_ "VNSigAllNodes" SG_ 2156806144 SecCmpstdValV 1;
BA_ "GenSigDeltaValue" SG_ 2156806144 SecCmpstdVal 1;
BA_ "GenSigSendType" SG_ 2156806144 SecCmpstdVal 12;
BA_ "SignalType" SG_ 2156806144 SecCmpstdVal "UNM";
BA_ "SignalLongName" SG_ 2156806144 SecCmpstdVal "Seconds Compensated Value";
BA_ "VNSigAllNodes" SG_ 2156806144 SecCmpstdVal 1;
BA_ "GenSigSendType" SG_ 2156806144 MinsCmpstdValV 10;
BA_ "SignalType" SG_ 2156806144 MinsCmpstdValV "ENM";
BA_ "SignalLongName" SG_ 2156806144 MinsCmpstdValV "Minutes Compensated Value Validity";
BA_ "VNSigAllNodes" SG_ 2156806144 MinsCmpstdValV 1;
BA_ "GenSigDeltaValue" SG_ 2156806144 MinsCmpstdVal 1;
BA_ "GenSigSendType" SG_ 2156806144 MinsCmpstdVal 12;
BA_ "SignalType" SG_ 2156806144 MinsCmpstdVal "UNM";
BA_ "SignalLongName" SG_ 2156806144 MinsCmpstdVal "Minutes Compensated Value";
BA_ "VNSigAllNodes" SG_ 2156806144 MinsCmpstdVal 1;
BA_ "GenSigSendType" SG_ 2156806144 HrsCmpstdValV 10;
BA_ "SignalType" SG_ 2156806144 HrsCmpstdValV "ENM";
BA_ "SignalLongName" SG_ 2156806144 HrsCmpstdValV "Hours Compensated Value Validity";
BA_ "VNSigAllNodes" SG_ 2156806144 HrsCmpstdValV 1;
BA_ "GenSigDeltaValue" SG_ 2156806144 HrsCmpstdVal 1;
BA_ "GenSigSendType" SG_ 2156806144 HrsCmpstdVal 12;
BA_ "SignalType" SG_ 2156806144 HrsCmpstdVal "UNM";
BA_ "SignalLongName" SG_ 2156806144 HrsCmpstdVal "Hours Compensated Value";
BA_ "VNSigAllNodes" SG_ 2156806144 HrsCmpstdVal 1;
BA_ "GenSigDeltaValue" SG_ 2156806144 CldrYrCmpstdVal 1;
BA_ "GenSigSendType" SG_ 2156806144 CldrYrCmpstdVal 12;
BA_ "SignalType" SG_ 2156806144 CldrYrCmpstdVal "UNM";
BA_ "SignalLongName" SG_ 2156806144 CldrYrCmpstdVal "Calendar Year Compensated Value";
BA_ "VNSigAllNodes" SG_ 2156806144 CldrYrCmpstdVal 1;
BA_ "GenSigSendType" SG_ 2156806144 CldrMthCmpstdVal 10;
BA_ "SignalType" SG_ 2156806144 CldrMthCmpstdVal "ENM";
BA_ "SignalLongName" SG_ 2156806144 CldrMthCmpstdVal "Calendar Month Compensated Value";
BA_ "VNSigAllNodes" SG_ 2156806144 CldrMthCmpstdVal 1;
BA_ "GenSigDeltaValue" SG_ 2156806144 CldrDayCmpstdVal 1;
BA_ "GenSigSendType" SG_ 2156806144 CldrDayCmpstdVal 12;
BA_ "SignalType" SG_ 2156806144 CldrDayCmpstdVal "UNM";
BA_ "SignalLongName" SG_ 2156806144 CldrDayCmpstdVal "Calendar Day Compensated Value";
BA_ "VNSigAllNodes" SG_ 2156806144 CldrDayCmpstdVal 1;
BA_ "GenSigSendType" SG_ 2156806144 CellNtwrkDtTmAvl 10;
BA_ "GenSigSendOnInit" SG_ 2156806144 CellNtwrkDtTmAvl 1;
BA_ "SignalType" SG_ 2156806144 CellNtwrkDtTmAvl "BLN";
BA_ "SignalLongName" SG_ 2156806144 CellNtwrkDtTmAvl "Cellular Network Date and Time Available";
BA_ "VNSigAllNodes" SG_ 2156806144 CellNtwrkDtTmAvl 1;
BA_ "GenSigSendType" SG_ 2151514112 EngOilLfRstRq 10;
BA_ "SignalType" SG_ 2151514112 EngOilLfRstRq "BLN";
BA_ "SignalLongName" SG_ 2151514112 EngOilLfRstRq "Engine Oil Life Reset Request";
BA_ "VNSigAllNodes" SG_ 2151514112 EngOilLfRstRq 1;
BA_ "SignalType" SG_ 2154561536 VehOdoV "ENM";
BA_ "SignalLongName" SG_ 2154561536 VehOdoV "Vehicle Odometer Validity";
BA_ "VNSigAllNodes" SG_ 2154561536 VehOdoV 1;
BA_ "SignalType" SG_ 2154561536 VehOdo "UNM";
BA_ "SignalLongName" SG_ 2154561536 VehOdo "Vehicle Odometer";
BA_ "VNSigAllNodes" SG_ 2154561536 VehOdo 1;
BA_ "SignalType" SG_ 2155872256 DrvStyPerfMdCsCrStVal "ENM";
BA_ "SignalLongName" SG_ 2155872256 DrvStyPerfMdCsCrStVal "Driving Style Performance Mode Customization Current Setting Value";
BA_ "VNSigAllNodes" SG_ 2155872256 DrvStyPerfMdCsCrStVal 1;
BA_ "SignalType" SG_ 2155872256 DrvStyPerfMdCsStAvl "BLN";
BA_ "SignalLongName" SG_ 2155872256 DrvStyPerfMdCsStAvl "Driving Style Performance Mode Customization Setting Available";
BA_ "VNSigAllNodes" SG_ 2155872256 DrvStyPerfMdCsStAvl 1;
BA_ "SignalType" SG_ 2155872256 VehPitchAngleV "ENM";
BA_ "SignalLongName" SG_ 2155872256 VehPitchAngleV "Vehicle Pitch Angle Validity";
BA_ "VNSigAllNodes" SG_ 2155872256 VehPitchAngleV 1;
BA_ "SignalType" SG_ 2155872256 VehPitchAngle "UNM";
BA_ "SignalLongName" SG_ 2155872256 VehPitchAngle "Vehicle Pitch Angle";
BA_ "VNSigAllNodes" SG_ 2155872256 VehPitchAngle 1;
BA_ "SignalType" SG_ 2155872256 RdWhlAngV "ENM";
BA_ "SignalLongName" SG_ 2155872256 RdWhlAngV "Road Wheel Angle Validity";
BA_ "VNSigAllNodes" SG_ 2155872256 RdWhlAngV 1;
BA_ "SignalType" SG_ 2155872256 RdWhlAng "UNM";
BA_ "SignalLongName" SG_ 2155872256 RdWhlAng "Road Wheel Angle";
BA_ "VNSigAllNodes" SG_ 2155872256 RdWhlAng 1;
BA_ "SignalType" SG_ 2155872256 FuelFltChgNwIO "BLN";
BA_ "SignalLongName" SG_ 2155872256 FuelFltChgNwIO "Fuel Filter Change Now Indication On";
BA_ "VNSigAllNodes" SG_ 2155872256 FuelFltChgNwIO 1;
BA_ "GenSigSendOnInit" SG_ 2155872256 FlLvlPctV 1;
BA_ "SignalType" SG_ 2155872256 FlLvlPctV "ENM";
BA_ "SignalLongName" SG_ 2155872256 FlLvlPctV "Fuel Level Percent Validity";
BA_ "VNSigAllNodes" SG_ 2155872256 FlLvlPctV 1;
BA_ "GenSigSendOnInit" SG_ 2155872256 FlLvlPct 1;
BA_ "SignalType" SG_ 2155872256 FlLvlPct "UNM";
BA_ "SignalLongName" SG_ 2155872256 FlLvlPct "Fuel Level Percent";
BA_ "VNSigAllNodes" SG_ 2155872256 FlLvlPct 1;
BA_ "SignalType" SG_ 2155872256 FlInjRlCtRstOcc "BLN";
BA_ "SignalLongName" SG_ 2155872256 FlInjRlCtRstOcc "Fuel Injected Rolling Count Reset Occurred";
BA_ "VNSigAllNodes" SG_ 2155872256 FlInjRlCtRstOcc 1;
BA_ "SignalType" SG_ 2155872256 FlInjRlCt "UNM";
BA_ "SignalLongName" SG_ 2155872256 FlInjRlCt "Fuel Injected Rolling Count";
BA_ "VNSigAllNodes" SG_ 2155872256 FlInjRlCt 1;
BA_ "GenSigSendType" SG_ 2151972864 VehFuelRngCalcV 10;
BA_ "GenSigSendOnInit" SG_ 2151972864 VehFuelRngCalcV 1;
BA_ "SignalType" SG_ 2151972864 VehFuelRngCalcV "ENM";
BA_ "SignalLongName" SG_ 2151972864 VehFuelRngCalcV "Vehicle Fuel Range Calculated Validity";
BA_ "VNSigAllNodes" SG_ 2151972864 VehFuelRngCalcV 1;
BA_ "GenSigDeltaValue" SG_ 2151972864 VehFuelRngCalc 1;
BA_ "GenSigSendType" SG_ 2151972864 VehFuelRngCalc 12;
BA_ "GenSigSendOnInit" SG_ 2151972864 VehFuelRngCalc 1;
BA_ "SignalType" SG_ 2151972864 VehFuelRngCalc "UNM";
BA_ "SignalLongName" SG_ 2151972864 VehFuelRngCalc "Vehicle Fuel Range Calculated";
BA_ "VNSigAllNodes" SG_ 2151972864 VehFuelRngCalc 1;
BA_ "GenSigSendType" SG_ 2151972864 FuelLvlLwIO 10;
BA_ "GenSigSendOnInit" SG_ 2151972864 FuelLvlLwIO 2;
BA_ "SignalType" SG_ 2151972864 FuelLvlLwIO "BLN";
BA_ "SignalLongName" SG_ 2151972864 FuelLvlLwIO "Fuel Level Low Indication On";
BA_ "VNSigAllNodes" SG_ 2151972864 FuelLvlLwIO 1;
BA_ "GenSigSendType" SG_ 2151972864 LnchCtrlWhlSlpReq 10;
BA_ "SignalType" SG_ 2151972864 LnchCtrlWhlSlpReq "ENM";
BA_ "SignalLongName" SG_ 2151972864 LnchCtrlWhlSlpReq "Launch Control Wheel Slip Request";
BA_ "VNSigAllNodes" SG_ 2151972864 LnchCtrlWhlSlpReq 1;
BA_ "GenSigSendType" SG_ 2151972864 LnchCtrlMdReq 10;
BA_ "SignalType" SG_ 2151972864 LnchCtrlMdReq "ENM";
BA_ "SignalLongName" SG_ 2151972864 LnchCtrlMdReq "Launch Control Mode Request";
BA_ "VNSigAllNodes" SG_ 2151972864 LnchCtrlMdReq 1;
BA_ "GenSigSendType" SG_ 2151972864 LnchCtrlEngRPMReq 10;
BA_ "SignalType" SG_ 2151972864 LnchCtrlEngRPMReq "ENM";
BA_ "SignalLongName" SG_ 2151972864 LnchCtrlEngRPMReq "Launch Control Engine RPM Request";
BA_ "VNSigAllNodes" SG_ 2151972864 LnchCtrlEngRPMReq 1;
BA_ "SignalType" SG_ 2152095744 SPMCA_SusPrfMd6Avl "BLN";
BA_ "PacketOrder" SG_ 2152095744 SPMCA_SusPrfMd6Avl 6;
BA_ "SignalLongName" SG_ 2152095744 SPMCA_SusPrfMd6Avl "Suspension Performance Mode Customization Available : Suspension Performance Mode 6 Available";
BA_ "VNSigAllNodes" SG_ 2152095744 SPMCA_SusPrfMd6Avl 1;
BA_ "SignalType" SG_ 2152095744 SPMCA_SusPrfMd5Avl "BLN";
BA_ "PacketOrder" SG_ 2152095744 SPMCA_SusPrfMd5Avl 5;
BA_ "SignalLongName" SG_ 2152095744 SPMCA_SusPrfMd5Avl "Suspension Performance Mode Customization Available : Suspension Performance Mode 5 Available";
BA_ "VNSigAllNodes" SG_ 2152095744 SPMCA_SusPrfMd5Avl 1;
BA_ "SignalType" SG_ 2152095744 SPMCA_SusPrfMd4Avl "BLN";
BA_ "PacketOrder" SG_ 2152095744 SPMCA_SusPrfMd4Avl 4;
BA_ "SignalLongName" SG_ 2152095744 SPMCA_SusPrfMd4Avl "Suspension Performance Mode Customization Available : Suspension Performance Mode 4 Available";
BA_ "VNSigAllNodes" SG_ 2152095744 SPMCA_SusPrfMd4Avl 1;
BA_ "SignalType" SG_ 2152095744 SPMCA_SusPrfMd3Avl "BLN";
BA_ "PacketOrder" SG_ 2152095744 SPMCA_SusPrfMd3Avl 3;
BA_ "SignalLongName" SG_ 2152095744 SPMCA_SusPrfMd3Avl "Suspension Performance Mode Customization Available : Suspension Performance Mode 3 Available";
BA_ "VNSigAllNodes" SG_ 2152095744 SPMCA_SusPrfMd3Avl 1;
BA_ "SignalType" SG_ 2152095744 SPMCA_SusPrfMd2Avl "BLN";
BA_ "PacketOrder" SG_ 2152095744 SPMCA_SusPrfMd2Avl 2;
BA_ "SignalLongName" SG_ 2152095744 SPMCA_SusPrfMd2Avl "Suspension Performance Mode Customization Available : Suspension Performance Mode 2 Available";
BA_ "VNSigAllNodes" SG_ 2152095744 SPMCA_SusPrfMd2Avl 1;
BA_ "SignalType" SG_ 2152095744 SPMCA_SusPrfMd1Avl "BLN";
BA_ "PacketOrder" SG_ 2152095744 SPMCA_SusPrfMd1Avl 1;
BA_ "SignalLongName" SG_ 2152095744 SPMCA_SusPrfMd1Avl "Suspension Performance Mode Customization Available : Suspension Performance Mode 1 Available";
BA_ "VNSigAllNodes" SG_ 2152095744 SPMCA_SusPrfMd1Avl 1;
BA_ "SignalType" SG_ 2152095744 SPMCA_StrPrfMd6Avl "BLN";
BA_ "PacketOrder" SG_ 2152095744 SPMCA_StrPrfMd6Avl 6;
BA_ "SignalLongName" SG_ 2152095744 SPMCA_StrPrfMd6Avl "Steering Performance Mode Customization Available : Steering Performance Mode 6 Available";
BA_ "VNSigAllNodes" SG_ 2152095744 SPMCA_StrPrfMd6Avl 1;
BA_ "SignalType" SG_ 2152095744 SPMCA_StrPrfMd5Avl "BLN";
BA_ "PacketOrder" SG_ 2152095744 SPMCA_StrPrfMd5Avl 5;
BA_ "SignalLongName" SG_ 2152095744 SPMCA_StrPrfMd5Avl "Steering Performance Mode Customization Available : Steering Performance Mode 5 Available";
BA_ "VNSigAllNodes" SG_ 2152095744 SPMCA_StrPrfMd5Avl 1;
BA_ "SignalType" SG_ 2152095744 SPMCA_StrPrfMd4Avl "BLN";
BA_ "PacketOrder" SG_ 2152095744 SPMCA_StrPrfMd4Avl 4;
BA_ "SignalLongName" SG_ 2152095744 SPMCA_StrPrfMd4Avl "Steering Performance Mode Customization Available : Steering Performance Mode 4 Available";
BA_ "VNSigAllNodes" SG_ 2152095744 SPMCA_StrPrfMd4Avl 1;
BA_ "SignalType" SG_ 2152095744 SPMCA_StrPrfMd3Avl "BLN";
BA_ "PacketOrder" SG_ 2152095744 SPMCA_StrPrfMd3Avl 3;
BA_ "SignalLongName" SG_ 2152095744 SPMCA_StrPrfMd3Avl "Steering Performance Mode Customization Available : Steering Performance Mode 3 Available";
BA_ "VNSigAllNodes" SG_ 2152095744 SPMCA_StrPrfMd3Avl 1;
BA_ "SignalType" SG_ 2152095744 SPMCA_StrPrfMd2Avl "BLN";
BA_ "PacketOrder" SG_ 2152095744 SPMCA_StrPrfMd2Avl 2;
BA_ "SignalLongName" SG_ 2152095744 SPMCA_StrPrfMd2Avl "Steering Performance Mode Customization Available : Steering Performance Mode 2 Available";
BA_ "VNSigAllNodes" SG_ 2152095744 SPMCA_StrPrfMd2Avl 1;
BA_ "SignalType" SG_ 2152095744 SPMCA_StrPrfMd1Avl "BLN";
BA_ "PacketOrder" SG_ 2152095744 SPMCA_StrPrfMd1Avl 1;
BA_ "SignalLongName" SG_ 2152095744 SPMCA_StrPrfMd1Avl "Steering Performance Mode Customization Available : Steering Performance Mode 1 Available";
BA_ "VNSigAllNodes" SG_ 2152095744 SPMCA_StrPrfMd1Avl 1;
BA_ "SignalType" SG_ 2152095744 SPMCA_SndPrfMd6Avl "BLN";
BA_ "PacketOrder" SG_ 2152095744 SPMCA_SndPrfMd6Avl 6;
BA_ "SignalLongName" SG_ 2152095744 SPMCA_SndPrfMd6Avl "Sound Performance Mode Customization Available : Sound Performance Mode 6 Available";
BA_ "VNSigAllNodes" SG_ 2152095744 SPMCA_SndPrfMd6Avl 1;
BA_ "SignalType" SG_ 2152095744 SPMCA_SndPrfMd5Avl "BLN";
BA_ "PacketOrder" SG_ 2152095744 SPMCA_SndPrfMd5Avl 5;
BA_ "SignalLongName" SG_ 2152095744 SPMCA_SndPrfMd5Avl "Sound Performance Mode Customization Available : Sound Performance Mode 5 Available";
BA_ "VNSigAllNodes" SG_ 2152095744 SPMCA_SndPrfMd5Avl 1;
BA_ "SignalType" SG_ 2152095744 SPMCA_SndPrfMd4Avl "BLN";
BA_ "PacketOrder" SG_ 2152095744 SPMCA_SndPrfMd4Avl 4;
BA_ "SignalLongName" SG_ 2152095744 SPMCA_SndPrfMd4Avl "Sound Performance Mode Customization Available : Sound Performance Mode 4 Available";
BA_ "VNSigAllNodes" SG_ 2152095744 SPMCA_SndPrfMd4Avl 1;
BA_ "SignalType" SG_ 2152095744 SPMCA_SndPrfMd3Avl "BLN";
BA_ "PacketOrder" SG_ 2152095744 SPMCA_SndPrfMd3Avl 3;
BA_ "SignalLongName" SG_ 2152095744 SPMCA_SndPrfMd3Avl "Sound Performance Mode Customization Available : Sound Performance Mode 3 Available";
BA_ "VNSigAllNodes" SG_ 2152095744 SPMCA_SndPrfMd3Avl 1;
BA_ "SignalType" SG_ 2152095744 SPMCA_SndPrfMd2Avl "BLN";
BA_ "PacketOrder" SG_ 2152095744 SPMCA_SndPrfMd2Avl 2;
BA_ "SignalLongName" SG_ 2152095744 SPMCA_SndPrfMd2Avl "Sound Performance Mode Customization Available : Sound Performance Mode 2 Available";
BA_ "VNSigAllNodes" SG_ 2152095744 SPMCA_SndPrfMd2Avl 1;
BA_ "SignalType" SG_ 2152095744 SPMCA_SndPrfMd1Avl "BLN";
BA_ "PacketOrder" SG_ 2152095744 SPMCA_SndPrfMd1Avl 1;
BA_ "SignalLongName" SG_ 2152095744 SPMCA_SndPrfMd1Avl "Sound Performance Mode Customization Available : Sound Performance Mode 1 Available";
BA_ "VNSigAllNodes" SG_ 2152095744 SPMCA_SndPrfMd1Avl 1;
BA_ "SignalType" SG_ 2152095744 DPMCA_DispPrfMd6Avl "BLN";
BA_ "PacketOrder" SG_ 2152095744 DPMCA_DispPrfMd6Avl 6;
BA_ "SignalLongName" SG_ 2152095744 DPMCA_DispPrfMd6Avl "Display Performance Mode Customization Available : Display Performance Mode 6 Available";
BA_ "VNSigAllNodes" SG_ 2152095744 DPMCA_DispPrfMd6Avl 1;
BA_ "SignalType" SG_ 2152095744 DPMCA_DispPrfMd5Avl "BLN";
BA_ "PacketOrder" SG_ 2152095744 DPMCA_DispPrfMd5Avl 5;
BA_ "SignalLongName" SG_ 2152095744 DPMCA_DispPrfMd5Avl "Display Performance Mode Customization Available : Display Performance Mode 5 Available";
BA_ "VNSigAllNodes" SG_ 2152095744 DPMCA_DispPrfMd5Avl 1;
BA_ "SignalType" SG_ 2152095744 DPMCA_DispPrfMd4Avl "BLN";
BA_ "PacketOrder" SG_ 2152095744 DPMCA_DispPrfMd4Avl 4;
BA_ "SignalLongName" SG_ 2152095744 DPMCA_DispPrfMd4Avl "Display Performance Mode Customization Available : Display Performance Mode 4 Available";
BA_ "VNSigAllNodes" SG_ 2152095744 DPMCA_DispPrfMd4Avl 1;
BA_ "SignalType" SG_ 2152095744 DPMCA_DispPrfMd3Avl "BLN";
BA_ "PacketOrder" SG_ 2152095744 DPMCA_DispPrfMd3Avl 3;
BA_ "SignalLongName" SG_ 2152095744 DPMCA_DispPrfMd3Avl "Display Performance Mode Customization Available : Display Performance Mode 3 Available";
BA_ "VNSigAllNodes" SG_ 2152095744 DPMCA_DispPrfMd3Avl 1;
BA_ "SignalType" SG_ 2152095744 DPMCA_DispPrfMd2Avl "BLN";
BA_ "PacketOrder" SG_ 2152095744 DPMCA_DispPrfMd2Avl 2;
BA_ "SignalLongName" SG_ 2152095744 DPMCA_DispPrfMd2Avl "Display Performance Mode Customization Available : Display Performance Mode 2 Available";
BA_ "VNSigAllNodes" SG_ 2152095744 DPMCA_DispPrfMd2Avl 1;
BA_ "SignalType" SG_ 2152095744 DPMCA_DispPrfMd1Avl "BLN";
BA_ "PacketOrder" SG_ 2152095744 DPMCA_DispPrfMd1Avl 1;
BA_ "SignalLongName" SG_ 2152095744 DPMCA_DispPrfMd1Avl "Display Performance Mode Customization Available : Display Performance Mode 1 Available";
BA_ "VNSigAllNodes" SG_ 2152095744 DPMCA_DispPrfMd1Avl 1;
BA_ "SignalType" SG_ 2152095744 DPMCA_DrvlPrfMd6Avl "BLN";
BA_ "PacketOrder" SG_ 2152095744 DPMCA_DrvlPrfMd6Avl 6;
BA_ "SignalLongName" SG_ 2152095744 DPMCA_DrvlPrfMd6Avl "Driveline Performance Mode Customization Available : Driveline Performance Mode 6 Available";
BA_ "VNSigAllNodes" SG_ 2152095744 DPMCA_DrvlPrfMd6Avl 1;
BA_ "SignalType" SG_ 2152095744 DPMCA_DrvlPrfMd5Avl "BLN";
BA_ "PacketOrder" SG_ 2152095744 DPMCA_DrvlPrfMd5Avl 5;
BA_ "SignalLongName" SG_ 2152095744 DPMCA_DrvlPrfMd5Avl "Driveline Performance Mode Customization Available : Driveline Performance Mode 5 Available";
BA_ "VNSigAllNodes" SG_ 2152095744 DPMCA_DrvlPrfMd5Avl 1;
BA_ "SignalType" SG_ 2152095744 DPMCA_DrvlPrfMd4Avl "BLN";
BA_ "PacketOrder" SG_ 2152095744 DPMCA_DrvlPrfMd4Avl 4;
BA_ "SignalLongName" SG_ 2152095744 DPMCA_DrvlPrfMd4Avl "Driveline Performance Mode Customization Available : Driveline Performance Mode 4 Available";
BA_ "VNSigAllNodes" SG_ 2152095744 DPMCA_DrvlPrfMd4Avl 1;
BA_ "SignalType" SG_ 2152095744 DPMCA_DrvlPrfMd3Avl "BLN";
BA_ "PacketOrder" SG_ 2152095744 DPMCA_DrvlPrfMd3Avl 3;
BA_ "SignalLongName" SG_ 2152095744 DPMCA_DrvlPrfMd3Avl "Driveline Performance Mode Customization Available : Driveline Performance Mode 3 Available";
BA_ "VNSigAllNodes" SG_ 2152095744 DPMCA_DrvlPrfMd3Avl 1;
BA_ "SignalType" SG_ 2152095744 DPMCA_DrvlPrfMd2Avl "BLN";
BA_ "PacketOrder" SG_ 2152095744 DPMCA_DrvlPrfMd2Avl 2;
BA_ "SignalLongName" SG_ 2152095744 DPMCA_DrvlPrfMd2Avl "Driveline Performance Mode Customization Available : Driveline Performance Mode 2 Available";
BA_ "VNSigAllNodes" SG_ 2152095744 DPMCA_DrvlPrfMd2Avl 1;
BA_ "SignalType" SG_ 2152095744 DPMCA_DrvlPrfMd1Avl "BLN";
BA_ "PacketOrder" SG_ 2152095744 DPMCA_DrvlPrfMd1Avl 1;
BA_ "SignalLongName" SG_ 2152095744 DPMCA_DrvlPrfMd1Avl "Driveline Performance Mode Customization Available : Driveline Performance Mode 1 Available";
BA_ "VNSigAllNodes" SG_ 2152095744 DPMCA_DrvlPrfMd1Avl 1;
BA_ "GenSigSendType" SG_ 2155479040 EleRngEstAdjCstStReq 10;
BA_ "VNSigInfotainment" SG_ 2155479040 EleRngEstAdjCstStReq 1;
BA_ "SignalType" SG_ 2155479040 EleRngEstAdjCstStReq "ENM";
BA_ "SignalLongName" SG_ 2155479040 EleRngEstAdjCstStReq "Electric Range Estimation Adjustment Customization Setting Request";
BA_ "VNSigAllNodes" SG_ 2155479040 EleRngEstAdjCstStReq 1;
BA_ "GenSigSendType" SG_ 2155479040 WPRSCstStReq 10;
BA_ "VNSigInfotainment" SG_ 2155479040 WPRSCstStReq 1;
BA_ "SignalType" SG_ 2155479040 WPRSCstStReq "ENM";
BA_ "SignalLongName" SG_ 2155479040 WPRSCstStReq "Wall Powered Remote Start Customization Setting Request";
BA_ "VNSigAllNodes" SG_ 2155479040 WPRSCstStReq 1;
BA_ "GenSigSendType" SG_ 2155479040 DrvStyPerfMdCsStReq 10;
BA_ "SignalType" SG_ 2155479040 DrvStyPerfMdCsStReq "ENM";
BA_ "SignalLongName" SG_ 2155479040 DrvStyPerfMdCsStReq "Driving Style Performance Mode Customization Setting Request";
BA_ "VNSigAllNodes" SG_ 2155479040 DrvStyPerfMdCsStReq 1;
BA_ "GenSigSendType" SG_ 2155479040 PsngStPerfMdCsStReq 10;
BA_ "SignalType" SG_ 2155479040 PsngStPerfMdCsStReq "ENM";
BA_ "SignalLongName" SG_ 2155479040 PsngStPerfMdCsStReq "Passenger Seat Performance Mode Customization Setting Request";
BA_ "VNSigAllNodes" SG_ 2155479040 PsngStPerfMdCsStReq 1;
BA_ "GenSigSendType" SG_ 2155479040 DrvrStPerfMdCsStReq 10;
BA_ "SignalType" SG_ 2155479040 DrvrStPerfMdCsStReq "ENM";
BA_ "SignalLongName" SG_ 2155479040 DrvrStPerfMdCsStReq "Driver Seat Performance Mode Customization Setting Request";
BA_ "VNSigAllNodes" SG_ 2155479040 DrvrStPerfMdCsStReq 1;
BA_ "GenSigSendType" SG_ 2155479040 ACCPerfMdCsStReq 10;
BA_ "SignalType" SG_ 2155479040 ACCPerfMdCsStReq "ENM";
BA_ "SignalLongName" SG_ 2155479040 ACCPerfMdCsStReq "Adaptive Cruise Control Performance Mode Customization Setting Request";
BA_ "VNSigAllNodes" SG_ 2155479040 ACCPerfMdCsStReq 1;
BA_ "GenSigSendType" SG_ 2155479040 ElvtdIdlCstStReq 10;
BA_ "SignalType" SG_ 2155479040 ElvtdIdlCstStReq "ENM";
BA_ "SignalLongName" SG_ 2155479040 ElvtdIdlCstStReq "Elevated Idle Customization Setting Request";
BA_ "VNSigAllNodes" SG_ 2155479040 ElvtdIdlCstStReq 1;
BA_ "GenSigSendType" SG_ 2155479040 PedFrndlyAlrtCsStReq 10;
BA_ "SignalType" SG_ 2155479040 PedFrndlyAlrtCsStReq "ENM";
BA_ "SignalLongName" SG_ 2155479040 PedFrndlyAlrtCsStReq "Pedestrian Friendly Alert Customization Setting Request";
BA_ "VNSigAllNodes" SG_ 2155479040 PedFrndlyAlrtCsStReq 1;
BA_ "GenSigSendType" SG_ 2155479040 SndPerfMdCsStRq 10;
BA_ "SignalType" SG_ 2155479040 SndPerfMdCsStRq "ENM";
BA_ "SignalLongName" SG_ 2155479040 SndPerfMdCsStRq "Sound Performance Mode Customization Setting Request";
BA_ "VNSigAllNodes" SG_ 2155479040 SndPerfMdCsStRq 1;
BA_ "GenSigSendType" SG_ 2155479040 DispPerfMdCsStRq 10;
BA_ "SignalType" SG_ 2155479040 DispPerfMdCsStRq "ENM";
BA_ "SignalLongName" SG_ 2155479040 DispPerfMdCsStRq "Display Performance Mode Customization Setting Request";
BA_ "VNSigAllNodes" SG_ 2155479040 DispPerfMdCsStRq 1;
BA_ "GenSigSendType" SG_ 2155479040 SusCustStngReq 10;
BA_ "GenSigSendOnInit" SG_ 2155479040 SusCustStngReq 1;
BA_ "SignalType" SG_ 2155479040 SusCustStngReq "ENM";
BA_ "SignalLongName" SG_ 2155479040 SusCustStngReq "Suspension Customization Setting Request";
BA_ "VNSigAllNodes" SG_ 2155479040 SusCustStngReq 1;
BA_ "GenSigSendType" SG_ 2155479040 StrCustStngReq 10;
BA_ "GenSigSendOnInit" SG_ 2155479040 StrCustStngReq 1;
BA_ "SignalType" SG_ 2155479040 StrCustStngReq "ENM";
BA_ "SignalLongName" SG_ 2155479040 StrCustStngReq "Steering Customization Setting Request";
BA_ "VNSigAllNodes" SG_ 2155479040 StrCustStngReq 1;
BA_ "GenSigSendType" SG_ 2155479040 RstrCustFctrDef 10;
BA_ "GenSigSendOnInit" SG_ 2155479040 RstrCustFctrDef 1;
BA_ "VNSigInfotainment" SG_ 2155479040 RstrCustFctrDef 1;
BA_ "SignalType" SG_ 2155479040 RstrCustFctrDef "ENM";
BA_ "SignalLongName" SG_ 2155479040 RstrCustFctrDef "Restore Customization Factory Defaults";
BA_ "VNSigAllNodes" SG_ 2155479040 RstrCustFctrDef 1;
BA_ "GenSigSendType" SG_ 2155479040 DrvlnCustStngReq 10;
BA_ "GenSigSendOnInit" SG_ 2155479040 DrvlnCustStngReq 1;
BA_ "SignalType" SG_ 2155479040 DrvlnCustStngReq "ENM";
BA_ "SignalLongName" SG_ 2155479040 DrvlnCustStngReq "Driveline Customization Setting Request";
BA_ "VNSigAllNodes" SG_ 2155479040 DrvlnCustStngReq 1;
BA_ "GenSigDeltaValue" SG_ 2151981056 DrvCyclBatPropRat 1;
BA_ "GenSigSendType" SG_ 2151981056 DrvCyclBatPropRat 12;
BA_ "GenSigSendOnInit" SG_ 2151981056 DrvCyclBatPropRat 1;
BA_ "VNSigInfotainment" SG_ 2151981056 DrvCyclBatPropRat 1;
BA_ "SignalType" SG_ 2151981056 DrvCyclBatPropRat "UNM";
BA_ "SignalLongName" SG_ 2151981056 DrvCyclBatPropRat "Drive Cycle Battery Propulsion Ratio";
BA_ "VNSigAllNodes" SG_ 2151981056 DrvCyclBatPropRat 1;
BA_ "GenSigDeltaValue" SG_ 2151981056 DTD_FuelPrpDstTrvld 1;
BA_ "GenSigSendType" SG_ 2151981056 DTD_FuelPrpDstTrvld 12;
BA_ "GenSigSendOnInit" SG_ 2151981056 DTD_FuelPrpDstTrvld 1;
BA_ "VNSigInfotainment" SG_ 2151981056 DTD_FuelPrpDstTrvld 1;
BA_ "SignalType" SG_ 2151981056 DTD_FuelPrpDstTrvld "UNM";
BA_ "PacketOrder" SG_ 2151981056 DTD_FuelPrpDstTrvld 2;
BA_ "SignalLongName" SG_ 2151981056 DTD_FuelPrpDstTrvld "Distance Traveled Data : Fuel Propulsion Distance Traveled";
BA_ "VNSigAllNodes" SG_ 2151981056 DTD_FuelPrpDstTrvld 1;
BA_ "GenSigDeltaValue" SG_ 2151981056 DTD_DrvCyclDstTrvld 1;
BA_ "GenSigSendType" SG_ 2151981056 DTD_DrvCyclDstTrvld 12;
BA_ "GenSigSendOnInit" SG_ 2151981056 DTD_DrvCyclDstTrvld 1;
BA_ "VNSigInfotainment" SG_ 2151981056 DTD_DrvCyclDstTrvld 1;
BA_ "SignalType" SG_ 2151981056 DTD_DrvCyclDstTrvld "UNM";
BA_ "PacketOrder" SG_ 2151981056 DTD_DrvCyclDstTrvld 3;
BA_ "SignalLongName" SG_ 2151981056 DTD_DrvCyclDstTrvld "Distance Traveled Data : Drive Cycle Distance Traveled";
BA_ "VNSigAllNodes" SG_ 2151981056 DTD_DrvCyclDstTrvld 1;
BA_ "GenSigDeltaValue" SG_ 2151981056 DTD_BattPrpDstTrvld 1;
BA_ "GenSigSendType" SG_ 2151981056 DTD_BattPrpDstTrvld 12;
BA_ "GenSigSendOnInit" SG_ 2151981056 DTD_BattPrpDstTrvld 1;
BA_ "VNSigInfotainment" SG_ 2151981056 DTD_BattPrpDstTrvld 1;
BA_ "SignalType" SG_ 2151981056 DTD_BattPrpDstTrvld "UNM";
BA_ "PacketOrder" SG_ 2151981056 DTD_BattPrpDstTrvld 1;
BA_ "SignalLongName" SG_ 2151981056 DTD_BattPrpDstTrvld "Distance Traveled Data : Battery Propulsion Distance Traveled";
BA_ "VNSigAllNodes" SG_ 2151981056 DTD_BattPrpDstTrvld 1;
BA_ "GenSigDeltaValue" SG_ 2151964672 DrvCyclTtlEnrgEfncy 1;
BA_ "GenSigSendType" SG_ 2151964672 DrvCyclTtlEnrgEfncy 12;
BA_ "GenSigSendOnInit" SG_ 2151964672 DrvCyclTtlEnrgEfncy 1;
BA_ "VNSigInfotainment" SG_ 2151964672 DrvCyclTtlEnrgEfncy 1;
BA_ "SignalType" SG_ 2151964672 DrvCyclTtlEnrgEfncy "UNM";
BA_ "SignalLongName" SG_ 2151964672 DrvCyclTtlEnrgEfncy "Drive Cycle Total Energy Efficiency";
BA_ "VNSigAllNodes" SG_ 2151964672 DrvCyclTtlEnrgEfncy 1;
BA_ "GenSigDeltaValue" SG_ 2151964672 DrvCyclFuelUsd 1;
BA_ "GenSigSendType" SG_ 2151964672 DrvCyclFuelUsd 12;
BA_ "GenSigSendOnInit" SG_ 2151964672 DrvCyclFuelUsd 1;
BA_ "VNSigInfotainment" SG_ 2151964672 DrvCyclFuelUsd 1;
BA_ "SignalType" SG_ 2151964672 DrvCyclFuelUsd "UNM";
BA_ "SignalLongName" SG_ 2151964672 DrvCyclFuelUsd "Drive Cycle Fuel Used";
BA_ "VNSigAllNodes" SG_ 2151964672 DrvCyclFuelUsd 1;
BA_ "GenSigDeltaValue" SG_ 2151964672 DrvCyclFuelEnmy 1;
BA_ "GenSigSendType" SG_ 2151964672 DrvCyclFuelEnmy 12;
BA_ "GenSigSendOnInit" SG_ 2151964672 DrvCyclFuelEnmy 1;
BA_ "VNSigInfotainment" SG_ 2151964672 DrvCyclFuelEnmy 1;
BA_ "SignalType" SG_ 2151964672 DrvCyclFuelEnmy "UNM";
BA_ "SignalLongName" SG_ 2151964672 DrvCyclFuelEnmy "Drive Cycle Fuel Economy";
BA_ "VNSigAllNodes" SG_ 2151964672 DrvCyclFuelEnmy 1;
BA_ "GenSigDeltaValue" SG_ 2151964672 DrvCyclDrvStEnrgEfncy 1;
BA_ "GenSigSendType" SG_ 2151964672 DrvCyclDrvStEnrgEfncy 12;
BA_ "GenSigSendOnInit" SG_ 2151964672 DrvCyclDrvStEnrgEfncy 1;
BA_ "VNSigInfotainment" SG_ 2151964672 DrvCyclDrvStEnrgEfncy 1;
BA_ "SignalType" SG_ 2151964672 DrvCyclDrvStEnrgEfncy "UNM";
BA_ "SignalLongName" SG_ 2151964672 DrvCyclDrvStEnrgEfncy "Drive Cycle Driving Style Energy Efficiency";
BA_ "VNSigAllNodes" SG_ 2151964672 DrvCyclDrvStEnrgEfncy 1;
BA_ "GenSigDeltaValue" SG_ 2151964672 DrvCyclCbnCondEnrgEfncy 1;
BA_ "GenSigSendType" SG_ 2151964672 DrvCyclCbnCondEnrgEfncy 12;
BA_ "GenSigSendOnInit" SG_ 2151964672 DrvCyclCbnCondEnrgEfncy 1;
BA_ "VNSigInfotainment" SG_ 2151964672 DrvCyclCbnCondEnrgEfncy 1;
BA_ "SignalType" SG_ 2151964672 DrvCyclCbnCondEnrgEfncy "UNM";
BA_ "SignalLongName" SG_ 2151964672 DrvCyclCbnCondEnrgEfncy "Drive Cycle Cabin Conditioning Energy Efficiency";
BA_ "VNSigAllNodes" SG_ 2151964672 DrvCyclCbnCondEnrgEfncy 1;
BA_ "GenSigDeltaValue" SG_ 2151964672 DrvCyclBatCondEnrgEfncy 1;
BA_ "GenSigSendType" SG_ 2151964672 DrvCyclBatCondEnrgEfncy 12;
BA_ "GenSigSendOnInit" SG_ 2151964672 DrvCyclBatCondEnrgEfncy 1;
BA_ "VNSigInfotainment" SG_ 2151964672 DrvCyclBatCondEnrgEfncy 1;
BA_ "SignalType" SG_ 2151964672 DrvCyclBatCondEnrgEfncy "UNM";
BA_ "SignalLongName" SG_ 2151964672 DrvCyclBatCondEnrgEfncy "Drive Cycle Battery Conditioning Energy Efficiency";
BA_ "VNSigAllNodes" SG_ 2151964672 DrvCyclBatCondEnrgEfncy 1;
BA_ "GenSigSendType" SG_ 2155233280 InstnsFlEcnHybOvrdReq 10;
BA_ "SignalType" SG_ 2155233280 InstnsFlEcnHybOvrdReq "ENM";
BA_ "SignalLongName" SG_ 2155233280 InstnsFlEcnHybOvrdReq "Instantaneous Fuel Economy Hybrid Override Request";
BA_ "VNSigAllNodes" SG_ 2155233280 InstnsFlEcnHybOvrdReq 1;
BA_ "GenSigSendType" SG_ 2155233280 NtrlGrWrngIO 10;
BA_ "SignalType" SG_ 2155233280 NtrlGrWrngIO "BLN";
BA_ "SignalLongName" SG_ 2155233280 NtrlGrWrngIO "Neutral Gear Warning Indication On";
BA_ "VNSigAllNodes" SG_ 2155233280 NtrlGrWrngIO 1;
BA_ "GenSigSendType" SG_ 2155233280 RtBsChrgCmplnTmPrfRsp 10;
BA_ "GenSigSendOnInit" SG_ 2155233280 RtBsChrgCmplnTmPrfRsp 1;
BA_ "VNSigInfotainment" SG_ 2155233280 RtBsChrgCmplnTmPrfRsp 1;
BA_ "SignalType" SG_ 2155233280 RtBsChrgCmplnTmPrfRsp "ENM";
BA_ "SignalLongName" SG_ 2155233280 RtBsChrgCmplnTmPrfRsp "Rate Based Charge Completion Time Preference Response";
BA_ "VNSigAllNodes" SG_ 2155233280 RtBsChrgCmplnTmPrfRsp 1;
BA_ "GenSigSendType" SG_ 2155233280 EngRnngDutoVehSpdIO 10;
BA_ "SignalType" SG_ 2155233280 EngRnngDutoVehSpdIO "BLN";
BA_ "SignalLongName" SG_ 2155233280 EngRnngDutoVehSpdIO "Engine Running Due to Vehicle Speed Indication On";
BA_ "VNSigAllNodes" SG_ 2155233280 EngRnngDutoVehSpdIO 1;
BA_ "GenSigDeltaValue" SG_ 2155233280 ChrgCyclFuelEcn 1;
BA_ "GenSigSendType" SG_ 2155233280 ChrgCyclFuelEcn 12;
BA_ "GenSigSendOnInit" SG_ 2155233280 ChrgCyclFuelEcn 1;
BA_ "VNSigInfotainment" SG_ 2155233280 ChrgCyclFuelEcn 1;
BA_ "SignalType" SG_ 2155233280 ChrgCyclFuelEcn "UNM";
BA_ "SignalLongName" SG_ 2155233280 ChrgCyclFuelEcn "Charge Cycle Fuel Economy";
BA_ "VNSigAllNodes" SG_ 2155233280 ChrgCyclFuelEcn 1;
BA_ "GenSigDeltaValue" SG_ 2155233280 LiftimeFuelEcnEquiv 1;
BA_ "GenSigSendType" SG_ 2155233280 LiftimeFuelEcnEquiv 12;
BA_ "GenSigSendOnInit" SG_ 2155233280 LiftimeFuelEcnEquiv 1;
BA_ "VNSigInfotainment" SG_ 2155233280 LiftimeFuelEcnEquiv 1;
BA_ "SignalType" SG_ 2155233280 LiftimeFuelEcnEquiv "UNM";
BA_ "SignalLongName" SG_ 2155233280 LiftimeFuelEcnEquiv "Lifetime Fuel Economy Equivalent";
BA_ "VNSigAllNodes" SG_ 2155233280 LiftimeFuelEcnEquiv 1;
BA_ "GenSigSendType" SG_ 2155233280 ShftPrkIO_3B2 10;
BA_ "SignalType" SG_ 2155233280 ShftPrkIO_3B2 "BLN";
BA_ "SignalLongName" SG_ 2155233280 ShftPrkIO_3B2 "Shift to Park Indication On";
BA_ "VNSigAllNodes" SG_ 2155233280 ShftPrkIO_3B2 1;
BA_ "GenSigDeltaValue" SG_ 2155233280 LftmFuelEcon 1;
BA_ "GenSigSendType" SG_ 2155233280 LftmFuelEcon 12;
BA_ "GenSigSendOnInit" SG_ 2155233280 LftmFuelEcon 1;
BA_ "VNSigInfotainment" SG_ 2155233280 LftmFuelEcon 1;
BA_ "SignalType" SG_ 2155233280 LftmFuelEcon "UNM";
BA_ "SignalLongName" SG_ 2155233280 LftmFuelEcon "Lifetime Fuel Economy";
BA_ "VNSigAllNodes" SG_ 2155233280 LftmFuelEcon 1;
BA_ "GenSigSendType" SG_ 2155233280 FlDrOpenIndOn 10;
BA_ "VNSigInfotainment" SG_ 2155233280 FlDrOpenIndOn 1;
BA_ "SignalType" SG_ 2155233280 FlDrOpenIndOn "BLN";
BA_ "SignalLongName" SG_ 2155233280 FlDrOpenIndOn "Fuel Door Open Indication On";
BA_ "VNSigAllNodes" SG_ 2155233280 FlDrOpenIndOn 1;
BA_ "GenSigSendType" SG_ 2155233280 VehRefuelSt 10;
BA_ "VNSigInfotainment" SG_ 2155233280 VehRefuelSt 1;
BA_ "SignalType" SG_ 2155233280 VehRefuelSt "ENM";
BA_ "SignalLongName" SG_ 2155233280 VehRefuelSt "Vehicle Refueling State";
BA_ "VNSigAllNodes" SG_ 2155233280 VehRefuelSt 1;
BA_ "GenSigSendType" SG_ 2155233280 NtrlCstdwnCrtMdActvIO 10;
BA_ "SignalType" SG_ 2155233280 NtrlCstdwnCrtMdActvIO "BLN";
BA_ "SignalLongName" SG_ 2155233280 NtrlCstdwnCrtMdActvIO "Neutral Coastdown Certification Mode Active Indication On";
BA_ "VNSigAllNodes" SG_ 2155233280 NtrlCstdwnCrtMdActvIO 1;
BA_ "GenSigSendType" SG_ 2155233280 UtlChrgPopUpAct 10;
BA_ "GenSigSendOnInit" SG_ 2155233280 UtlChrgPopUpAct 1;
BA_ "VNSigInfotainment" SG_ 2155233280 UtlChrgPopUpAct 1;
BA_ "SignalType" SG_ 2155233280 UtlChrgPopUpAct "BLN";
BA_ "SignalLongName" SG_ 2155233280 UtlChrgPopUpAct "Utility Charging Interference Pop Up Active";
BA_ "VNSigAllNodes" SG_ 2155233280 UtlChrgPopUpAct 1;
BA_ "GenSigSendType" SG_ 2155233280 UtlChrgIntrfrIO 10;
BA_ "GenSigSendOnInit" SG_ 2155233280 UtlChrgIntrfrIO 1;
BA_ "VNSigInfotainment" SG_ 2155233280 UtlChrgIntrfrIO 1;
BA_ "SignalType" SG_ 2155233280 UtlChrgIntrfrIO "BLN";
BA_ "SignalLongName" SG_ 2155233280 UtlChrgIntrfrIO "Utility Charging Interference Indication On";
BA_ "VNSigAllNodes" SG_ 2155233280 UtlChrgIntrfrIO 1;
BA_ "GenSigSendType" SG_ 2155364352 CstmrUsblSOCV 10;
BA_ "GenSigSendOnInit" SG_ 2155364352 CstmrUsblSOCV 1;
BA_ "VNSigInfotainment" SG_ 2155364352 CstmrUsblSOCV 1;
BA_ "SignalType" SG_ 2155364352 CstmrUsblSOCV "ENM";
BA_ "SignalLongName" SG_ 2155364352 CstmrUsblSOCV "Customer Usable State of Charge Validity";
BA_ "VNSigAllNodes" SG_ 2155364352 CstmrUsblSOCV 1;
BA_ "GenSigDeltaValue" SG_ 2155364352 InstDrvEff 1;
BA_ "GenSigSendType" SG_ 2155364352 InstDrvEff 12;
BA_ "GenSigSendOnInit" SG_ 2155364352 InstDrvEff 1;
BA_ "VNSigInfotainment" SG_ 2155364352 InstDrvEff 1;
BA_ "SignalType" SG_ 2155364352 InstDrvEff "SNM";
BA_ "SignalLongName" SG_ 2155364352 InstDrvEff "Instantaneous Drive Efficiency";
BA_ "VNSigAllNodes" SG_ 2155364352 InstDrvEff 1;
BA_ "GenSigSendType" SG_ 2155364352 BattCntrlPrcssrVDA 10;
BA_ "GenSigSendOnInit" SG_ 2155364352 BattCntrlPrcssrVDA 1;
BA_ "VNSigInfotainment" SG_ 2155364352 BattCntrlPrcssrVDA 1;
BA_ "SignalType" SG_ 2155364352 BattCntrlPrcssrVDA "ENM";
BA_ "SignalLongName" SG_ 2155364352 BattCntrlPrcssrVDA "Battery Control Processor Virtual Device Availability";
BA_ "GenSigStartValue" SG_ 2155364352 BattCntrlPrcssrVDA 1;
BA_ "VNSigAllNodes" SG_ 2155364352 BattCntrlPrcssrVDA 1;
BA_ "GenSigSendType" SG_ 2155364352 JmpStrtStat 10;
BA_ "GenSigSendOnInit" SG_ 2155364352 JmpStrtStat 1;
BA_ "VNSigInfotainment" SG_ 2155364352 JmpStrtStat 1;
BA_ "SignalType" SG_ 2155364352 JmpStrtStat "ENM";
BA_ "SignalLongName" SG_ 2155364352 JmpStrtStat "Jump Start Status";
BA_ "VNSigAllNodes" SG_ 2155364352 JmpStrtStat 1;
BA_ "GenSigDeltaValue" SG_ 2155364352 CstmrUsblSOC 1;
BA_ "GenSigSendType" SG_ 2155364352 CstmrUsblSOC 12;
BA_ "GenSigSendOnInit" SG_ 2155364352 CstmrUsblSOC 1;
BA_ "VNSigInfotainment" SG_ 2155364352 CstmrUsblSOC 1;
BA_ "SignalType" SG_ 2155364352 CstmrUsblSOC "UNM";
BA_ "SignalLongName" SG_ 2155364352 CstmrUsblSOC "Customer Usable State of Charge";
BA_ "VNSigAllNodes" SG_ 2155364352 CstmrUsblSOC 1;
BA_ "GenSigSendType" SG_ 2155364352 SvcHybridSysIO 10;
BA_ "GenSigSendOnInit" SG_ 2155364352 SvcHybridSysIO 1;
BA_ "VNSigInfotainment" SG_ 2155364352 SvcHybridSysIO 1;
BA_ "SignalType" SG_ 2155364352 SvcHybridSysIO "BLN";
BA_ "SignalLongName" SG_ 2155364352 SvcHybridSysIO "Service Hybrid System Indication On";
BA_ "VNSigAllNodes" SG_ 2155364352 SvcHybridSysIO 1;
BA_ "GenSigSendType" SG_ 2155364352 HybMdDisp 10;
BA_ "GenSigSendOnInit" SG_ 2155364352 HybMdDisp 1;
BA_ "VNSigInfotainment" SG_ 2155364352 HybMdDisp 1;
BA_ "SignalType" SG_ 2155364352 HybMdDisp "ENM";
BA_ "SignalLongName" SG_ 2155364352 HybMdDisp "Hybrid Mode Display";
BA_ "VNSigAllNodes" SG_ 2155364352 HybMdDisp 1;
BA_ "GenSigDeltaValue" SG_ 2155364352 ClntCrcFlwRtEst 1;
BA_ "GenSigSendType" SG_ 2155364352 ClntCrcFlwRtEst 12;
BA_ "GenSigSendOnInit" SG_ 2155364352 ClntCrcFlwRtEst 1;
BA_ "VNSigInfotainment" SG_ 2155364352 ClntCrcFlwRtEst 1;
BA_ "SignalType" SG_ 2155364352 ClntCrcFlwRtEst "UNM";
BA_ "SignalLongName" SG_ 2155364352 ClntCrcFlwRtEst "Coolant Circulation Flow Rate Estimated";
BA_ "VNSigAllNodes" SG_ 2155364352 ClntCrcFlwRtEst 1;
BA_ "GenSigSendType" SG_ 2155184128 SmPhRmFunCstCurStVal 10;
BA_ "VNSigInfotainment" SG_ 2155184128 SmPhRmFunCstCurStVal 1;
BA_ "SignalType" SG_ 2155184128 SmPhRmFunCstCurStVal "ENM";
BA_ "SignalLongName" SG_ 2155184128 SmPhRmFunCstCurStVal "Smart Phone Remote Function Customization Current Setting Value";
BA_ "VNSigAllNodes" SG_ 2155184128 SmPhRmFunCstCurStVal 1;
BA_ "GenSigSendType" SG_ 2155184128 SmPhRmFunCstStAval 10;
BA_ "VNSigInfotainment" SG_ 2155184128 SmPhRmFunCstStAval 1;
BA_ "SignalType" SG_ 2155184128 SmPhRmFunCstStAval "BLN";
BA_ "SignalLongName" SG_ 2155184128 SmPhRmFunCstStAval "Smart Phone Remote Function Customization Setting Available";
BA_ "VNSigAllNodes" SG_ 2155184128 SmPhRmFunCstStAval 1;
BA_ "GenSigSendType" SG_ 2155184128 RrStRmndrIO 10;
BA_ "SignalType" SG_ 2155184128 RrStRmndrIO "BLN";
BA_ "SignalLongName" SG_ 2155184128 RrStRmndrIO "Rear Seat Reminder Indication On";
BA_ "VNSigAllNodes" SG_ 2155184128 RrStRmndrIO 1;
BA_ "GenSigSendType" SG_ 2155184128 RrStRmndrCstCurrSetVal 10;
BA_ "SignalType" SG_ 2155184128 RrStRmndrCstCurrSetVal "ENM";
BA_ "SignalLongName" SG_ 2155184128 RrStRmndrCstCurrSetVal "Rear Seat Reminder Customization Current Setting Value";
BA_ "VNSigAllNodes" SG_ 2155184128 RrStRmndrCstCurrSetVal 1;
BA_ "GenSigSendType" SG_ 2155184128 RrStRmndrCstSetAvail 10;
BA_ "SignalType" SG_ 2155184128 RrStRmndrCstSetAvail "BLN";
BA_ "SignalLongName" SG_ 2155184128 RrStRmndrCstSetAvail "Rear Seat Reminder Customization Setting Available";
BA_ "VNSigAllNodes" SG_ 2155184128 RrStRmndrCstSetAvail 1;
BA_ "GenSigSendType" SG_ 2155184128 TrnsShftLvrLckStat 10;
BA_ "SignalType" SG_ 2155184128 TrnsShftLvrLckStat "ENM";
BA_ "SignalLongName" SG_ 2155184128 TrnsShftLvrLckStat "Transmission Shift Lever Lock Status";
BA_ "VNSigAllNodes" SG_ 2155184128 TrnsShftLvrLckStat 1;
BA_ "GenSigSendType" SG_ 2155184128 CrsSpdLmtrSwStat 10;
BA_ "SignalType" SG_ 2155184128 CrsSpdLmtrSwStat "ENM";
BA_ "SignalLongName" SG_ 2155184128 CrsSpdLmtrSwStat "Cruise and Speed Limiter Switch Status";
BA_ "VNSigAllNodes" SG_ 2155184128 CrsSpdLmtrSwStat 1;
BA_ "GenSigSendType" SG_ 2155184128 CrsCntrlSwStCanSwAct 10;
BA_ "GenSigSendOnInit" SG_ 2155184128 CrsCntrlSwStCanSwAct 2;
BA_ "SignalType" SG_ 2155184128 CrsCntrlSwStCanSwAct "BLN";
BA_ "PacketOrder" SG_ 2155184128 CrsCntrlSwStCanSwAct 1;
BA_ "SignalLongName" SG_ 2155184128 CrsCntrlSwStCanSwAct "Cruise Control Switch Status : Cancel Switch Active";
BA_ "VNSigAllNodes" SG_ 2155184128 CrsCntrlSwStCanSwAct 1;
BA_ "GenSigSendType" SG_ 2155184128 CrsCntrlSwStSwDataIntgty 10;
BA_ "GenSigSendOnInit" SG_ 2155184128 CrsCntrlSwStSwDataIntgty 2;
BA_ "SignalType" SG_ 2155184128 CrsCntrlSwStSwDataIntgty "ENM";
BA_ "PacketOrder" SG_ 2155184128 CrsCntrlSwStSwDataIntgty 7;
BA_ "SignalLongName" SG_ 2155184128 CrsCntrlSwStSwDataIntgty "Cruise Control Switch Status : Switch Data Integrity";
BA_ "VNSigAllNodes" SG_ 2155184128 CrsCntrlSwStSwDataIntgty 1;
BA_ "GenSigSendType" SG_ 2155184128 CrsCntrlSwStSpdInSwAct 10;
BA_ "GenSigSendOnInit" SG_ 2155184128 CrsCntrlSwStSpdInSwAct 2;
BA_ "SignalType" SG_ 2155184128 CrsCntrlSwStSpdInSwAct "BLN";
BA_ "PacketOrder" SG_ 2155184128 CrsCntrlSwStSpdInSwAct 5;
BA_ "SignalLongName" SG_ 2155184128 CrsCntrlSwStSpdInSwAct "Cruise Control Switch Status : Speed Increase Switch Active";
BA_ "VNSigAllNodes" SG_ 2155184128 CrsCntrlSwStSpdInSwAct 1;
BA_ "GenSigSendType" SG_ 2155184128 CrsCntrlSwStSpDcSwAct 10;
BA_ "GenSigSendOnInit" SG_ 2155184128 CrsCntrlSwStSpDcSwAct 2;
BA_ "SignalType" SG_ 2155184128 CrsCntrlSwStSpDcSwAct "BLN";
BA_ "PacketOrder" SG_ 2155184128 CrsCntrlSwStSpDcSwAct 6;
BA_ "SignalLongName" SG_ 2155184128 CrsCntrlSwStSpDcSwAct "Cruise Control Switch Status : Speed Decrease Switch Active";
BA_ "VNSigAllNodes" SG_ 2155184128 CrsCntrlSwStSpDcSwAct 1;
BA_ "GenSigSendType" SG_ 2155184128 CrsCntrlSwStSetSwAct 10;
BA_ "GenSigSendOnInit" SG_ 2155184128 CrsCntrlSwStSetSwAct 2;
BA_ "SignalType" SG_ 2155184128 CrsCntrlSwStSetSwAct "BLN";
BA_ "PacketOrder" SG_ 2155184128 CrsCntrlSwStSetSwAct 4;
BA_ "SignalLongName" SG_ 2155184128 CrsCntrlSwStSetSwAct "Cruise Control Switch Status : Set Switch Active";
BA_ "VNSigAllNodes" SG_ 2155184128 CrsCntrlSwStSetSwAct 1;
BA_ "GenSigSendType" SG_ 2155184128 CrsCntrlSwStResSwAct 10;
BA_ "GenSigSendOnInit" SG_ 2155184128 CrsCntrlSwStResSwAct 2;
BA_ "SignalType" SG_ 2155184128 CrsCntrlSwStResSwAct "BLN";
BA_ "PacketOrder" SG_ 2155184128 CrsCntrlSwStResSwAct 3;
BA_ "SignalLongName" SG_ 2155184128 CrsCntrlSwStResSwAct "Cruise Control Switch Status : Resume Switch Active";
BA_ "VNSigAllNodes" SG_ 2155184128 CrsCntrlSwStResSwAct 1;
BA_ "GenSigSendType" SG_ 2155184128 CrsCntrlSwStOnSwAct 10;
BA_ "GenSigSendOnInit" SG_ 2155184128 CrsCntrlSwStOnSwAct 2;
BA_ "SignalType" SG_ 2155184128 CrsCntrlSwStOnSwAct "BLN";
BA_ "PacketOrder" SG_ 2155184128 CrsCntrlSwStOnSwAct 2;
BA_ "SignalLongName" SG_ 2155184128 CrsCntrlSwStOnSwAct "Cruise Control Switch Status : On Switch Active";
BA_ "VNSigAllNodes" SG_ 2155184128 CrsCntrlSwStOnSwAct 1;
BA_ "GenSigSendType" SG_ 2155184128 CrsCntAtv 10;
BA_ "GenSigSendOnInit" SG_ 2155184128 CrsCntAtv 2;
BA_ "SignalType" SG_ 2155184128 CrsCntAtv "BLN";
BA_ "SignalLongName" SG_ 2155184128 CrsCntAtv "Cruise Control Active";
BA_ "VNSigAllNodes" SG_ 2155184128 CrsCntAtv 1;
BA_ "GenSigSendType" SG_ 2155184128 IdlRecmndToClEngIO 10;
BA_ "SignalType" SG_ 2155184128 IdlRecmndToClEngIO "BLN";
BA_ "SignalLongName" SG_ 2155184128 IdlRecmndToClEngIO "Idle Recommended to Cool Engine Indication On";
BA_ "VNSigAllNodes" SG_ 2155184128 IdlRecmndToClEngIO 1;
BA_REL_ "GenSigSuprvResp" BU_SG_REL_ VCU_LE SG_ 2150547456 HVDpltnMdCnfdcTrndg 1;
BA_REL_ "GenSigSuprvResp" BU_SG_REL_ IPC_LE SG_ 2150547456 HVDpltnMdCnfdcTrndg 1;
BA_REL_ "GenSigSuprvResp" BU_SG_REL_ VCU_LE SG_ 2150547456 OffBrdHVCVehPwrLvl 1;
BA_REL_ "GenSigSuprvResp" BU_SG_REL_ CSM_LE SG_ 2150547456 OffBrdHVCVehPwrLvl 1;
BA_REL_ "GenSigSuprvResp" BU_SG_REL_ RadioHead_LE SG_ 2150547456 OffBrdHVCVehPwrLvl 1;
BA_REL_ "GenSigSuprvResp" BU_SG_REL_ VCU_LE SG_ 2150547456 OffBrdHVCVehPwrDrtd 1;
BA_REL_ "GenSigSuprvResp" BU_SG_REL_ CSM_LE SG_ 2150547456 OffBrdHVCVehPwrDrtd 1;
BA_REL_ "GenSigSuprvResp" BU_SG_REL_ RadioHead_LE SG_ 2150547456 OffBrdHVCVehPwrDrtd 1;
BA_REL_ "GenSigSuprvResp" BU_SG_REL_ VCU_LE SG_ 2150547456 OffBrdHVCVehCplrLkd 1;
BA_REL_ "GenSigSuprvResp" BU_SG_REL_ CSM_LE SG_ 2150547456 OffBrdHVCVehCplrLkd 1;
BA_REL_ "GenSigSuprvResp" BU_SG_REL_ RadioHead_LE SG_ 2150547456 OffBrdHVCVehCplrLkd 1;
BA_REL_ "GenSigSuprvResp" BU_SG_REL_ VCU_LE SG_ 2150547456 OffBrdHVBlkChrgCmp 1;
BA_REL_ "GenSigSuprvResp" BU_SG_REL_ IPC_LE SG_ 2150547456 OffBrdHVBlkChrgCmp 1;
BA_REL_ "GenSigSuprvResp" BU_SG_REL_ CSM_LE SG_ 2150547456 OBHVBCCT_MinofHr 1;
BA_REL_ "GenSigSuprvResp" BU_SG_REL_ RadioHead_LE SG_ 2150547456 OBHVBCCT_MinofHr 1;
BA_REL_ "GenSigSuprvResp" BU_SG_REL_ VCU_LE SG_ 2150547456 OBHVBCCT_MinofHr 1;
BA_REL_ "GenSigSuprvResp" BU_SG_REL_ VCU_LE SG_ 2150547456 OBHVBCCT_MinofHr 1;
BA_REL_ "GenSigSuprvResp" BU_SG_REL_ IPC_LE SG_ 2150547456 OBHVBCCT_MinofHr 1;
BA_REL_ "GenSigSuprvResp" BU_SG_REL_ CSM_LE SG_ 2150547456 OBHVBCCT_HrofDay 1;
BA_REL_ "GenSigSuprvResp" BU_SG_REL_ RadioHead_LE SG_ 2150547456 OBHVBCCT_HrofDay 1;
BA_REL_ "GenSigSuprvResp" BU_SG_REL_ VCU_LE SG_ 2150547456 OBHVBCCT_HrofDay 1;
BA_REL_ "GenSigSuprvResp" BU_SG_REL_ VCU_LE SG_ 2150547456 OBHVBCCT_HrofDay 1;
BA_REL_ "GenSigSuprvResp" BU_SG_REL_ IPC_LE SG_ 2150547456 OBHVBCCT_HrofDay 1;
BA_REL_ "GenSigSuprvResp" BU_SG_REL_ CSM_LE SG_ 2150547456 OBHVBCCT_DayofWk 1;
BA_REL_ "GenSigSuprvResp" BU_SG_REL_ RadioHead_LE SG_ 2150547456 OBHVBCCT_DayofWk 1;
BA_REL_ "GenSigSuprvResp" BU_SG_REL_ VCU_LE SG_ 2150547456 OBHVBCCT_DayofWk 1;
BA_REL_ "GenSigSuprvResp" BU_SG_REL_ VCU_LE SG_ 2150547456 OBHVBCCT_DayofWk 1;
BA_REL_ "GenSigSuprvResp" BU_SG_REL_ IPC_LE SG_ 2150547456 OBHVBCCT_DayofWk 1;
BA_REL_ "GenSigSuprvResp" BU_SG_REL_ VCU_LE SG_ 2150547456 ElecPrplsnMtrOvrSpdIO 1;
BA_REL_ "GenSigSuprvResp" BU_SG_REL_ IPC_LE SG_ 2150547456 ElecPrplsnMtrOvrSpdIO 1;
BA_REL_ "GenSigSuprvResp" BU_SG_REL_ VCU_LE SG_ 2150547456 HVBatCntctrsOpnIO 1;
BA_REL_ "GenSigSuprvResp" BU_SG_REL_ IPC_LE SG_ 2150547456 HVBatCntctrsOpnIO 1;
BA_REL_ "GenSigSuprvResp" BU_SG_REL_ CSM_LE SG_ 2150547456 HVDpltnMdRng 1;
BA_REL_ "GenSigSuprvResp" BU_SG_REL_ RadioHead_LE SG_ 2150547456 HVDpltnMdRng 1;
BA_REL_ "GenSigSuprvResp" BU_SG_REL_ RadioHead_LE SG_ 2150547456 HVDpltnMdRng 1;
BA_REL_ "GenSigSuprvResp" BU_SG_REL_ VCU_LE SG_ 2150547456 HVDpltnMdRng 1;
BA_REL_ "GenSigSuprvResp" BU_SG_REL_ VCU_LE SG_ 2150547456 HVDpltnMdRng 1;
BA_REL_ "GenSigSuprvResp" BU_SG_REL_ VCU_LE SG_ 2149752832 SndEnhcmtPerfMdRq 1;
BA_REL_ "GenSigSuprvResp" BU_SG_REL_ IPC_LE SG_ 2149752832 SndEnhcmtPerfMdRq 1;
BA_REL_ "GenSigSuprvResp" BU_SG_REL_ V2V_LE SG_ 2149752832 ElecPrkBrkStat 1;
BA_REL_ "GenSigSuprvResp" BU_SG_REL_ ONSTAR_LE SG_ 2149752832 ElecPrkBrkStat 1;
BA_REL_ "GenSigSuprvResp" BU_SG_REL_ TCP_LE SG_ 2149752832 ElecPrkBrkStat 1;
BA_REL_ "GenSigSuprvResp" BU_SG_REL_ LVMNav_LE SG_ 2149752832 ElecPrkBrkStat 1;
BA_REL_ "GenSigSuprvResp" BU_SG_REL_ VPM_LE SG_ 2149752832 SprTireSt 1;
BA_REL_ "GenSigVBitResp" BU_SG_REL_ VPM_LE SG_ 2149752832 VehHghtStat 1;
BA_REL_ "GenSigVBitRespComment" BU_SG_REL_ VPM_LE SG_ 2149752832 VehHghtStat "VehHghtStatV";
BA_REL_ "GenSigSuprvResp" BU_SG_REL_ VPM_LE SG_ 2149752832 VehHghtStat 1;
BA_REL_ "GenSigSuprvResp" BU_SG_REL_ TCP_LE SG_ 2156216320 TxtTelephoneDevPr 1;
BA_REL_ "GenSigSuprvResp" BU_SG_REL_ ONSTAR_LE SG_ 2156216320 TxtTelephoneDevPr 1;
BA_REL_ "GenSigSuprvResp" BU_SG_REL_ ONSTAR_LE SG_ 2149883904 BTPR_RspVal 1;
BA_REL_ "GenSigSuprvResp" BU_SG_REL_ ONSTAR_LE SG_ 2149883904 BTPR_RspInfoAvail 1;
BA_REL_ "GenSigSuprvResp" BU_SG_REL_ ONSTAR_LE SG_ 2149883904 BTPR_RspStat 1;
BA_REL_ "GenSigSuprvResp" BU_SG_REL_ VCU_LE SG_ 2149900288 BTTethrngPrngReq 1;
BA_REL_ "GenSigSuprvResp" BU_SG_REL_ RadioHead_LE SG_ 2149900288 BTTethrngPrngReq 1;
BA_REL_ "GenSigSuprvResp" BU_SG_REL_ TCP_LE SG_ 2150023168 OffBrdVehImmbNot 1;
BA_REL_ "GenSigSuprvResp" BU_SG_REL_ TCP_LE SG_ 2150023168 OffBrdVehImmbNot 1;
BA_REL_ "GenSigSuprvResp" BU_SG_REL_ ONSTAR_LE SG_ 2150023168 OffBrdVehImmbNot 1;
BA_REL_ "GenSigSuprvResp" BU_SG_REL_ ONSTAR_LE SG_ 2150023168 OffBrdVehImmbNot 1;
BA_REL_ "GenSigSuprvResp" BU_SG_REL_ VCU_LE SG_ 2150023168 ElecPrplsnMtrTach 1;
BA_REL_ "GenSigSuprvResp" BU_SG_REL_ IPC_LE SG_ 2150023168 ElecPrplsnMtrTach 1;
BA_REL_ "GenSigSuprvResp" BU_SG_REL_ V2V_LE SG_ 2150285312 PsngSysHding 1;
BA_REL_ "GenSigSuprvResp" BU_SG_REL_ V2V_LE SG_ 2150285312 PsngSysElvtn 1;
BA_REL_ "GenSigSuprvResp" BU_SG_REL_ V2V_LE SG_ 2150285312 PsngSysDilPrcs 1;
BA_REL_ "GenSigSuprvResp" BU_SG_REL_ V2V_LE SG_ 2150285312 PsngSysCalcSpd 1;
BA_REL_ "GenSigSuprvResp" BU_SG_REL_ V2V_LE SG_ 2150277120 PsngSysLong 1;
BA_REL_ "GenSigSuprvResp" BU_SG_REL_ V2V_LE SG_ 2150277120 PsngSysLat 1;
BA_REL_ "GenSigSuprvResp" BU_SG_REL_ VCU_LE SG_ 2156806144 CellNtwrkDtTmAvl 1;
BA_REL_ "GenSigSuprvResp" BU_SG_REL_ CSM_LE SG_ 2156806144 CellNtwrkDtTmAvl 1;
BA_REL_ "GenSigSuprvResp" BU_SG_REL_ RadioHead_LE SG_ 2156806144 CellNtwrkDtTmAvl 1;
BA_REL_ "GenSigSuprvResp" BU_SG_REL_ VCU_LE SG_ 2155872256 DrvStyPerfMdCsCrStVal 1;
BA_REL_ "GenSigSuprvResp" BU_SG_REL_ CSM_LE SG_ 2155872256 DrvStyPerfMdCsCrStVal 1;
BA_REL_ "GenSigSuprvResp" BU_SG_REL_ RadioHead_LE SG_ 2155872256 DrvStyPerfMdCsCrStVal 1;
BA_REL_ "GenSigSuprvResp" BU_SG_REL_ VCU_LE SG_ 2155872256 DrvStyPerfMdCsStAvl 1;
BA_REL_ "GenSigSuprvResp" BU_SG_REL_ CSM_LE SG_ 2155872256 DrvStyPerfMdCsStAvl 1;
BA_REL_ "GenSigSuprvResp" BU_SG_REL_ RadioHead_LE SG_ 2155872256 DrvStyPerfMdCsStAvl 1;
BA_REL_ "GenSigVBitResp" BU_SG_REL_ VPM_LE SG_ 2155872256 RdWhlAng 1;
BA_REL_ "GenSigVBitRespComment" BU_SG_REL_ VPM_LE SG_ 2155872256 RdWhlAng "RdWhlAngV";
BA_REL_ "GenSigSuprvResp" BU_SG_REL_ VPM_LE SG_ 2155872256 RdWhlAng 1;
BA_REL_ "GenSigSuprvResp" BU_SG_REL_ CSM_LE SG_ 2155872256 FlLvlPct 1;
BA_REL_ "GenSigSuprvResp" BU_SG_REL_ RadioHead_LE SG_ 2155872256 FlLvlPct 1;
BA_REL_ "GenSigSuprvResp" BU_SG_REL_ RadioHead_LE SG_ 2155872256 FlLvlPct 1;
BA_REL_ "GenSigSuprvResp" BU_SG_REL_ VCU_LE SG_ 2155872256 FlLvlPct 1;
BA_REL_ "GenSigSuprvResp" BU_SG_REL_ VCU_LE SG_ 2155872256 FlLvlPct 1;
BA_REL_ "GenSigSuprvResp" BU_SG_REL_ VCU_LE SG_ 2151972864 VehFuelRngCalc 1;
BA_REL_ "GenSigSuprvResp" BU_SG_REL_ CSM_LE SG_ 2151972864 VehFuelRngCalc 1;
BA_REL_ "GenSigSuprvResp" BU_SG_REL_ RadioHead_LE SG_ 2151972864 VehFuelRngCalc 1;
BA_REL_ "GenSigSuprvResp" BU_SG_REL_ VCU_LE SG_ 2152095744 SPMCA_SusPrfMd6Avl 1;
BA_REL_ "GenSigSuprvResp" BU_SG_REL_ CSM_LE SG_ 2152095744 SPMCA_SusPrfMd6Avl 1;
BA_REL_ "GenSigSuprvResp" BU_SG_REL_ RadioHead_LE SG_ 2152095744 SPMCA_SusPrfMd6Avl 1;
BA_REL_ "GenSigSuprvResp" BU_SG_REL_ VCU_LE SG_ 2152095744 SPMCA_SusPrfMd5Avl 1;
BA_REL_ "GenSigSuprvResp" BU_SG_REL_ CSM_LE SG_ 2152095744 SPMCA_SusPrfMd5Avl 1;
BA_REL_ "GenSigSuprvResp" BU_SG_REL_ RadioHead_LE SG_ 2152095744 SPMCA_SusPrfMd5Avl 1;
BA_REL_ "GenSigSuprvResp" BU_SG_REL_ VCU_LE SG_ 2152095744 SPMCA_SusPrfMd4Avl 1;
BA_REL_ "GenSigSuprvResp" BU_SG_REL_ CSM_LE SG_ 2152095744 SPMCA_SusPrfMd4Avl 1;
BA_REL_ "GenSigSuprvResp" BU_SG_REL_ RadioHead_LE SG_ 2152095744 SPMCA_SusPrfMd4Avl 1;
BA_REL_ "GenSigSuprvResp" BU_SG_REL_ VCU_LE SG_ 2152095744 SPMCA_SusPrfMd3Avl 1;
BA_REL_ "GenSigSuprvResp" BU_SG_REL_ CSM_LE SG_ 2152095744 SPMCA_SusPrfMd3Avl 1;
BA_REL_ "GenSigSuprvResp" BU_SG_REL_ RadioHead_LE SG_ 2152095744 SPMCA_SusPrfMd3Avl 1;
BA_REL_ "GenSigSuprvResp" BU_SG_REL_ VCU_LE SG_ 2152095744 SPMCA_SusPrfMd2Avl 1;
BA_REL_ "GenSigSuprvResp" BU_SG_REL_ CSM_LE SG_ 2152095744 SPMCA_SusPrfMd2Avl 1;
BA_REL_ "GenSigSuprvResp" BU_SG_REL_ RadioHead_LE SG_ 2152095744 SPMCA_SusPrfMd2Avl 1;
BA_REL_ "GenSigSuprvResp" BU_SG_REL_ VCU_LE SG_ 2152095744 SPMCA_SusPrfMd1Avl 1;
BA_REL_ "GenSigSuprvResp" BU_SG_REL_ CSM_LE SG_ 2152095744 SPMCA_SusPrfMd1Avl 1;
BA_REL_ "GenSigSuprvResp" BU_SG_REL_ RadioHead_LE SG_ 2152095744 SPMCA_SusPrfMd1Avl 1;
BA_REL_ "GenSigSuprvResp" BU_SG_REL_ VCU_LE SG_ 2152095744 SPMCA_StrPrfMd6Avl 1;
BA_REL_ "GenSigSuprvResp" BU_SG_REL_ CSM_LE SG_ 2152095744 SPMCA_StrPrfMd6Avl 1;
BA_REL_ "GenSigSuprvResp" BU_SG_REL_ RadioHead_LE SG_ 2152095744 SPMCA_StrPrfMd6Avl 1;
BA_REL_ "GenSigSuprvResp" BU_SG_REL_ VCU_LE SG_ 2152095744 SPMCA_StrPrfMd5Avl 1;
BA_REL_ "GenSigSuprvResp" BU_SG_REL_ CSM_LE SG_ 2152095744 SPMCA_StrPrfMd5Avl 1;
BA_REL_ "GenSigSuprvResp" BU_SG_REL_ RadioHead_LE SG_ 2152095744 SPMCA_StrPrfMd5Avl 1;
BA_REL_ "GenSigSuprvResp" BU_SG_REL_ VCU_LE SG_ 2152095744 SPMCA_StrPrfMd4Avl 1;
BA_REL_ "GenSigSuprvResp" BU_SG_REL_ CSM_LE SG_ 2152095744 SPMCA_StrPrfMd4Avl 1;
BA_REL_ "GenSigSuprvResp" BU_SG_REL_ RadioHead_LE SG_ 2152095744 SPMCA_StrPrfMd4Avl 1;
BA_REL_ "GenSigSuprvResp" BU_SG_REL_ VCU_LE SG_ 2152095744 SPMCA_StrPrfMd3Avl 1;
BA_REL_ "GenSigSuprvResp" BU_SG_REL_ CSM_LE SG_ 2152095744 SPMCA_StrPrfMd3Avl 1;
BA_REL_ "GenSigSuprvResp" BU_SG_REL_ RadioHead_LE SG_ 2152095744 SPMCA_StrPrfMd3Avl 1;
BA_REL_ "GenSigSuprvResp" BU_SG_REL_ VCU_LE SG_ 2152095744 SPMCA_StrPrfMd2Avl 1;
BA_REL_ "GenSigSuprvResp" BU_SG_REL_ CSM_LE SG_ 2152095744 SPMCA_StrPrfMd2Avl 1;
BA_REL_ "GenSigSuprvResp" BU_SG_REL_ RadioHead_LE SG_ 2152095744 SPMCA_StrPrfMd2Avl 1;
BA_REL_ "GenSigSuprvResp" BU_SG_REL_ VCU_LE SG_ 2152095744 SPMCA_StrPrfMd1Avl 1;
BA_REL_ "GenSigSuprvResp" BU_SG_REL_ CSM_LE SG_ 2152095744 SPMCA_StrPrfMd1Avl 1;
BA_REL_ "GenSigSuprvResp" BU_SG_REL_ RadioHead_LE SG_ 2152095744 SPMCA_StrPrfMd1Avl 1;
BA_REL_ "GenSigSuprvResp" BU_SG_REL_ VCU_LE SG_ 2152095744 SPMCA_SndPrfMd6Avl 1;
BA_REL_ "GenSigSuprvResp" BU_SG_REL_ CSM_LE SG_ 2152095744 SPMCA_SndPrfMd6Avl 1;
BA_REL_ "GenSigSuprvResp" BU_SG_REL_ RadioHead_LE SG_ 2152095744 SPMCA_SndPrfMd6Avl 1;
BA_REL_ "GenSigSuprvResp" BU_SG_REL_ VCU_LE SG_ 2152095744 SPMCA_SndPrfMd5Avl 1;
BA_REL_ "GenSigSuprvResp" BU_SG_REL_ CSM_LE SG_ 2152095744 SPMCA_SndPrfMd5Avl 1;
BA_REL_ "GenSigSuprvResp" BU_SG_REL_ RadioHead_LE SG_ 2152095744 SPMCA_SndPrfMd5Avl 1;
BA_REL_ "GenSigSuprvResp" BU_SG_REL_ VCU_LE SG_ 2152095744 SPMCA_SndPrfMd4Avl 1;
BA_REL_ "GenSigSuprvResp" BU_SG_REL_ CSM_LE SG_ 2152095744 SPMCA_SndPrfMd4Avl 1;
BA_REL_ "GenSigSuprvResp" BU_SG_REL_ RadioHead_LE SG_ 2152095744 SPMCA_SndPrfMd4Avl 1;
BA_REL_ "GenSigSuprvResp" BU_SG_REL_ VCU_LE SG_ 2152095744 SPMCA_SndPrfMd3Avl 1;
BA_REL_ "GenSigSuprvResp" BU_SG_REL_ CSM_LE SG_ 2152095744 SPMCA_SndPrfMd3Avl 1;
BA_REL_ "GenSigSuprvResp" BU_SG_REL_ RadioHead_LE SG_ 2152095744 SPMCA_SndPrfMd3Avl 1;
BA_REL_ "GenSigSuprvResp" BU_SG_REL_ VCU_LE SG_ 2152095744 SPMCA_SndPrfMd2Avl 1;
BA_REL_ "GenSigSuprvResp" BU_SG_REL_ CSM_LE SG_ 2152095744 SPMCA_SndPrfMd2Avl 1;
BA_REL_ "GenSigSuprvResp" BU_SG_REL_ RadioHead_LE SG_ 2152095744 SPMCA_SndPrfMd2Avl 1;
BA_REL_ "GenSigSuprvResp" BU_SG_REL_ VCU_LE SG_ 2152095744 SPMCA_SndPrfMd1Avl 1;
BA_REL_ "GenSigSuprvResp" BU_SG_REL_ CSM_LE SG_ 2152095744 SPMCA_SndPrfMd1Avl 1;
BA_REL_ "GenSigSuprvResp" BU_SG_REL_ RadioHead_LE SG_ 2152095744 SPMCA_SndPrfMd1Avl 1;
BA_REL_ "GenSigSuprvResp" BU_SG_REL_ VCU_LE SG_ 2152095744 DPMCA_DispPrfMd6Avl 1;
BA_REL_ "GenSigSuprvResp" BU_SG_REL_ VCU_LE SG_ 2152095744 DPMCA_DispPrfMd6Avl 1;
BA_REL_ "GenSigSuprvResp" BU_SG_REL_ CSM_LE SG_ 2152095744 DPMCA_DispPrfMd6Avl 1;
BA_REL_ "GenSigSuprvResp" BU_SG_REL_ CSM_LE SG_ 2152095744 DPMCA_DispPrfMd6Avl 1;
BA_REL_ "GenSigSuprvResp" BU_SG_REL_ RadioHead_LE SG_ 2152095744 DPMCA_DispPrfMd6Avl 1;
BA_REL_ "GenSigSuprvResp" BU_SG_REL_ RadioHead_LE SG_ 2152095744 DPMCA_DispPrfMd6Avl 1;
BA_REL_ "GenSigSuprvResp" BU_SG_REL_ VCU_LE SG_ 2152095744 DPMCA_DispPrfMd5Avl 1;
BA_REL_ "GenSigSuprvResp" BU_SG_REL_ VCU_LE SG_ 2152095744 DPMCA_DispPrfMd5Avl 1;
BA_REL_ "GenSigSuprvResp" BU_SG_REL_ CSM_LE SG_ 2152095744 DPMCA_DispPrfMd5Avl 1;
BA_REL_ "GenSigSuprvResp" BU_SG_REL_ CSM_LE SG_ 2152095744 DPMCA_DispPrfMd5Avl 1;
BA_REL_ "GenSigSuprvResp" BU_SG_REL_ RadioHead_LE SG_ 2152095744 DPMCA_DispPrfMd5Avl 1;
BA_REL_ "GenSigSuprvResp" BU_SG_REL_ RadioHead_LE SG_ 2152095744 DPMCA_DispPrfMd5Avl 1;
BA_REL_ "GenSigSuprvResp" BU_SG_REL_ VCU_LE SG_ 2152095744 DPMCA_DispPrfMd4Avl 1;
BA_REL_ "GenSigSuprvResp" BU_SG_REL_ VCU_LE SG_ 2152095744 DPMCA_DispPrfMd4Avl 1;
BA_REL_ "GenSigSuprvResp" BU_SG_REL_ CSM_LE SG_ 2152095744 DPMCA_DispPrfMd4Avl 1;
BA_REL_ "GenSigSuprvResp" BU_SG_REL_ CSM_LE SG_ 2152095744 DPMCA_DispPrfMd4Avl 1;
BA_REL_ "GenSigSuprvResp" BU_SG_REL_ RadioHead_LE SG_ 2152095744 DPMCA_DispPrfMd4Avl 1;
BA_REL_ "GenSigSuprvResp" BU_SG_REL_ RadioHead_LE SG_ 2152095744 DPMCA_DispPrfMd4Avl 1;
BA_REL_ "GenSigSuprvResp" BU_SG_REL_ VCU_LE SG_ 2152095744 DPMCA_DispPrfMd3Avl 1;
BA_REL_ "GenSigSuprvResp" BU_SG_REL_ VCU_LE SG_ 2152095744 DPMCA_DispPrfMd3Avl 1;
BA_REL_ "GenSigSuprvResp" BU_SG_REL_ CSM_LE SG_ 2152095744 DPMCA_DispPrfMd3Avl 1;
BA_REL_ "GenSigSuprvResp" BU_SG_REL_ CSM_LE SG_ 2152095744 DPMCA_DispPrfMd3Avl 1;
BA_REL_ "GenSigSuprvResp" BU_SG_REL_ RadioHead_LE SG_ 2152095744 DPMCA_DispPrfMd3Avl 1;
BA_REL_ "GenSigSuprvResp" BU_SG_REL_ RadioHead_LE SG_ 2152095744 DPMCA_DispPrfMd3Avl 1;
BA_REL_ "GenSigSuprvResp" BU_SG_REL_ VCU_LE SG_ 2152095744 DPMCA_DispPrfMd2Avl 1;
BA_REL_ "GenSigSuprvResp" BU_SG_REL_ VCU_LE SG_ 2152095744 DPMCA_DispPrfMd2Avl 1;
BA_REL_ "GenSigSuprvResp" BU_SG_REL_ CSM_LE SG_ 2152095744 DPMCA_DispPrfMd2Avl 1;
BA_REL_ "GenSigSuprvResp" BU_SG_REL_ CSM_LE SG_ 2152095744 DPMCA_DispPrfMd2Avl 1;
BA_REL_ "GenSigSuprvResp" BU_SG_REL_ RadioHead_LE SG_ 2152095744 DPMCA_DispPrfMd2Avl 1;
BA_REL_ "GenSigSuprvResp" BU_SG_REL_ RadioHead_LE SG_ 2152095744 DPMCA_DispPrfMd2Avl 1;
BA_REL_ "GenSigSuprvResp" BU_SG_REL_ VCU_LE SG_ 2152095744 DPMCA_DispPrfMd1Avl 1;
BA_REL_ "GenSigSuprvResp" BU_SG_REL_ VCU_LE SG_ 2152095744 DPMCA_DispPrfMd1Avl 1;
BA_REL_ "GenSigSuprvResp" BU_SG_REL_ CSM_LE SG_ 2152095744 DPMCA_DispPrfMd1Avl 1;
BA_REL_ "GenSigSuprvResp" BU_SG_REL_ CSM_LE SG_ 2152095744 DPMCA_DispPrfMd1Avl 1;
BA_REL_ "GenSigSuprvResp" BU_SG_REL_ RadioHead_LE SG_ 2152095744 DPMCA_DispPrfMd1Avl 1;
BA_REL_ "GenSigSuprvResp" BU_SG_REL_ RadioHead_LE SG_ 2152095744 DPMCA_DispPrfMd1Avl 1;
BA_REL_ "GenSigSuprvResp" BU_SG_REL_ VCU_LE SG_ 2152095744 DPMCA_DrvlPrfMd6Avl 1;
BA_REL_ "GenSigSuprvResp" BU_SG_REL_ VCU_LE SG_ 2152095744 DPMCA_DrvlPrfMd6Avl 1;
BA_REL_ "GenSigSuprvResp" BU_SG_REL_ CSM_LE SG_ 2152095744 DPMCA_DrvlPrfMd6Avl 1;
BA_REL_ "GenSigSuprvResp" BU_SG_REL_ CSM_LE SG_ 2152095744 DPMCA_DrvlPrfMd6Avl 1;
BA_REL_ "GenSigSuprvResp" BU_SG_REL_ RadioHead_LE SG_ 2152095744 DPMCA_DrvlPrfMd6Avl 1;
BA_REL_ "GenSigSuprvResp" BU_SG_REL_ RadioHead_LE SG_ 2152095744 DPMCA_DrvlPrfMd6Avl 1;
BA_REL_ "GenSigSuprvResp" BU_SG_REL_ VCU_LE SG_ 2152095744 DPMCA_DrvlPrfMd5Avl 1;
BA_REL_ "GenSigSuprvResp" BU_SG_REL_ VCU_LE SG_ 2152095744 DPMCA_DrvlPrfMd5Avl 1;
BA_REL_ "GenSigSuprvResp" BU_SG_REL_ CSM_LE SG_ 2152095744 DPMCA_DrvlPrfMd5Avl 1;
BA_REL_ "GenSigSuprvResp" BU_SG_REL_ CSM_LE SG_ 2152095744 DPMCA_DrvlPrfMd5Avl 1;
BA_REL_ "GenSigSuprvResp" BU_SG_REL_ RadioHead_LE SG_ 2152095744 DPMCA_DrvlPrfMd5Avl 1;
BA_REL_ "GenSigSuprvResp" BU_SG_REL_ RadioHead_LE SG_ 2152095744 DPMCA_DrvlPrfMd5Avl 1;
BA_REL_ "GenSigSuprvResp" BU_SG_REL_ VCU_LE SG_ 2152095744 DPMCA_DrvlPrfMd4Avl 1;
BA_REL_ "GenSigSuprvResp" BU_SG_REL_ VCU_LE SG_ 2152095744 DPMCA_DrvlPrfMd4Avl 1;
BA_REL_ "GenSigSuprvResp" BU_SG_REL_ CSM_LE SG_ 2152095744 DPMCA_DrvlPrfMd4Avl 1;
BA_REL_ "GenSigSuprvResp" BU_SG_REL_ CSM_LE SG_ 2152095744 DPMCA_DrvlPrfMd4Avl 1;
BA_REL_ "GenSigSuprvResp" BU_SG_REL_ RadioHead_LE SG_ 2152095744 DPMCA_DrvlPrfMd4Avl 1;
BA_REL_ "GenSigSuprvResp" BU_SG_REL_ RadioHead_LE SG_ 2152095744 DPMCA_DrvlPrfMd4Avl 1;
BA_REL_ "GenSigSuprvResp" BU_SG_REL_ VCU_LE SG_ 2152095744 DPMCA_DrvlPrfMd3Avl 1;
BA_REL_ "GenSigSuprvResp" BU_SG_REL_ VCU_LE SG_ 2152095744 DPMCA_DrvlPrfMd3Avl 1;
BA_REL_ "GenSigSuprvResp" BU_SG_REL_ CSM_LE SG_ 2152095744 DPMCA_DrvlPrfMd3Avl 1;
BA_REL_ "GenSigSuprvResp" BU_SG_REL_ CSM_LE SG_ 2152095744 DPMCA_DrvlPrfMd3Avl 1;
BA_REL_ "GenSigSuprvResp" BU_SG_REL_ RadioHead_LE SG_ 2152095744 DPMCA_DrvlPrfMd3Avl 1;
BA_REL_ "GenSigSuprvResp" BU_SG_REL_ RadioHead_LE SG_ 2152095744 DPMCA_DrvlPrfMd3Avl 1;
BA_REL_ "GenSigSuprvResp" BU_SG_REL_ VCU_LE SG_ 2152095744 DPMCA_DrvlPrfMd2Avl 1;
BA_REL_ "GenSigSuprvResp" BU_SG_REL_ VCU_LE SG_ 2152095744 DPMCA_DrvlPrfMd2Avl 1;
BA_REL_ "GenSigSuprvResp" BU_SG_REL_ CSM_LE SG_ 2152095744 DPMCA_DrvlPrfMd2Avl 1;
BA_REL_ "GenSigSuprvResp" BU_SG_REL_ CSM_LE SG_ 2152095744 DPMCA_DrvlPrfMd2Avl 1;
BA_REL_ "GenSigSuprvResp" BU_SG_REL_ RadioHead_LE SG_ 2152095744 DPMCA_DrvlPrfMd2Avl 1;
BA_REL_ "GenSigSuprvResp" BU_SG_REL_ RadioHead_LE SG_ 2152095744 DPMCA_DrvlPrfMd2Avl 1;
BA_REL_ "GenSigSuprvResp" BU_SG_REL_ VCU_LE SG_ 2152095744 DPMCA_DrvlPrfMd1Avl 1;
BA_REL_ "GenSigSuprvResp" BU_SG_REL_ VCU_LE SG_ 2152095744 DPMCA_DrvlPrfMd1Avl 1;
BA_REL_ "GenSigSuprvResp" BU_SG_REL_ CSM_LE SG_ 2152095744 DPMCA_DrvlPrfMd1Avl 1;
BA_REL_ "GenSigSuprvResp" BU_SG_REL_ CSM_LE SG_ 2152095744 DPMCA_DrvlPrfMd1Avl 1;
BA_REL_ "GenSigSuprvResp" BU_SG_REL_ RadioHead_LE SG_ 2152095744 DPMCA_DrvlPrfMd1Avl 1;
BA_REL_ "GenSigSuprvResp" BU_SG_REL_ RadioHead_LE SG_ 2152095744 DPMCA_DrvlPrfMd1Avl 1;
BA_REL_ "GenSigSuprvResp" BU_SG_REL_ VPM_LE SG_ 2155479040 RstrCustFctrDef 1;
BA_REL_ "GenSigSuprvResp" BU_SG_REL_ VCU_LE SG_ 2151981056 DrvCyclBatPropRat 1;
BA_REL_ "GenSigSuprvResp" BU_SG_REL_ VCU_LE SG_ 2151981056 DrvCyclBatPropRat 1;
BA_REL_ "GenSigSuprvResp" BU_SG_REL_ CSM_LE SG_ 2151981056 DrvCyclBatPropRat 1;
BA_REL_ "GenSigSuprvResp" BU_SG_REL_ RadioHead_LE SG_ 2151981056 DrvCyclBatPropRat 1;
BA_REL_ "GenSigSuprvResp" BU_SG_REL_ RadioHead_LE SG_ 2151981056 DrvCyclBatPropRat 1;
BA_REL_ "GenSigSuprvResp" BU_SG_REL_ VCU_LE SG_ 2151981056 DTD_FuelPrpDstTrvld 1;
BA_REL_ "GenSigSuprvResp" BU_SG_REL_ VCU_LE SG_ 2151981056 DTD_FuelPrpDstTrvld 1;
BA_REL_ "GenSigSuprvResp" BU_SG_REL_ CSM_LE SG_ 2151981056 DTD_FuelPrpDstTrvld 1;
BA_REL_ "GenSigSuprvResp" BU_SG_REL_ RadioHead_LE SG_ 2151981056 DTD_FuelPrpDstTrvld 1;
BA_REL_ "GenSigSuprvResp" BU_SG_REL_ RadioHead_LE SG_ 2151981056 DTD_FuelPrpDstTrvld 1;
BA_REL_ "GenSigSuprvResp" BU_SG_REL_ VCU_LE SG_ 2151981056 DTD_DrvCyclDstTrvld 1;
BA_REL_ "GenSigSuprvResp" BU_SG_REL_ VCU_LE SG_ 2151981056 DTD_DrvCyclDstTrvld 1;
BA_REL_ "GenSigSuprvResp" BU_SG_REL_ CSM_LE SG_ 2151981056 DTD_DrvCyclDstTrvld 1;
BA_REL_ "GenSigSuprvResp" BU_SG_REL_ RadioHead_LE SG_ 2151981056 DTD_DrvCyclDstTrvld 1;
BA_REL_ "GenSigSuprvResp" BU_SG_REL_ RadioHead_LE SG_ 2151981056 DTD_DrvCyclDstTrvld 1;
BA_REL_ "GenSigSuprvResp" BU_SG_REL_ VCU_LE SG_ 2151981056 DTD_BattPrpDstTrvld 1;
BA_REL_ "GenSigSuprvResp" BU_SG_REL_ VCU_LE SG_ 2151981056 DTD_BattPrpDstTrvld 1;
BA_REL_ "GenSigSuprvResp" BU_SG_REL_ CSM_LE SG_ 2151981056 DTD_BattPrpDstTrvld 1;
BA_REL_ "GenSigSuprvResp" BU_SG_REL_ RadioHead_LE SG_ 2151981056 DTD_BattPrpDstTrvld 1;
BA_REL_ "GenSigSuprvResp" BU_SG_REL_ RadioHead_LE SG_ 2151981056 DTD_BattPrpDstTrvld 1;
BA_REL_ "GenSigSuprvResp" BU_SG_REL_ VCU_LE SG_ 2151964672 DrvCyclTtlEnrgEfncy 1;
BA_REL_ "GenSigSuprvResp" BU_SG_REL_ VCU_LE SG_ 2151964672 DrvCyclTtlEnrgEfncy 1;
BA_REL_ "GenSigSuprvResp" BU_SG_REL_ CSM_LE SG_ 2151964672 DrvCyclTtlEnrgEfncy 1;
BA_REL_ "GenSigSuprvResp" BU_SG_REL_ RadioHead_LE SG_ 2151964672 DrvCyclTtlEnrgEfncy 1;
BA_REL_ "GenSigSuprvResp" BU_SG_REL_ RadioHead_LE SG_ 2151964672 DrvCyclTtlEnrgEfncy 1;
BA_REL_ "GenSigSuprvResp" BU_SG_REL_ VCU_LE SG_ 2151964672 DrvCyclFuelUsd 1;
BA_REL_ "GenSigSuprvResp" BU_SG_REL_ VCU_LE SG_ 2151964672 DrvCyclFuelUsd 1;
BA_REL_ "GenSigSuprvResp" BU_SG_REL_ CSM_LE SG_ 2151964672 DrvCyclFuelUsd 1;
BA_REL_ "GenSigSuprvResp" BU_SG_REL_ RadioHead_LE SG_ 2151964672 DrvCyclFuelUsd 1;
BA_REL_ "GenSigSuprvResp" BU_SG_REL_ RadioHead_LE SG_ 2151964672 DrvCyclFuelUsd 1;
BA_REL_ "GenSigSuprvResp" BU_SG_REL_ VCU_LE SG_ 2151964672 DrvCyclFuelEnmy 1;
BA_REL_ "GenSigSuprvResp" BU_SG_REL_ VCU_LE SG_ 2151964672 DrvCyclFuelEnmy 1;
BA_REL_ "GenSigSuprvResp" BU_SG_REL_ CSM_LE SG_ 2151964672 DrvCyclFuelEnmy 1;
BA_REL_ "GenSigSuprvResp" BU_SG_REL_ RadioHead_LE SG_ 2151964672 DrvCyclFuelEnmy 1;
BA_REL_ "GenSigSuprvResp" BU_SG_REL_ RadioHead_LE SG_ 2151964672 DrvCyclFuelEnmy 1;
BA_REL_ "GenSigSuprvResp" BU_SG_REL_ VCU_LE SG_ 2151964672 DrvCyclDrvStEnrgEfncy 1;
BA_REL_ "GenSigSuprvResp" BU_SG_REL_ VCU_LE SG_ 2151964672 DrvCyclDrvStEnrgEfncy 1;
BA_REL_ "GenSigSuprvResp" BU_SG_REL_ CSM_LE SG_ 2151964672 DrvCyclDrvStEnrgEfncy 1;
BA_REL_ "GenSigSuprvResp" BU_SG_REL_ RadioHead_LE SG_ 2151964672 DrvCyclDrvStEnrgEfncy 1;
BA_REL_ "GenSigSuprvResp" BU_SG_REL_ RadioHead_LE SG_ 2151964672 DrvCyclDrvStEnrgEfncy 1;
BA_REL_ "GenSigSuprvResp" BU_SG_REL_ VCU_LE SG_ 2151964672 DrvCyclCbnCondEnrgEfncy 1;
BA_REL_ "GenSigSuprvResp" BU_SG_REL_ VCU_LE SG_ 2151964672 DrvCyclCbnCondEnrgEfncy 1;
BA_REL_ "GenSigSuprvResp" BU_SG_REL_ CSM_LE SG_ 2151964672 DrvCyclCbnCondEnrgEfncy 1;
BA_REL_ "GenSigSuprvResp" BU_SG_REL_ RadioHead_LE SG_ 2151964672 DrvCyclCbnCondEnrgEfncy 1;
BA_REL_ "GenSigSuprvResp" BU_SG_REL_ RadioHead_LE SG_ 2151964672 DrvCyclCbnCondEnrgEfncy 1;
BA_REL_ "GenSigSuprvResp" BU_SG_REL_ VCU_LE SG_ 2151964672 DrvCyclBatCondEnrgEfncy 1;
BA_REL_ "GenSigSuprvResp" BU_SG_REL_ VCU_LE SG_ 2151964672 DrvCyclBatCondEnrgEfncy 1;
BA_REL_ "GenSigSuprvResp" BU_SG_REL_ CSM_LE SG_ 2151964672 DrvCyclBatCondEnrgEfncy 1;
BA_REL_ "GenSigSuprvResp" BU_SG_REL_ RadioHead_LE SG_ 2151964672 DrvCyclBatCondEnrgEfncy 1;
BA_REL_ "GenSigSuprvResp" BU_SG_REL_ RadioHead_LE SG_ 2151964672 DrvCyclBatCondEnrgEfncy 1;
BA_REL_ "GenSigSuprvResp" BU_SG_REL_ VCU_LE SG_ 2155233280 NtrlGrWrngIO 1;
BA_REL_ "GenSigSuprvResp" BU_SG_REL_ IPC_LE SG_ 2155233280 NtrlGrWrngIO 1;
BA_REL_ "GenSigSuprvResp" BU_SG_REL_ VCU_LE SG_ 2155233280 RtBsChrgCmplnTmPrfRsp 1;
BA_REL_ "GenSigSuprvResp" BU_SG_REL_ CSM_LE SG_ 2155233280 RtBsChrgCmplnTmPrfRsp 1;
BA_REL_ "GenSigSuprvResp" BU_SG_REL_ RadioHead_LE SG_ 2155233280 RtBsChrgCmplnTmPrfRsp 1;
BA_REL_ "GenSigSuprvResp" BU_SG_REL_ VCU_LE SG_ 2155233280 EngRnngDutoVehSpdIO 1;
BA_REL_ "GenSigSuprvResp" BU_SG_REL_ IPC_LE SG_ 2155233280 EngRnngDutoVehSpdIO 1;
BA_REL_ "GenSigSuprvResp" BU_SG_REL_ VCU_LE SG_ 2155233280 ChrgCyclFuelEcn 1;
BA_REL_ "GenSigSuprvResp" BU_SG_REL_ CSM_LE SG_ 2155233280 ChrgCyclFuelEcn 1;
BA_REL_ "GenSigSuprvResp" BU_SG_REL_ RadioHead_LE SG_ 2155233280 ChrgCyclFuelEcn 1;
BA_REL_ "GenSigSuprvResp" BU_SG_REL_ VCU_LE SG_ 2155233280 LiftimeFuelEcnEquiv 1;
BA_REL_ "GenSigSuprvResp" BU_SG_REL_ CSM_LE SG_ 2155233280 LiftimeFuelEcnEquiv 1;
BA_REL_ "GenSigSuprvResp" BU_SG_REL_ RadioHead_LE SG_ 2155233280 LiftimeFuelEcnEquiv 1;
BA_REL_ "GenSigSuprvResp" BU_SG_REL_ VCU_LE SG_ 2155233280 ShftPrkIO_3B2 1;
BA_REL_ "GenSigSuprvResp" BU_SG_REL_ IPC_LE SG_ 2155233280 ShftPrkIO_3B2 1;
BA_REL_ "GenSigSuprvResp" BU_SG_REL_ VCU_LE SG_ 2155233280 LftmFuelEcon 1;
BA_REL_ "GenSigSuprvResp" BU_SG_REL_ VCU_LE SG_ 2155233280 LftmFuelEcon 1;
BA_REL_ "GenSigSuprvResp" BU_SG_REL_ CSM_LE SG_ 2155233280 LftmFuelEcon 1;
BA_REL_ "GenSigSuprvResp" BU_SG_REL_ RadioHead_LE SG_ 2155233280 LftmFuelEcon 1;
BA_REL_ "GenSigSuprvResp" BU_SG_REL_ RadioHead_LE SG_ 2155233280 LftmFuelEcon 1;
BA_REL_ "GenSigSuprvResp" BU_SG_REL_ VCU_LE SG_ 2155233280 NtrlCstdwnCrtMdActvIO 1;
BA_REL_ "GenSigSuprvResp" BU_SG_REL_ IPC_LE SG_ 2155233280 NtrlCstdwnCrtMdActvIO 1;
BA_REL_ "GenSigSuprvResp" BU_SG_REL_ CSM_LE SG_ 2155364352 InstDrvEff 1;
BA_REL_ "GenSigSuprvResp" BU_SG_REL_ RadioHead_LE SG_ 2155364352 InstDrvEff 1;
BA_REL_ "GenSigSuprvResp" BU_SG_REL_ VCU_LE SG_ 2155364352 InstDrvEff 1;
BA_REL_ "GenSigSuprvResp" BU_SG_REL_ CSM_LE SG_ 2155364352 CstmrUsblSOC 1;
BA_REL_ "GenSigSuprvResp" BU_SG_REL_ RadioHead_LE SG_ 2155364352 CstmrUsblSOC 1;
BA_REL_ "GenSigSuprvResp" BU_SG_REL_ RadioHead_LE SG_ 2155364352 CstmrUsblSOC 1;
BA_REL_ "GenSigSuprvResp" BU_SG_REL_ VCU_LE SG_ 2155364352 CstmrUsblSOC 1;
BA_REL_ "GenSigSuprvResp" BU_SG_REL_ VCU_LE SG_ 2155364352 CstmrUsblSOC 1;
BA_REL_ "GenSigSuprvResp" BU_SG_REL_ VCU_LE SG_ 2155364352 CstmrUsblSOC 1;
BA_REL_ "GenSigSuprvResp" BU_SG_REL_ IPC_LE SG_ 2155364352 CstmrUsblSOC 1;
BA_REL_ "GenSigSuprvResp" BU_SG_REL_ CSM_LE SG_ 2155364352 HybMdDisp 1;
BA_REL_ "GenSigSuprvResp" BU_SG_REL_ IPC_LE SG_ 2155364352 HybMdDisp 1;
BA_REL_ "GenSigSuprvResp" BU_SG_REL_ VCU_LE SG_ 2155364352 HybMdDisp 1;
BA_REL_ "GenSigSuprvResp" BU_SG_REL_ VCU_LE SG_ 2155364352 HybMdDisp 1;
BA_REL_ "GenSigSuprvResp" BU_SG_REL_ RadioHead_LE SG_ 2155364352 HybMdDisp 1;
BA_REL_ "GenSigSuprvResp" BU_SG_REL_ RadioHead_LE SG_ 2155364352 HybMdDisp 1;
BA_REL_ "GenSigSuprvResp" BU_SG_REL_ VCU_LE SG_ 2155184128 TrnsShftLvrLckStat 1;
BA_REL_ "GenSigSuprvResp" BU_SG_REL_ CSM_LE SG_ 2155184128 TrnsShftLvrLckStat 1;
BA_REL_ "GenSigSuprvResp" BU_SG_REL_ RadioHead_LE SG_ 2155184128 TrnsShftLvrLckStat 1;
VAL_ 2154397696 CrShrngRvkCertfctRsp 4 "No CertIDs Stored" 3 "CertID Not Matched" 2 "Revoke Certificate Successful" 1 "Write Failure" 0 "No Action" ;
VAL_ 2154397696 CrShrngConnStat 3 "Terminate Connection" 2 "Ignore Connection" 1 "Valid Connection" 0 "No Action" ;
VAL_ 2154397696 CrShrngFbsEnblStat 3 "Fail" 2 "Enabled" 1 "Disabled" 0 "No Action" ;
VAL_ 2154397696 CSPS_ConnStat 15 "Reject All Certificates" 14 "Incorrect Fleet ID" 13 "Send Intermediate Certificate" 12 "Send User Certificate" 11 "Send all Authentication Data" 10 "Invalid VIN" 9 "Intermediate Certificate Expired" 8 "Invalid Intermediate Certificate" 7 "Resrvation End Time Exceeded " 6 "Resrvtion Start Tim Not Achieved" 5 "Cert Revoked Via Mobile Device" 4 "Cert Revoked Via Telematics" 3 "Certificate Expired" 2 "Invalid Certificate" 1 "Valid Certificate" 0 "No Action" ;
VAL_ 2154397696 CSPS_RspVerf 4 "Command Response Verification Not Successful" 3 "Command Response Verification Successful" 2 "Zone Response Verification Not Successful" 1 "Zone Response Verification Successful" 0 "No Action" ;
VAL_ 2154381312 CSZS_FrntCmptZnMbDevStat 1 "One Or More Mobile Devices Prsnt" 0 "No Mobile Device Present" ;
VAL_ 2154381312 CSZS_RrCmptZnMbDevStat 1 "One Or More Mobile Devices Prsnt" 0 "No Mobile Device Present" ;
VAL_ 2154381312 CSZS_FrntExtrZnMbDevStat 1 "One Or More Mobile Devices Prsnt" 0 "No Mobile Device Present" ;
VAL_ 2154381312 CSZS_RrExtrZnMbDevStat 1 "One Or More Mobile Devices Prsnt" 0 "No Mobile Device Present" ;
VAL_ 2154381312 CSZS_WlcmZnMbDevStat 1 "One Or More Mobile Devices Prsnt" 0 "No Mobile Device Present" ;
VAL_ 2154381312 CSZS_IntrZnMbDevStat 3 "Three Mobile Devices Present" 2 "Two Mobile Devices Present" 1 "One Mobile Device Present" 0 "No Mobile Device Present" ;
VAL_ 2154381312 CSZS_PassEntyZnMbDevStat 1 "One Or More Mobile Devices Prsnt" 0 "No Mobile Device Present" ;
VAL_ 2154381312 CSZS_DrEntyZnMbDevStat 1 "One Or More Mobile Devices Prsnt" 0 "No Mobile Device Present" ;
VAL_ 2150121472 RmtTrlrLtngSeqReq 2 "On" 1 "Off" 0 "No Action" ;
VAL_ 2150547456 OffBrdHVCVehPwrLvl 0 "None" 1 "Low" 2 "Medium" 3 "High" ;
VAL_ 2150547456 OffBrdHVCVehPwrDrtd 1 "true" 0 "false" ;
VAL_ 2150547456 OffBrdHVCVehCplrLkd 1 "true" 0 "false" ;
VAL_ 2150547456 OffBrdHVBlkChrgCmp 1 "true" 0 "false" ;
VAL_ 2150547456 ElecPrplsnMtrOvrSpdIO 1 "true" 0 "false" ;
VAL_ 2150547456 HVBatOutOfEnrgyInd 0 "No Action" 1 "Charge Vehicle Soon" 2 "Charge Vehicle Now" 3 "Out of Energy" ;
VAL_ 2150547456 CntrsOpnUndrTmpIO 1 "true" 0 "false" ;
VAL_ 2150547456 HVBatCntctrsOpnIO 1 "true" 0 "false" ;
VAL_ 2150547456 GrnAudQueReq 1 "true" 0 "false" ;
VAL_ 2150547456 SvcHybChrgSysIO 1 "true" 0 "false" ;
VAL_ 2150547456 HVChrgrSysStat 0 "Default" 1 "Idle" 2 "Initializing" 3 "Active" 4 "Complete" 5 "Aborted" ;
VAL_ 2150547456 HVChrgrCplrStat 0 "No Action" 1 "Disconnected" 2 "Connected" ;
VAL_ 2150547456 HVBatLimDTmpInd 0 "Normal" 1 "Cold" 2 "Hot" ;
VAL_ 2150547456 HVBatChrgCrdConnIO 1 "true" 0 "false" ;
VAL_ 2150547456 VehChrgMdSt 0 "Charge Depletion" 1 "Hold Charge Sustaining" 2 "Low SOC Charge Sustaining" ;
VAL_ 2150547456 ChgrSysAdblIndReq 0 "Inactive" 1 "Sequence 1" 2 "Sequence 2" 3 "Sequence 3" ;
VAL_ 2149752832 SndEnhcmtPerfMdRq 7 "Performance Mode 7" 6 "Performance Mode 6" 5 "Performance Mode 5" 4 "Performance Mode 4" 3 "Performance Mode 3" 2 "Performance Mode 2" 1 "Performance Mode 1" 0 "No Action" ;
VAL_ 2149752832 SndPerfMdCsStAvl 1 "true" 0 "false" ;
VAL_ 2149752832 SndPerfMdCsCrStVal 0 "No Action" 1 "Performance Mode 1" 2 "Performance Mode 2" 3 "Performance Mode 3" 4 "Performance Mode 4" 5 "Performance Mode 5" 6 "Performance Mode 6" 7 "Auto" ;
VAL_ 2149752832 DispPerfMdCsStAvl 1 "true" 0 "false" ;
VAL_ 2149752832 DispPerfMdCsCrStVal 0 "No Action" 1 "Performance Mode 1" 2 "Performance Mode 2" 3 "Performance Mode 3" 4 "Performance Mode 4" 5 "Performance Mode 5" 6 "Performance Mode 6" 7 "Auto" ;
VAL_ 2149752832 HlStrAssActIO 1 "true" 0 "false" ;
VAL_ 2149752832 GNCustSetngAvlbl 1 "true" 0 "false" ;
VAL_ 2149752832 GNCustCrntStngVal 0 "No Action" 1 "Off" 2 "On" ;
VAL_ 2149752832 CPSInfotmntMtReq 0 "No Mute" 1 "Unused and Reserved 1" 2 "Unused and Reserved 2" 3 "Mute" ;
VAL_ 2149752832 ColPrSysStngAvl 1 "true" 0 "false" ;
VAL_ 2149752832 ColPrSysCrntStng 4 "Alert and Brake and Steer" 0 "No Action" 1 "Off" 2 "Alert" 3 "Alert and Brake" ;
VAL_ 2149752832 HillDscntCntlSysStat 4 "Temporarily Inhibited" 3 "Failed" 2 "Active" 1 "Enabled" 0 "Normal" ;
VAL_ 2149752832 ElecPrkBrkStat 2 "Fault" 1 "Applied" 0 "Released" ;
VAL_ 2149752832 EBDFailed 1 "true" 0 "false" ;
VAL_ 2149752832 SusCustStngAvlbl 1 "true" 0 "false" ;
VAL_ 2149752832 SusCustCurrStngVal 7 "Auto" 6 "Performance Mode 6" 5 "Performance Mode 5" 4 "Performance Mode 4" 3 "Performance Mode 3" 0 "No Action" 1 "Performance Mode 1" 2 "Performance Mode 2" ;
VAL_ 2149752832 StrCustStngAvlbl 1 "true" 0 "false" ;
VAL_ 2149752832 StrCustCurrStngVal 7 "Auto" 6 "Performance Mode 6" 5 "Performance Mode 5" 4 "Performance Mode 4" 3 "Performance Mode 3" 0 "No Action" 1 "Performance Mode 1" 2 "Performance Mode 2" ;
VAL_ 2149752832 DrvlnCustStngAvlbl 1 "true" 0 "false" ;
VAL_ 2149752832 DrvlnCustCurrStngVal 7 "Auto" 6 "Performance Mode 6" 5 "Performance Mode 5" 4 "Performance Mode 4" 3 "Performance Mode 3" 0 "No Action" 1 "Performance Mode 1" 2 "Performance Mode 2" ;
VAL_ 2149752832 ABSAtv 1 "true" 0 "false" ;
VAL_ 2149752832 PowStVDA 1 "VirtualDeviceAvailable" 0 "VirtualDeviceUnavailable" ;
VAL_ 2149752832 RrDrCntVDA 1 "VirtualDeviceAvailable" 0 "VirtualDeviceUnavailable" ;
VAL_ 2149752832 SprTireSt 2 "Spare Detected" 1 "No Spare Detected" 0 "Undetermined" ;
VAL_ 2149752832 VehHghtStatV 1 "Invalid" 0 "Valid" ;
VAL_ 2149752832 VehHghtStat 4 "Maximum Height" 3 "Kneeling Height" 2 "Aerodynamic Height" 1 "Normal Design Ride Height" 0 "Unknown" ;
VAL_ 2149752832 BrkSysVDA 1 "VirtualDeviceAvailable" 0 "VirtualDeviceUnavailable" ;
VAL_ 2149752832 IntBrkAssPreFilReq 1 "true" 0 "false" ;
VAL_ 2149752832 EPBSysDspMsgReq 7 "Message #7" 6 "Message #6" 5 "Message #5" 4 "Message #4" 3 "Message #3" 2 "Message #2" 1 "Message #1" 0 "Off" ;
VAL_ 2149752832 EPBSysAudWarnReq 2 "Warning #2" 1 "Warning #1" 0 "Off" ;
VAL_ 2149752832 BksOvht 1 "true" 0 "false" ;
VAL_ 2149752832 BrkSysRedBrkTlltlReq 1 "true" 0 "false" ;
VAL_ 2149752832 HalfSysFail 1 "true" 0 "false" ;
VAL_ 2149752832 PrkBrkVDA 1 "VirtualDeviceAvailable" 0 "VirtualDeviceUnavailable" ;
VAL_ 2156216320 TxtTelephoneDevPr 1 "true" 0 "false" ;
VAL_ 2158002176 SrvcPrvdr 2 "Sirius" 1 "XM (company name)" 0 "Not Available" ;
VAL_ 2158002176 CurntStnServc 5 "Other" 4 "Unsubscribed" 3 "Promotion" 2 "Pay per Use" 1 "General Subscription" 0 "No Data" ;
VAL_ 2156838912 WSR_WiFiAssnStat 0 "No Action" 1 "Available" 2 "Service Set Identifier Request" 3 "Passphrase Request" 4 "Security Type Request" 5 "Encryption Request" 6 "All Request" ;
VAL_ 2156822528 WAPD_EncrptnType 0 "Open" 1 "AES (Advanced Encryption Standard)" 2 "TKIP (Temporal Key Integrity Protocol)" 3 "AES or TKIP" ;
VAL_ 2156822528 WAPD_SecurityType 3 "WPA2 (WiFi Protected Access 2)" 4 "IEEE802.1X (Institute of Electrical and Electronics Engineers)" 0 "Open" 1 "WEP (Wired Equivalent Privacy)" 2 "WPA (WiFi Protected Access)" ;
VAL_ 2156822528 WAPD_IHUWiFiEnStat 0 "Disabled" 1 "Enabled" ;
VAL_ 2149883904 BTPR_RspInfoAvail 1 "true" 0 "false" ;
VAL_ 2149883904 BTPR_RspStat 0 "No Action" 1 "Available" 2 "Bluetooth Address" 3 "Pairing PIN" 4 "Unused and Reserved" 5 "Delete Pairing Information" 6 "Enter Bluetooth Pairing Mode" ;
VAL_ 2151874560 RstVTDTmprDtctd 1 "Reset" 0 "No Action" ;
VAL_ 2151874560 RstIllDrIdDevDtctd 1 "Reset" 0 "No Action" ;
VAL_ 2151874560 RstDrIdDevLrnd 1 "Reset" 0 "No Action" ;
VAL_ 2151874560 ESEIC_EngImmbRq 1 "Immobilize" 0 "Do Not Immobilize" ;
VAL_ 2151383040 TreInfMonSysRstReq 1 "true" 0 "false" ;
VAL_ 2149900288 BTTethrngPrngReq 0 "No Action" 1 "Available" 2 "Bluetooth Address" 3 "Pairing PIN" 4 "Unused and Reserved" 5 "Delete Pairing Information" 6 "Enter Bluetooth Pairing Mode" ;
VAL_ 2149900288 EnhSrvAudAlRq 3 "Alarm" 2 "Chirp" 1 "Off" 0 "No Action" ;
VAL_ 2149900288 EnhSrvVisAlRq 3 "Repeated Flash" 2 "Single Flash" 1 "Off" 0 "No Action" ;
VAL_ 2149900288 EnhSrvRmStrtRq 2 "Engine Requested On" 1 "Engine Requested Off" 0 "No Activation" ;
VAL_ 2149900288 EnhSrvRClsRlsRq 1 "Release" 0 "No Action" ;
VAL_ 2149900288 EnhSrvLckRq 3 "Unlock All" 2 "Unlock Driver Door" 1 "Lock All" 0 "No Action" ;
VAL_ 2158985216 ODDMO_ReqType 0 "Subscribe: FU sends DynData back and then on change) " 1 "Unsubscribe: cancel previous Subscribe" ;
VAL_ 2158985216 ODDMO_DispMID 128 "Reserved" 64 "Reserved" 32 "OTIM" 16 "RearDisplayTwo" 8 "RearDisplayOne" 4 "AuxIP" 2 "CenterStack" 1 "IPC" ;
VAL_ 2158985216 ODDMO_DataID2Vld 1 "true" 0 "false" ;
VAL_ 2158985216 ODDMO_DataID3Vld 1 "true" 0 "false" ;
VAL_ 2158985216 ODDMO_DataID4Vld 1 "true" 0 "false" ;
VAL_ 2158985216 ODDMO_DataID5Vld 1 "true" 0 "false" ;
VAL_ 2158862336 ODIAOT_DspMID 128 "Reserved" 64 "Reserved" 32 "OTIM" 16 "RearDisplayTwo" 8 "RearDisplayOne" 4 "AuxIP" 2 "CenterStack" 1 "IPC" ;
VAL_ 2158862336 ODIAOT_DaTy 21 "Bitmap" 20 "DecimalShort" 19 "HoursOfDay" 18 "Character" 17 "Fuel Consumption Inverted" 16 "Fuel Consumption" 15 "Pressure" 14 "Temperature" 13 "Volume" 12 "DistanceShort" 11 "DistanceLong" 10 "BitmapId" 9 "TextId" 8 "Pictogram" 7 "List " 6 "Date" 5 "Time " 4 "Decimal" 3 "EnumerationValue" 2 "Integer" 1 "String" 0 "Speed" ;
VAL_ 2158886912 ODDLI_WrpArnd 1 "true" 0 "false" ;
VAL_ 2158886912 ODDLI_ReqType 0 "Subscribe: FU sends DynData back and then on change) " 1 "Unsubscribe: cancel previous Subscribe" ;
VAL_ 2158886912 ODDLI_ReqDir 1 "true" 0 "false" ;
VAL_ 2158886912 ODDLI_DspMID 128 "Reserved" 64 "Reserved" 32 "OTIM" 16 "RearDisplayTwo" 8 "RearDisplayOne" 4 "AuxIP" 2 "CenterStack" 1 "IPC" ;
VAL_ 2158886912 ODDLI_BckgndFlag 1 "Background response" 0 "Immediate response required" ;
VAL_ 2158854144 ODIAI_DaTy 21 "Bitmap" 20 "DecimalShort" 19 "HoursOfDay" 18 "Character" 17 "Fuel Consumption Inverted" 16 "Fuel Consumption" 15 "Pressure" 14 "Temperature" 13 "Volume" 12 "DistanceShort" 11 "DistanceLong" 10 "BitmapId" 9 "TextId" 8 "Pictogram" 7 "List " 6 "Date" 5 "Time " 4 "Decimal" 3 "EnumerationValue" 2 "Integer" 1 "String" 0 "Speed" ;
VAL_ 2158854144 ODIAI_DspMID 128 "Reserved" 64 "Reserved" 32 "OTIM" 16 "RearDisplayTwo" 8 "RearDisplayOne" 4 "AuxIP" 2 "CenterStack" 1 "IPC" ;
VAL_ 2158919680 ODDMI_ReqType 0 "Subscribe: FU sends DynData back and then on change) " 1 "Unsubscribe: cancel previous Subscribe" ;
VAL_ 2158919680 ODDMI_DispMID 128 "Reserved" 64 "Reserved" 32 "OTIM" 16 "RearDisplayTwo" 8 "RearDisplayOne" 4 "AuxIP" 2 "CenterStack" 1 "IPC" ;
VAL_ 2158919680 ODDMI_DataID2Vld 1 "true" 0 "false" ;
VAL_ 2158919680 ODDMI_DataID3Vld 1 "true" 0 "false" ;
VAL_ 2158919680 ODDMI_DataID4Vld 1 "true" 0 "false" ;
VAL_ 2158919680 ODDMI_DataID5Vld 1 "true" 0 "false" ;
VAL_ 2150023168 OffBrdVehImmbNot 0 "No Action" 1 "Immobilization State 1" 2 "Immobilization State 2" ;
VAL_ 2150023168 HVInvRatVltV 1 "Invalid" 0 "Valid" ;
VAL_ 2150023168 HybChrgMdStat 3 "Unused and reserved 2" 2 "Unused and reserved 1" 1 "Charge Sustaining" 0 "Charge Depleting" ;
VAL_ 2150285312 PsngSysHdingV 1 "Invalid" 0 "Valid" ;
VAL_ 2150285312 PsngSysElvtnV 1 "Invalid" 0 "Valid" ;
VAL_ 2150285312 PsngSysCalcSpdV 1 "Invalid" 0 "Valid" ;
VAL_ 2150285312 PsngSysDilPrcsV 1 "Invalid" 0 "Valid" ;
VAL_ 2150277120 PsngSysLongV 1 "Invalid" 0 "Valid" ;
VAL_ 2150277120 PsngSysLatV 1 "Invalid" 0 "Valid" ;
VAL_ 2156806144 SecCmpstdValV 1 "Invalid" 0 "Valid" ;
VAL_ 2156806144 MinsCmpstdValV 1 "Invalid" 0 "Valid" ;
VAL_ 2156806144 HrsCmpstdValV 1 "Invalid" 0 "Valid" ;
VAL_ 2156806144 CldrMthCmpstdVal 0 "Unknown" 1 "January" 2 "February" 3 "March" 4 "April" 5 "May" 6 "June" 7 "July" 8 "August" 9 "September" 10 "October" 11 "November" 12 "December" ;
VAL_ 2156806144 CellNtwrkDtTmAvl 1 "true" 0 "false" ;
VAL_ 2151514112 EngOilLfRstRq 1 "true" 0 "false" ;
VAL_ 2154561536 VehOdoV 1 "Invalid" 0 "Valid" ;
VAL_ 2155872256 DrvStyPerfMdCsCrStVal 7 "Performance Mode 7" 6 "Performance Mode 6" 5 "Performance Mode 5" 4 "Performance Mode 4" 3 "Performance Mode 3" 2 "Performance Mode 2" 1 "Performance Mode 1" 0 "No Action" ;
VAL_ 2155872256 DrvStyPerfMdCsStAvl 1 "true" 0 "false" ;
VAL_ 2155872256 VehPitchAngleV 1 "Invalid" 0 "Valid" ;
VAL_ 2155872256 RdWhlAngV 1 "Invalid" 0 "Valid" ;
VAL_ 2155872256 FuelFltChgNwIO 1 "true" 0 "false" ;
VAL_ 2155872256 FlLvlPctV 1 "Invalid" 0 "Valid" ;
VAL_ 2155872256 FlInjRlCtRstOcc 1 "true" 0 "false" ;
VAL_ 2151972864 VehFuelRngCalcV 1 "Invalid" 0 "Valid" ;
VAL_ 2151972864 FuelLvlLwIO 1 "true" 0 "false" ;
VAL_ 2151972864 LnchCtrlWhlSlpReq 31 "Unused and Reserved 10" 30 "Unused and Reserved 9" 29 "Unused and Reserved 8" 28 "Unused and Reserved 7" 27 "Unused and Reserved 6" 26 "Unused and Reserved 5" 25 "Unused and Reserved 4" 24 "Unused and Reserved 3" 23 "Unused and Reserved 2" 22 "Unused and Reserved 1" 21 "Fifteen Percent" 20 "Fourteen And A Half Percent" 19 "Fourteen Percent" 18 "Thirteen And A Half Percent" 17 "Thirteen Percent" 16 "Twelve And A Half Percent" 15 "Twelve Percent" 14 "Eleven And a Half Percent" 13 "Eleven Percent" 12 "Ten And A Half Percent" 11 "Ten Percent" 10 "Nine And A Half Percent" 9 "Nine Percent" 8 "Eight And A Half Percent" 7 "Eight Percent" 6 "Seven And A Half Percent" 5 "Seven Percent" 4 "Six And A Half Percent" 3 "Six Percent" 2 "Five And A Half Percent" 1 "Five Percent" 0 "No Action" ;
VAL_ 2151972864 LnchCtrlMdReq 3 "Burn Out" 2 "Custom" 1 "Automatic" 0 "No Action" ;
VAL_ 2151972864 LnchCtrlEngRPMReq 63 "Unused and Reserved 30" 62 "Unused and Reserved 29" 61 "Unused and Reserved 28" 60 "Unused and Reserved 27" 59 "Unused and Reserved 26" 58 "Unused and Reserved 25" 57 "Unused and Reserved 24" 56 "Unused and Reserved 23" 55 "Unused and Reserved 22" 54 "Unused and Reserved 21" 53 "Unused and Reserved 20" 52 "Unused and Reserved 19" 51 "Unused and Reserved 18" 50 "Unused and Reserved 17" 49 "Unused and Reserved 16" 48 "Unused and Reserved 15" 47 "Unused and Reserved 14" 46 "Unused and Reserved 13" 45 "Unused and Reserved 12" 44 "Unused and Reserved 11" 43 "Unused and Reserved 10" 42 "Unused and Reserved 9" 41 "Unused and Reserved 8" 40 "Unused and Reserved 7" 39 "Unused and Reserved 6" 38 "Unused and Reserved 5" 37 "Unused and Reserved 4" 36 "Unused and Reserved 3" 35 "Unused and Reserved 2" 34 "Unused and Reserved 1" 33 "4000" 32 "3900" 31 "3800" 30 "3700" 29 "3600" 28 "3500" 27 "3400" 26 "3300" 25 "3200" 24 "3100" 23 "3000" 22 "2900" 21 "2800" 20 "2700" 19 "2600" 18 "2500" 17 "2400" 16 "2300" 15 "2200" 14 "2100" 13 "2000" 12 "1900" 11 "1800" 10 "1700" 9 "1600" 8 "1500" 7 "1400" 6 "1300" 5 "1200" 4 "1100" 3 "1000" 2 "900" 1 "800" 0 "No Action" ;
VAL_ 2152095744 SPMCA_SusPrfMd6Avl 1 "true" 0 "false" ;
VAL_ 2152095744 SPMCA_SusPrfMd5Avl 1 "true" 0 "false" ;
VAL_ 2152095744 SPMCA_SusPrfMd4Avl 1 "true" 0 "false" ;
VAL_ 2152095744 SPMCA_SusPrfMd3Avl 1 "true" 0 "false" ;
VAL_ 2152095744 SPMCA_SusPrfMd2Avl 1 "true" 0 "false" ;
VAL_ 2152095744 SPMCA_SusPrfMd1Avl 1 "true" 0 "false" ;
VAL_ 2152095744 SPMCA_StrPrfMd6Avl 1 "true" 0 "false" ;
VAL_ 2152095744 SPMCA_StrPrfMd5Avl 1 "true" 0 "false" ;
VAL_ 2152095744 SPMCA_StrPrfMd4Avl 1 "true" 0 "false" ;
VAL_ 2152095744 SPMCA_StrPrfMd3Avl 1 "true" 0 "false" ;
VAL_ 2152095744 SPMCA_StrPrfMd2Avl 1 "true" 0 "false" ;
VAL_ 2152095744 SPMCA_StrPrfMd1Avl 1 "true" 0 "false" ;
VAL_ 2152095744 SPMCA_SndPrfMd6Avl 1 "true" 0 "false" ;
VAL_ 2152095744 SPMCA_SndPrfMd5Avl 1 "true" 0 "false" ;
VAL_ 2152095744 SPMCA_SndPrfMd4Avl 1 "true" 0 "false" ;
VAL_ 2152095744 SPMCA_SndPrfMd3Avl 1 "true" 0 "false" ;
VAL_ 2152095744 SPMCA_SndPrfMd2Avl 1 "true" 0 "false" ;
VAL_ 2152095744 SPMCA_SndPrfMd1Avl 1 "true" 0 "false" ;
VAL_ 2152095744 DPMCA_DispPrfMd6Avl 1 "true" 0 "false" ;
VAL_ 2152095744 DPMCA_DispPrfMd5Avl 1 "true" 0 "false" ;
VAL_ 2152095744 DPMCA_DispPrfMd4Avl 1 "true" 0 "false" ;
VAL_ 2152095744 DPMCA_DispPrfMd3Avl 1 "true" 0 "false" ;
VAL_ 2152095744 DPMCA_DispPrfMd2Avl 1 "true" 0 "false" ;
VAL_ 2152095744 DPMCA_DispPrfMd1Avl 1 "true" 0 "false" ;
VAL_ 2152095744 DPMCA_DrvlPrfMd6Avl 1 "true" 0 "false" ;
VAL_ 2152095744 DPMCA_DrvlPrfMd5Avl 1 "true" 0 "false" ;
VAL_ 2152095744 DPMCA_DrvlPrfMd4Avl 1 "true" 0 "false" ;
VAL_ 2152095744 DPMCA_DrvlPrfMd3Avl 1 "true" 0 "false" ;
VAL_ 2152095744 DPMCA_DrvlPrfMd2Avl 1 "true" 0 "false" ;
VAL_ 2152095744 DPMCA_DrvlPrfMd1Avl 1 "true" 0 "false" ;
VAL_ 2155479040 EleRngEstAdjCstStReq 3 "Unused and Reserved 1" 2 "On" 1 "Off" 0 "No Action" ;
VAL_ 2155479040 WPRSCstStReq 7 "Unused and Reserved 5" 6 "Unused and Reserved 4" 5 "Unused and Reserved 3" 4 "Unused and Reserved 2" 3 "Unused and Reserved 1" 2 "On" 1 "Off" 0 "No Action" ;
VAL_ 2155479040 DrvStyPerfMdCsStReq 7 "Performance Mode 7" 6 "Performance Mode 6" 5 "Performance Mode 5" 4 "Performance Mode 4" 3 "Performance Mode 3" 2 "Performance Mode 2" 1 "Performance Mode 1" 0 "No Action" ;
VAL_ 2155479040 PsngStPerfMdCsStReq 7 "Auto" 6 "Performance Mode 6" 5 "Performance Mode 5" 4 "Performance Mode 4" 3 "Performance Mode 3" 2 "Performance Mode 2" 1 "Performance Mode 1" 0 "No Action" ;
VAL_ 2155479040 DrvrStPerfMdCsStReq 7 "Auto" 6 "Performance Mode 6" 5 "Performance Mode 5" 4 "Performance Mode 4" 3 "Performance Mode 3" 2 "Performance Mode 2" 1 "Performance Mode 1" 0 "No Action" ;
VAL_ 2155479040 ACCPerfMdCsStReq 7 "Auto" 6 "Performance Mode 6" 5 "Performance Mode 5" 4 "Performance Mode 4" 3 "Performance Mode 3" 2 "Performance Mode 2" 1 "Performance Mode 1" 0 "No Action" ;
VAL_ 2155479040 ElvtdIdlCstStReq 0 "No Action" 1 "Off" 2 "On" ;
VAL_ 2155479040 PedFrndlyAlrtCsStReq 0 "No Action" 1 "Off" 2 "On" ;
VAL_ 2155479040 SndPerfMdCsStRq 0 "No Action" 1 "Performance Mode 1" 2 "Performance Mode 2" 3 "Performance Mode 3" 4 "Performance Mode 4" 5 "Performance Mode 5" 6 "Performance Mode 6" 7 "Auto" ;
VAL_ 2155479040 DispPerfMdCsStRq 0 "No Action" 1 "Performance Mode 1" 2 "Performance Mode 2" 3 "Performance Mode 3" 4 "Performance Mode 4" 5 "Performance Mode 5" 6 "Performance Mode 6" 7 "Auto" ;
VAL_ 2155479040 SusCustStngReq 7 "Auto" 6 "Performance Mode 6" 5 "Performance Mode 5" 4 "Performance Mode 4" 3 "Performance Mode 3" 2 "Performance Mode 2" 1 "Performance Mode 1" 0 "No Action" ;
VAL_ 2155479040 StrCustStngReq 7 "Auto" 6 "Performance Mode 6" 5 "Performance Mode 5" 4 "Performance Mode 4" 3 "Performance Mode 3" 2 "Performance Mode 2" 1 "Performance Mode 1" 0 "No Action" ;
VAL_ 2155479040 RstrCustFctrDef 1 "Restore Defaults" 0 "No Action" ;
VAL_ 2155479040 DrvlnCustStngReq 7 "Auto" 6 "Performance Mode 6" 5 "Performance Mode 5" 4 "Performance Mode 4" 3 "Performance Mode 3" 2 "Performance Mode 2" 1 "Performance Mode 1" 0 "No Action" ;
VAL_ 2155233280 InstnsFlEcnHybOvrdReq 7 "Unused and Reserved 3" 6 "Unused and Reserved 2" 5 "Unused and Reserved 1" 4 "EV" 3 "Auto Stop" 2 "Max Fuel Economy" 1 "Min Fuel Economy" 0 "No Action" ;
VAL_ 2155233280 NtrlGrWrngIO 1 "true" 0 "false" ;
VAL_ 2155233280 RtBsChrgCmplnTmPrfRsp 2 "Latest Possible" 1 "Earliest Possible" 0 "No Action" ;
VAL_ 2155233280 EngRnngDutoVehSpdIO 1 "true" 0 "false" ;
VAL_ 2155233280 ShftPrkIO_3B2 1 "true" 0 "false" ;
VAL_ 2155233280 FlDrOpenIndOn 1 "true" 0 "false" ;
VAL_ 2155233280 VehRefuelSt 7 "Unused and Reserved 4" 6 "Unused and Reserved 3" 5 "Unused and Reserved 2" 4 "Unused and Reserved 1" 3 "Close Fuel Door" 2 "Ready To Refuel" 1 "Wait To Refuel" 0 "Inactive" ;
VAL_ 2155233280 NtrlCstdwnCrtMdActvIO 1 "true" 0 "false" ;
VAL_ 2155233280 UtlChrgPopUpAct 1 "true" 0 "false" ;
VAL_ 2155233280 UtlChrgIntrfrIO 1 "true" 0 "false" ;
VAL_ 2155364352 CstmrUsblSOCV 1 "Invalid" 0 "Valid" ;
VAL_ 2155364352 BattCntrlPrcssrVDA 1 "VirtualDeviceAvailable" 0 "VirtualDeviceUnavailable" ;
VAL_ 2155364352 JmpStrtStat 0 "Inactive" 1 "In Progress" 2 "Complete" 3 "Power Mode" 4 "Disabled" ;
VAL_ 2155364352 SvcHybridSysIO 1 "true" 0 "false" ;
VAL_ 2155364352 HybMdDisp 15 "Engine Charging Battery While Idle" 14 "Engine Charging Battery Moving" 13 "Engine Power Load Sharing" 12 "Battery Power Load Sharing" 11 "Undetermined" 10 "Charging With Engine On" 9 "Charging With Engine Off" 8 "Hybrid Power 4WD" 7 "Hybrid Power 2WD" 6 "Engine Power 4WD" 5 "Engine Power 2WD" 4 "Battery Power 4WD" 3 "Battery Power 2WD" 2 "Auto Stop" 1 "Engine Idle" 0 "Default / Accessory" ;
VAL_ 2155184128 SmPhRmFunCstCurStVal 7 "Unused and Reserved 5" 6 "Unused and Reserved 4" 5 "Unused and Reserved 3" 4 "Unused and Reserved 2" 3 "Unused and Reserved 1" 2 "On" 1 "Off" 0 "No Action" ;
VAL_ 2155184128 SmPhRmFunCstStAval 1 "true" 0 "false" ;
VAL_ 2155184128 RrStRmndrIO 1 "true" 0 "false" ;
VAL_ 2155184128 RrStRmndrCstCurrSetVal 2 "On" 1 "Off" 0 "No Action" ;
VAL_ 2155184128 RrStRmndrCstSetAvail 1 "true" 0 "false" ;
VAL_ 2155184128 TrnsShftLvrLckStat 0 "Locked" 1 "Unlocked" ;
VAL_ 2155184128 CrsSpdLmtrSwStat 9 "Between Ranges" 8 "Short to Power" 7 "Open/Short to Ground" 6 "Cancel" 5 "Cruise On/Off" 4 "SL/SW On/Off/GAP" 3 "Set" 2 "Resume" 1 "No Activation" 0 "Indeterminate" ;
VAL_ 2155184128 CrsCntrlSwStCanSwAct 1 "true" 0 "false" ;
VAL_ 2155184128 CrsCntrlSwStSwDataIntgty 3 "Illegal Range" 2 "Failure Detected" 1 "Data Invalid" 0 "Data Valid" ;
VAL_ 2155184128 CrsCntrlSwStSpdInSwAct 1 "true" 0 "false" ;
VAL_ 2155184128 CrsCntrlSwStSpDcSwAct 1 "true" 0 "false" ;
VAL_ 2155184128 CrsCntrlSwStSetSwAct 1 "true" 0 "false" ;
VAL_ 2155184128 CrsCntrlSwStResSwAct 1 "true" 0 "false" ;
VAL_ 2155184128 CrsCntrlSwStOnSwAct 1 "true" 0 "false" ;
VAL_ 2155184128 CrsCntAtv 1 "true" 0 "false" ;
VAL_ 2155184128 IdlRecmndToClEngIO 1 "true" 0 "false" ;
SIG_GROUP_ 2154397696 CrShrngPhStat 1 : CSPS_CertfctId CSPS_ConnStat CSPS_RspVerf;
SIG_GROUP_ 2154381312 CrShrngZnStat 1 : CSZS_FrntCmptZnMbDevStat CSZS_RrCmptZnMbDevStat CSZS_FrntExtrZnMbDevStat CSZS_RrExtrZnMbDevStat CSZS_WlcmZnMbDevStat CSZS_IntrZnMbDevStat CSZS_PassEntyZnMbDevStat CSZS_DrEntyZnMbDevStat;
SIG_GROUP_ 2150547456 OffBrdHVBlkChgCpltTm 1 : OBHVBCCT_MinofHr OBHVBCCT_HrofDay OBHVBCCT_DayofWk;
SIG_GROUP_ 2156838912 WiFiStationResp 1 : WSR_WiFiStnMACAddr WSR_WiFiAssnStat;
SIG_GROUP_ 2156822528 WiFiAccsPntData 1 : WAPD_EncrptnType WAPD_SecurityType WAPD_IHUWiFiEnStat;
SIG_GROUP_ 2149883904 BTTethrngPrngRsp 1 : BTPR_RspVal BTPR_RspInfoAvail BTPR_RspStat;
SIG_GROUP_ 2151874560 EhnSrvEngImmbCom 1 : ESEIC_EngImRqPsw ESEIC_EngImmbRq;
SIG_GROUP_ 2158985216 ODIDynDataMltRq_OTIM 1 : ODDMO_ReqType ODDMO_FUCID ODDMO_DispMID ODDMO_DataID2Vld ODDMO_DataID2 ODDMO_DataID3Vld ODDMO_DataID3 ODDMO_DataID1 ODDMO_DataID4Vld ODDMO_DataID4 ODDMO_DataID5Vld ODDMO_DataID5;
SIG_GROUP_ 2158862336 ODIActn_OTIM 1 : ODIAOT_FUCID ODIAOT_DspMID ODIAOT_DaTy ODIAOT_ActnVal ODIAOT_ActnID;
SIG_GROUP_ 2158886912 ODIDynDataLstRq_IPC 1 : ODDLI_SubIdReqM ODDLI_WrpArnd ODDLI_ReqType ODDLI_ReqDir ODDLI_NmEntries ODDLI_Idx ODDLI_FUCID ODDLI_DspMID ODDLI_DataId ODDLI_BckgndFlag;
SIG_GROUP_ 2158854144 ODIActn_IPC 1 : ODIAI_DaTy ODIAI_FUCID ODIAI_DspMID ODIAI_ActnVal ODIAI_ActnID;
SIG_GROUP_ 2158919680 ODIDynDataMltRq_IPC 1 : ODDMI_ReqType ODDMI_FUCID ODDMI_DispMID ODDMI_DataID2Vld ODDMI_DataID2 ODDMI_DataID3Vld ODDMI_DataID3 ODDMI_DataID1 ODDMI_DataID4Vld ODDMI_DataID4 ODDMI_DataID5Vld ODDMI_DataID5;
SIG_GROUP_ 2152095744 SusPerfMdCustAvl 1 : SPMCA_SusPrfMd6Avl SPMCA_SusPrfMd5Avl SPMCA_SusPrfMd4Avl SPMCA_SusPrfMd3Avl SPMCA_SusPrfMd2Avl SPMCA_SusPrfMd1Avl;
SIG_GROUP_ 2152095744 StrPerfMdCustAvl 1 : SPMCA_StrPrfMd6Avl SPMCA_StrPrfMd5Avl SPMCA_StrPrfMd4Avl SPMCA_StrPrfMd3Avl SPMCA_StrPrfMd2Avl SPMCA_StrPrfMd1Avl;
SIG_GROUP_ 2152095744 SndPerfMdCustAvl 1 : SPMCA_SndPrfMd6Avl SPMCA_SndPrfMd5Avl SPMCA_SndPrfMd4Avl SPMCA_SndPrfMd3Avl SPMCA_SndPrfMd2Avl SPMCA_SndPrfMd1Avl;
SIG_GROUP_ 2152095744 DispPerfCustMdAvl 1 : DPMCA_DispPrfMd6Avl DPMCA_DispPrfMd5Avl DPMCA_DispPrfMd4Avl DPMCA_DispPrfMd3Avl DPMCA_DispPrfMd2Avl DPMCA_DispPrfMd1Avl;
SIG_GROUP_ 2152095744 DrvlnPerfMdCustAvl 1 : DPMCA_DrvlPrfMd6Avl DPMCA_DrvlPrfMd5Avl DPMCA_DrvlPrfMd4Avl DPMCA_DrvlPrfMd3Avl DPMCA_DrvlPrfMd2Avl DPMCA_DrvlPrfMd1Avl;
SIG_GROUP_ 2151981056 DstTrvldDt 1 : DTD_FuelPrpDstTrvld DTD_DrvCyclDstTrvld DTD_BattPrpDstTrvld;
SIG_GROUP_ 2155184128 CrsCntrlSwStat 1 : CrsCntrlSwStCanSwAct CrsCntrlSwStSwDataIntgty CrsCntrlSwStSpdInSwAct CrsCntrlSwStSpDcSwAct CrsCntrlSwStSetSwAct CrsCntrlSwStResSwAct CrsCntrlSwStOnSwAct;
